VERSION "HNNBNNNYNNNNNNNNNNNNNNNNNNNNNNNNNNNNNNNNNN/4/%%%/4/'%**4NNN///"

NS_ :

BS_:

BU_: BAP_Tester FASFrontradar ICAS1_X_Gateway MFK MFK120 MIK MRR2023 NR_1 NR_2

BO_ 2331595780 NR_FL_Object_09_10: 64 NR_1
 SG_ NR_FL_Object_09_10_CRC : 0|8@1+ (1,0) [0|255] ""  ICAS1_X_Gateway,MRR2023
 SG_ NR_FL_Object_09_10_BZ : 8|4@1+ (1,0) [0|15] ""  ICAS1_X_Gateway,MRR2023
 SG_ NR_FL_Object_09_10_BlockID_01 : 12|4@1+ (1,0) [0|15] "Unit_None"  ICAS1_X_Gateway,MRR2023
 SG_ NR_FL_Object_09_ID : 16|8@1+ (1,0) [1|254] "Unit_None"  ICAS1_X_Gateway,MRR2023
 SG_ NR_FL_Object_09_ReferencePoint : 24|4@1+ (1.0,0.0) [0.0|15] ""  ICAS1_X_Gateway,MRR2023
 SG_ NR_FL_Object_09_PosX : 28|14@1+ (0.03125,-200) [-200.00000|311.93750] "Unit_Meter"  ICAS1_X_Gateway,MRR2023
 SG_ NR_FL_Object_09_PosXSD : 42|8@1+ (0.03125,0) [0.00000|7.93750] "Unit_Meter"  ICAS1_X_Gateway,MRR2023
 SG_ NR_FL_Object_09_PosY : 50|13@1+ (0.03125,-128) [-128.00000|127.93750] "Unit_Meter"  ICAS1_X_Gateway,MRR2023
 SG_ NR_FL_Object_09_PosYSD : 63|8@1+ (0.03125,0) [0.00000|7.93750] "Unit_Meter"  ICAS1_X_Gateway,MRR2023
 SG_ NR_FL_Object_09_vAbsX : 71|12@1+ (0.0625,-128) [-128.0000|127.8750] "Unit_MeterPerSecon"  ICAS1_X_Gateway,MRR2023
 SG_ NR_FL_Object_09_vAbsXSD : 83|6@1+ (0.0625,0) [0.0000|3.8750] "Unit_MeterPerSecon"  ICAS1_X_Gateway,MRR2023
 SG_ NR_FL_Object_09_vAbsY : 89|12@1+ (0.0625,-128) [-128.0000|127.8750] "Unit_MeterPerSecon"  ICAS1_X_Gateway,MRR2023
 SG_ NR_FL_Object_09_vAbsYSD : 101|6@1+ (0.0625,0) [0.0000|3.8750] "Unit_MeterPerSecon"  ICAS1_X_Gateway,MRR2023
 SG_ NR_FL_Object_09_aAbsX : 107|9@1+ (0.0625,-16) [-16.0000|15.8750] "Unit_MeterPerSeconSquar"  ICAS1_X_Gateway,MRR2023
 SG_ NR_FL_Object_09_aAbsXSD : 116|6@1+ (0.0625,0) [0.0000|3.8750] "Unit_MeterPerSeconSquar"  ICAS1_X_Gateway,MRR2023
 SG_ NR_FL_Object_09_aAbsY : 122|9@1+ (0.0625,-16) [-16.0000|15.8750] "Unit_MeterPerSeconSquar"  ICAS1_X_Gateway,MRR2023
 SG_ NR_FL_Object_09_aAbsYSD : 131|6@1+ (0.0625,0) [0.0000|3.8750] "Unit_MeterPerSeconSquar"  ICAS1_X_Gateway,MRR2023
 SG_ NR_FL_Object_09_DynamicState : 137|2@1+ (1.0,0.0) [0.0|3] ""  ICAS1_X_Gateway,MRR2023
 SG_ NR_FL_Object_09_YawAngle : 139|12@1+ (0.001953125,-4) [-4.000000000|3.996093750] "Unit_Radia"  ICAS1_X_Gateway,MRR2023
 SG_ NR_FL_Object_09_YawAngleSD : 151|9@1+ (0.001953125,0) [0E-9|0.996093750] "Unit_Radia"  ICAS1_X_Gateway,MRR2023
 SG_ NR_FL_Object_09_Width : 160|8@1+ (0.03125,0) [0.00000|7.93750] "Unit_Meter"  ICAS1_X_Gateway,MRR2023
 SG_ NR_FL_Object_09_WidthSD : 168|7@1+ (0.03125,0) [0.00000|3.93750] "Unit_Meter"  ICAS1_X_Gateway,MRR2023
 SG_ NR_FL_Object_09_Length : 175|10@1+ (0.03125,0) [0.00000|31.93750] "Unit_Meter"  ICAS1_X_Gateway,MRR2023
 SG_ NR_FL_Object_09_LengthSD : 185|7@1+ (0.03125,0) [0.00000|3.93750] "Unit_Meter"  ICAS1_X_Gateway,MRR2023
 SG_ NR_FL_Object_09_Class : 192|4@1+ (1.0,0.0) [0.0|15] ""  ICAS1_X_Gateway,MRR2023
 SG_ NR_FL_Object_09_ClassPlausib : 196|4@1+ (0.0714285714,0) [0E-10|0.9999999996] "Unit_None"  ICAS1_X_Gateway,MRR2023
 SG_ NR_FL_Object_09_ExistProb : 200|7@1+ (0.0078125,0.015625) [0.0156250|1.0000000] "Unit_None"  ICAS1_X_Gateway,MRR2023
 SG_ NR_FL_Object_09_Age : 207|7@1+ (1,0) [0|126] "Unit_None"  ICAS1_X_Gateway,MRR2023
 SG_ NR_FL_Object_09_YawRateAbs : 214|12@1+ (0.001953125,-4) [-4.000000000|3.996093750] "Unit_RadiaPerSecon"  ICAS1_X_Gateway,MRR2023
 SG_ NR_FL_Object_09_YawRateAbsSD : 226|6@1+ (0.003906,0) [0.000000|0.242172] "Unit_RadiaPerSecon"  ICAS1_X_Gateway,MRR2023
 SG_ NR_FL_Object_09_MeasurementState : 232|1@1+ (1.0,0.0) [0.0|1] ""  ICAS1_X_Gateway,MRR2023
 SG_ NR_FL_Object_10_ID : 233|8@1+ (1,0) [1|254] "Unit_None"  ICAS1_X_Gateway,MRR2023
 SG_ NR_FL_Object_10_ReferencePoint : 241|4@1+ (1.0,0.0) [0.0|15] ""  ICAS1_X_Gateway,MRR2023
 SG_ NR_FL_Object_10_PosX : 245|14@1+ (0.03125,-200) [-200.00000|311.93750] "Unit_Meter"  ICAS1_X_Gateway,MRR2023
 SG_ NR_FL_Object_10_PosXSD : 259|8@1+ (0.03125,0) [0.00000|7.93750] "Unit_Meter"  ICAS1_X_Gateway,MRR2023
 SG_ NR_FL_Object_10_PosY : 267|13@1+ (0.03125,-128) [-128.00000|127.93750] "Unit_Meter"  ICAS1_X_Gateway,MRR2023
 SG_ NR_FL_Object_10_PosYSD : 280|8@1+ (0.03125,0) [0.00000|7.93750] "Unit_Meter"  ICAS1_X_Gateway,MRR2023
 SG_ NR_FL_Object_10_vAbsX : 288|12@1+ (0.0625,-128) [-128.0000|127.8750] "Unit_MeterPerSecon"  ICAS1_X_Gateway,MRR2023
 SG_ NR_FL_Object_10_vAbsXSD : 300|6@1+ (0.0625,0) [0.0000|3.8750] "Unit_MeterPerSecon"  ICAS1_X_Gateway,MRR2023
 SG_ NR_FL_Object_10_vAbsY : 306|12@1+ (0.0625,-128) [-128.0000|127.8750] "Unit_MeterPerSecon"  ICAS1_X_Gateway,MRR2023
 SG_ NR_FL_Object_10_vAbsYSD : 318|6@1+ (0.0625,0) [0.0000|3.8750] "Unit_MeterPerSecon"  ICAS1_X_Gateway,MRR2023
 SG_ NR_FL_Object_10_aAbsX : 324|9@1+ (0.0625,-16) [-16.0000|15.8750] "Unit_MeterPerSeconSquar"  ICAS1_X_Gateway,MRR2023
 SG_ NR_FL_Object_10_aAbsXSD : 333|6@1+ (0.0625,0) [0.0000|3.8750] "Unit_MeterPerSeconSquar"  ICAS1_X_Gateway,MRR2023
 SG_ NR_FL_Object_10_aAbsY : 339|9@1+ (0.0625,-16) [-16.0000|15.8750] "Unit_MeterPerSeconSquar"  ICAS1_X_Gateway,MRR2023
 SG_ NR_FL_Object_10_aAbsYSD : 348|6@1+ (0.0625,0) [0.0000|3.8750] "Unit_MeterPerSeconSquar"  ICAS1_X_Gateway,MRR2023
 SG_ NR_FL_Object_10_DynamicState : 354|2@1+ (1.0,0.0) [0.0|3] ""  ICAS1_X_Gateway,MRR2023
 SG_ NR_FL_Object_10_YawAngle : 356|12@1+ (0.001953125,-4) [-4.000000000|3.996093750] "Unit_Radia"  ICAS1_X_Gateway,MRR2023
 SG_ NR_FL_Object_10_YawAngleSD : 368|9@1+ (0.001953125,0) [0E-9|0.996093750] "Unit_Radia"  ICAS1_X_Gateway,MRR2023
 SG_ NR_FL_Object_10_Width : 377|8@1+ (0.03125,0) [0.00000|7.93750] "Unit_Meter"  ICAS1_X_Gateway,MRR2023
 SG_ NR_FL_Object_10_WidthSD : 385|7@1+ (0.03125,0) [0.00000|3.93750] "Unit_Meter"  ICAS1_X_Gateway,MRR2023
 SG_ NR_FL_Object_10_Length : 392|10@1+ (0.03125,0) [0.00000|31.93750] "Unit_Meter"  ICAS1_X_Gateway,MRR2023
 SG_ NR_FL_Object_10_LengthSD : 402|7@1+ (0.03125,0) [0.00000|3.93750] "Unit_Meter"  ICAS1_X_Gateway,MRR2023
 SG_ NR_FL_Object_10_Class : 409|4@1+ (1.0,0.0) [0.0|15] ""  ICAS1_X_Gateway,MRR2023
 SG_ NR_FL_Object_10_ClassPlausib : 413|4@1+ (0.0714285714,0) [0E-10|0.9999999996] "Unit_None"  ICAS1_X_Gateway,MRR2023
 SG_ NR_FL_Object_10_ExistProb : 417|7@1+ (0.0078125,0.015625) [0.0156250|1.0000000] "Unit_None"  ICAS1_X_Gateway,MRR2023
 SG_ NR_FL_Object_10_Age : 424|7@1+ (1,0) [0|126] "Unit_None"  ICAS1_X_Gateway,MRR2023
 SG_ NR_FL_Object_10_YawRateAbs : 431|12@1+ (0.001953125,-4) [-4.000000000|3.996093750] "Unit_RadiaPerSecon"  ICAS1_X_Gateway,MRR2023
 SG_ NR_FL_Object_10_YawRateAbsSD : 443|6@1+ (0.003906,0) [0.000000|0.242172] "Unit_RadiaPerSecon"  ICAS1_X_Gateway,MRR2023
 SG_ NR_FL_Object_10_MeasurementState : 449|1@1+ (1.0,0.0) [0.0|1] ""  ICAS1_X_Gateway,MRR2023
 SG_ SOK_NR_FL_Object_09_10_Signatur : 480|32@1+ (1,0) [0|4294967295] ""  ICAS1_X_Gateway

BO_ 2589284096 NR_FL_SensorHeader: 24 NR_1
 SG_ NR_FL_HW_Version : 12|32@1+ (1,0) [0|4294967295] "Unit_None"  ICAS1_X_Gateway,MRR2023
 SG_ NR_FL_SW_Version : 44|32@1+ (1,0) [0|4294967295] "Unit_None"  ICAS1_X_Gateway,MRR2023
 SG_ NR_FL_SerialNumber : 76|32@1+ (1,0) [0|4294967295] "Unit_None"  ICAS1_X_Gateway,MRR2023
 SG_ DS_FL_StructureVersion_1 : 108|32@1+ (1,0) [0|4294967295] "Unit_None"  ICAS1_X_Gateway
 SG_ DS_FL_StructureVersion_2 : 140|32@1+ (1,0) [0|4294967295] "Unit_None"  ICAS1_X_Gateway

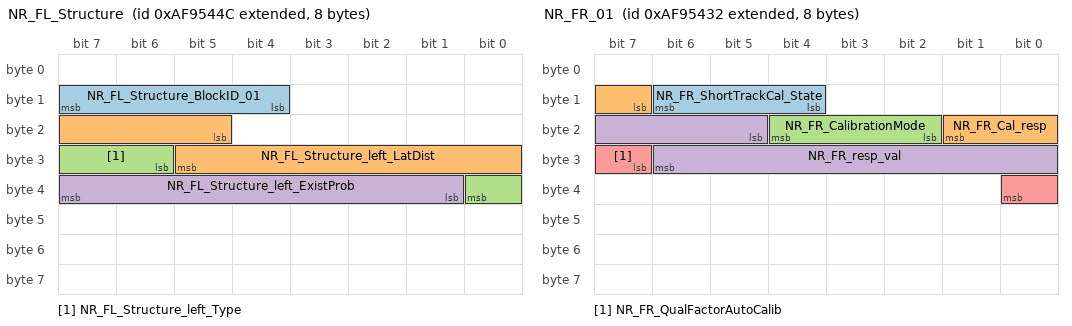
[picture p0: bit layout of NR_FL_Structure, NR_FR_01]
BO_ 2331595852 NR_FL_Structure: 8 NR_1
 SG_ NR_FL_Structure_BlockID_01 : 12|4@1+ (1,0) [0|15] "Unit_None"  ICAS1_X_Gateway,MRR2023
 SG_ NR_FL_Structure_left_LatDist : 21|9@1+ (0.03125,0) [0.00000|15.93750] "Unit_Meter"  ICAS1_X_Gateway,MRR2023
 SG_ NR_FL_Structure_left_Type : 30|3@1+ (1.0,0.0) [0.0|7] ""  ICAS1_X_Gateway,MRR2023
 SG_ NR_FL_Structure_left_ExistProb : 33|7@1+ (0.0078125,0.015625) [0.0156250|1.0000000] "Unit_None"  ICAS1_X_Gateway,MRR2023

BO_ 2264486976 NR_FL_Sync: 8 NR_1
 SG_ NR_FL_SyncCounter : 12|16@1+ (1,0) [0|65535] "Unit_None"  ICAS1_X_Gateway,MRR2023
 SG_ NR_FL_SyncVersion : 28|8@1+ (1,0) [0|255] "Unit_None"  ICAS1_X_Gateway,MRR2023

BO_ 2264486980 NR_FL_Sync_FollowUp: 20 NR_1
 SG_ NR_FL_CounterValue : 12|16@1+ (1,0) [0|65535] "Unit_None"  ICAS1_X_Gateway,MRR2023
 SG_ NR_FL_Time_LowPrecision : 28|32@1+ (1,0) [0|4294967295] "Unit_None"  ICAS1_X_Gateway,MRR2023
 SG_ NR_FL_Time_HighPrecision : 60|32@1+ (1,0) [0|4294967295] "Unit_None"  ICAS1_X_Gateway,MRR2023
 SG_ NR_FL_Time_CorrectionField : 92|32@1+ (1,0) [0|4294967295] "Unit_None"  ICAS1_X_Gateway,MRR2023
 SG_ NR_FL_RandomSeed : 124|16@1+ (1,0) [0|65535] "Unit_None"  ICAS1_X_Gateway,MRR2023

BO_ 2264486985 NR_FL_SyncReady: 16 NR_1
 SG_ NR_FL_SyncReadyVersion : 12|8@1+ (1,0) [0|255] "Unit_None"  ICAS1_X_Gateway,MRR2023
 SG_ NR_FL_EarliestStartTime : 20|32@1+ (1,0) [0|4294967295] "Unit_None"  ICAS1_X_Gateway,MRR2023
 SG_ NR_FL_RequestedModulation : 52|4@1+ (1,0) [0|15] "Unit_None"  ICAS1_X_Gateway,MRR2023
 SG_ NR_FL_InteferenceInfo : 56|16@1+ (1,0) [0|65535] "Unit_None"  ICAS1_X_Gateway,MRR2023
 SG_ NR_FL_SyncCycleCount : 74|32@1+ (1,0) [0|4294967295] "Unit_None"  ICAS1_X_Gateway,MRR2023
 SG_ NR_FL_LatestSyncCounter : 106|4@1+ (1,0) [0|15] "Unit_None"  ICAS1_X_Gateway,MRR2023

BO_ 2331595826 NR_FR_01: 8 NR_2
 SG_ NR_FR_ShortTrackCal_State : 12|3@1+ (1.0,0.0) [0.0|7] ""  ICAS1_X_Gateway,MRR2023
 SG_ NR_FR_Cal_resp : 15|3@1+ (1.0,0.0) [0.0|7] ""  ICAS1_X_Gateway,MRR2023
 SG_ NR_FR_CalibrationMode : 18|3@1+ (1.0,0.0) [0.0|7] ""  ICAS1_X_Gateway,MRR2023
 SG_ NR_FR_resp_val : 21|10@1+ (0.01,-5) [-5.00|5.00] "Unit_DegreOfArc"  ICAS1_X_Gateway,MRR2023
 SG_ NR_FR_QualFactorAutoCalib : 31|2@1+ (1.0,0.0) [0.0|3] ""  ICAS1_X_Gateway,MRR2023

BO_ 2331595791 NR_FR_Contour: 64 NR_2
 SG_ NR_FR_Contour_CRC : 0|8@1+ (1,0) [0|255] ""  ICAS1_X_Gateway,MRR2023
 SG_ NR_FR_Contour_BZ : 8|4@1+ (1,0) [0|15] ""  ICAS1_X_Gateway,MRR2023
 SG_ NR_FR_Contour_BlockID_02 : 12|4@1+ (1,0) [0|15] "Unit_None"  ICAS1_X_Gateway,MRR2023
 SG_ NR_FR_Contour_right_01_x01 : 16|13@1+ (0.0625,-256) [-256.0000|255.8750] "Unit_Meter"  ICAS1_X_Gateway,MRR2023
 SG_ NR_FR_Contour_right_01_y01 : 29|11@1+ (0.0625,-64) [-64.0000|63.8750] "Unit_Meter"  ICAS1_X_Gateway,MRR2023
 SG_ NR_FR_Contour_right_01_x02 : 40|13@1+ (0.0625,-256) [-256.0000|255.8750] "Unit_Meter"  ICAS1_X_Gateway,MRR2023
 SG_ NR_FR_Contour_right_01_y02 : 53|11@1+ (0.0625,-64) [-64.0000|63.8750] "Unit_Meter"  ICAS1_X_Gateway,MRR2023
 SG_ NR_FR_Contour_right_01_x03 : 64|13@1+ (0.0625,-256) [-256.0000|255.8750] "Unit_Meter"  ICAS1_X_Gateway,MRR2023
 SG_ NR_FR_Contour_right_01_y03 : 77|11@1+ (0.0625,-64) [-64.0000|63.8750] "Unit_Meter"  ICAS1_X_Gateway,MRR2023
 SG_ NR_FR_Contour_right_01_x04 : 88|13@1+ (0.0625,-256) [-256.0000|255.8750] "Unit_Meter"  ICAS1_X_Gateway,MRR2023
 SG_ NR_FR_Contour_right_01_y04 : 101|11@1+ (0.0625,-64) [-64.0000|63.8750] "Unit_Meter"  ICAS1_X_Gateway,MRR2023
 SG_ NR_FR_Contour_right_01_x05 : 112|13@1+ (0.0625,-256) [-256.0000|255.8750] "Unit_Meter"  ICAS1_X_Gateway,MRR2023
 SG_ NR_FR_Contour_right_01_y05 : 125|11@1+ (0.0625,-64) [-64.0000|63.8750] "Unit_Meter"  ICAS1_X_Gateway,MRR2023
 SG_ NR_FR_Contour_right_01_x06 : 136|13@1+ (0.0625,-256) [-256.0000|255.8750] "Unit_Meter"  ICAS1_X_Gateway,MRR2023
 SG_ NR_FR_Contour_right_01_y06 : 149|11@1+ (0.0625,-64) [-64.0000|63.8750] "Unit_Meter"  ICAS1_X_Gateway,MRR2023
 SG_ NR_FR_Contour_right_01_x07 : 160|13@1+ (0.0625,-256) [-256.0000|255.8750] "Unit_Meter"  ICAS1_X_Gateway,MRR2023
 SG_ NR_FR_Contour_right_01_y07 : 173|11@1+ (0.0625,-64) [-64.0000|63.8750] "Unit_Meter"  ICAS1_X_Gateway,MRR2023
 SG_ NR_FR_Contour_right_01_Type : 184|3@1+ (1.0,0.0) [0.0|7] ""  ICAS1_X_Gateway,MRR2023
 SG_ NR_FR_Contour_right_01_Age : 187|7@1+ (1,0) [0|126] "Unit_None"  ICAS1_X_Gateway,MRR2023
 SG_ NR_FR_Contour_right_02_x01 : 194|13@1+ (0.0625,-256) [-256.0000|255.8750] "Unit_Meter"  ICAS1_X_Gateway,MRR2023
 SG_ NR_FR_Contour_right_02_y01 : 207|11@1+ (0.0625,-64) [-64.0000|63.8750] "Unit_Meter"  ICAS1_X_Gateway,MRR2023
 SG_ NR_FR_Contour_right_02_x02 : 218|13@1+ (0.0625,-256) [-256.0000|255.8750] "Unit_Meter"  ICAS1_X_Gateway,MRR2023
 SG_ NR_FR_Contour_right_02_y02 : 231|11@1+ (0.0625,-64) [-64.0000|63.8750] "Unit_Meter"  ICAS1_X_Gateway,MRR2023
 SG_ NR_FR_Contour_right_02_x03 : 242|13@1+ (0.0625,-256) [-256.0000|255.8750] "Unit_Meter"  ICAS1_X_Gateway,MRR2023
 SG_ NR_FR_Contour_right_02_y03 : 255|11@1+ (0.0625,-64) [-64.0000|63.8750] "Unit_Meter"  ICAS1_X_Gateway,MRR2023
 SG_ NR_FR_Contour_right_02_x04 : 266|13@1+ (0.0625,-256) [-256.0000|255.8750] "Unit_Meter"  ICAS1_X_Gateway,MRR2023
 SG_ NR_FR_Contour_right_02_y04 : 279|11@1+ (0.0625,-64) [-64.0000|63.8750] "Unit_Meter"  ICAS1_X_Gateway,MRR2023
 SG_ NR_FR_Contour_right_02_x05 : 290|13@1+ (0.0625,-256) [-256.0000|255.8750] "Unit_Meter"  ICAS1_X_Gateway,MRR2023
 SG_ NR_FR_Contour_right_02_y05 : 303|11@1+ (0.0625,-64) [-64.0000|63.8750] "Unit_Meter"  ICAS1_X_Gateway,MRR2023
 SG_ NR_FR_Contour_right_02_x06 : 314|13@1+ (0.0625,-256) [-256.0000|255.8750] "Unit_Meter"  ICAS1_X_Gateway,MRR2023
 SG_ NR_FR_Contour_right_02_y06 : 327|11@1+ (0.0625,-64) [-64.0000|63.8750] "Unit_Meter"  ICAS1_X_Gateway,MRR2023
 SG_ NR_FR_Contour_right_02_x07 : 338|13@1+ (0.0625,-256) [-256.0000|255.8750] "Unit_Meter"  ICAS1_X_Gateway,MRR2023
 SG_ NR_FR_Contour_right_02_y07 : 351|11@1+ (0.0625,-64) [-64.0000|63.8750] "Unit_Meter"  ICAS1_X_Gateway,MRR2023
 SG_ NR_FR_Contour_right_02_Type : 362|3@1+ (1.0,0.0) [0.0|7] ""  ICAS1_X_Gateway,MRR2023
 SG_ NR_FR_Contour_right_02_Age : 365|7@1+ (1,0) [0|126] "Unit_None"  ICAS1_X_Gateway,MRR2023
 SG_ NR_FR_Contour_right_Linkage : 372|1@1+ (1.0,0.0) [0.0|1] ""  ICAS1_X_Gateway,MRR2023
 SG_ SOK_NR_FR_Contour_Signatur : 480|32@1+ (1,0) [0|4294967295] ""  ICAS1_X_Gateway

BO_ 2331595782 NR_FR_Header: 20 NR_2
 SG_ NR_FR_Header_CRC : 0|8@1+ (1,0) [0|255] ""  ICAS1_X_Gateway,MRR2023
 SG_ NR_FR_Header_BZ : 8|4@1+ (1,0) [0|15] ""  ICAS1_X_Gateway,MRR2023
 SG_ NR_FR_BlockID_02 : 12|4@1+ (1,0) [0|15] "Unit_None"  ICAS1_X_Gateway,MRR2023
 SG_ NR_FR_NotAvailable : 16|1@1+ (1.0,0.0) [0.0|1] ""  ICAS1_X_Gateway,MRR2023
 SG_ NR_FR_Failure : 17|1@1+ (1.0,0.0) [0.0|1] ""  ICAS1_X_Gateway,MRR2023
 SG_ NR_FR_Blindness : 18|1@1+ (1.0,0.0) [0.0|1] ""  ICAS1_X_Gateway,MRR2023
 SG_ NR_FR_CalibrationState : 19|3@1+ (1.0,0.0) [0.0|7] ""  ICAS1_X_Gateway,MRR2023
 SG_ NR_FR_Freesight_NOK : 22|1@1+ (1.0,0.0) [0.0|1] ""  ICAS1_X_Gateway,MRR2023
 SG_ NR_FR_MeasurementTimeLow : 30|32@1+ (1,0) [0|999999999] "Unit_NanoSecon"  ICAS1_X_Gateway,MRR2023
 SG_ NR_FR_MeasurementTimeHigh : 62|32@1+ (1,0) [0|4294967293] "Unit_Secon"  ICAS1_X_Gateway,MRR2023
 SG_ NR_FR_RangeDegradation_Sect1 : 94|3@1+ (1.0,0.0) [0.0|7] ""  ICAS1_X_Gateway,MRR2023
 SG_ NR_FR_RangeDegradation_Sect2 : 97|3@1+ (1.0,0.0) [0.0|7] ""  ICAS1_X_Gateway,MRR2023
 SG_ NR_FR_RangeDegradation_Sect3 : 100|3@1+ (1.0,0.0) [0.0|7] ""  ICAS1_X_Gateway,MRR2023
 SG_ NR_FR_MeasurementTimeLapNumber : 103|14@1+ (1,0) [0|16381] "Unit_None"  ICAS1_X_Gateway,MRR2023
 SG_ NR_FR_MeasurementTimeStatus : 117|2@1+ (1.0,0.0) [0.0|3] ""  ICAS1_X_Gateway,MRR2023
 SG_ SOK_NR_FR_Header_Signatur : 128|32@1+ (1,0) [0|4294967295] ""  ICAS1_X_Gateway

BO_ 2331595785 NR_FR_Object_01_02: 64 NR_2
 SG_ NR_FR_Object_01_02_CRC : 0|8@1+ (1,0) [0|255] ""  ICAS1_X_Gateway,MRR2023
 SG_ NR_FR_Object_01_02_BZ : 8|4@1+ (1,0) [0|15] ""  ICAS1_X_Gateway,MRR2023
 SG_ NR_FR_Object_01_02_BlockID_02 : 12|4@1+ (1,0) [0|15] "Unit_None"  ICAS1_X_Gateway,MRR2023
 SG_ NR_FR_Object_01_ID : 16|8@1+ (1,0) [1|254] "Unit_None"  ICAS1_X_Gateway,MRR2023
 SG_ NR_FR_Object_01_ReferencePoint : 24|4@1+ (1.0,0.0) [0.0|15] ""  ICAS1_X_Gateway,MRR2023
 SG_ NR_FR_Object_01_PosX : 28|14@1+ (0.03125,-200) [-200.00000|311.93750] "Unit_Meter"  ICAS1_X_Gateway,MRR2023
 SG_ NR_FR_Object_01_PosXSD : 42|8@1+ (0.03125,0) [0.00000|7.93750] "Unit_Meter"  ICAS1_X_Gateway,MRR2023
 SG_ NR_FR_Object_01_PosY : 50|13@1+ (0.03125,-128) [-128.00000|127.93750] "Unit_Meter"  ICAS1_X_Gateway,MRR2023
 SG_ NR_FR_Object_01_PosYSD : 63|8@1+ (0.03125,0) [0.00000|7.93750] "Unit_Meter"  ICAS1_X_Gateway,MRR2023
 SG_ NR_FR_Object_01_vAbsX : 71|12@1+ (0.0625,-128) [-128.0000|127.8750] "Unit_MeterPerSecon"  ICAS1_X_Gateway,MRR2023
 SG_ NR_FR_Object_01_vAbsXSD : 83|6@1+ (0.0625,0) [0.0000|3.8750] "Unit_MeterPerSecon"  ICAS1_X_Gateway,MRR2023
 SG_ NR_FR_Object_01_vAbsY : 89|12@1+ (0.0625,-128) [-128.0000|127.8750] "Unit_MeterPerSecon"  ICAS1_X_Gateway,MRR2023
 SG_ NR_FR_Object_01_vAbsYSD : 101|6@1+ (0.0625,0) [0.0000|3.8750] "Unit_MeterPerSecon"  ICAS1_X_Gateway,MRR2023
 SG_ NR_FR_Object_01_aAbsX : 107|9@1+ (0.0625,-16) [-16.0000|15.8750] "Unit_MeterPerSeconSquar"  ICAS1_X_Gateway,MRR2023
 SG_ NR_FR_Object_01_aAbsXSD : 116|6@1+ (0.0625,0) [0.0000|3.8750] "Unit_MeterPerSeconSquar"  ICAS1_X_Gateway,MRR2023
 SG_ NR_FR_Object_01_aAbsY : 122|9@1+ (0.0625,-16) [-16.0000|15.8750] "Unit_MeterPerSeconSquar"  ICAS1_X_Gateway,MRR2023
 SG_ NR_FR_Object_01_aAbsYSD : 131|6@1+ (0.0625,0) [0.0000|3.8750] "Unit_MeterPerSeconSquar"  ICAS1_X_Gateway,MRR2023
 SG_ NR_FR_Object_01_DynamicState : 137|2@1+ (1.0,0.0) [0.0|3] ""  ICAS1_X_Gateway,MRR2023
 SG_ NR_FR_Object_01_YawAngle : 139|12@1+ (0.001953125,-4) [-4.000000000|3.996093750] "Unit_Radia"  ICAS1_X_Gateway,MRR2023
 SG_ NR_FR_Object_01_YawAngleSD : 151|9@1+ (0.001953125,0) [0E-9|0.996093750] "Unit_Radia"  ICAS1_X_Gateway,MRR2023
 SG_ NR_FR_Object_01_Width : 160|8@1+ (0.03125,0) [0.00000|7.93750] "Unit_Meter"  ICAS1_X_Gateway,MRR2023
 SG_ NR_FR_Object_01_WidthSD : 168|7@1+ (0.03125,0) [0.00000|3.93750] "Unit_Meter"  ICAS1_X_Gateway,MRR2023
 SG_ NR_FR_Object_01_Length : 175|10@1+ (0.03125,0) [0.00000|31.93750] "Unit_Meter"  ICAS1_X_Gateway,MRR2023
 SG_ NR_FR_Object_01_LengthSD : 185|7@1+ (0.03125,0) [0.00000|3.93750] "Unit_Meter"  ICAS1_X_Gateway,MRR2023
 SG_ NR_FR_Object_01_Class : 192|4@1+ (1.0,0.0) [0.0|15] ""  ICAS1_X_Gateway,MRR2023
 SG_ NR_FR_Object_01_ClassPlausib : 196|4@1+ (0.0714285714,0) [0E-10|0.9999999996] "Unit_None"  ICAS1_X_Gateway,MRR2023
 SG_ NR_FR_Object_01_ExistProb : 200|7@1+ (0.0078125,0.015625) [0.0156250|1.0000000] "Unit_None"  ICAS1_X_Gateway,MRR2023
 SG_ NR_FR_Object_01_Age : 207|7@1+ (1,0) [0|126] "Unit_None"  ICAS1_X_Gateway,MRR2023
 SG_ NR_FR_Object_01_YawRateAbs : 214|12@1+ (0.001953125,-4) [-4.000000000|3.996093750] "Unit_RadiaPerSecon"  ICAS1_X_Gateway,MRR2023
 SG_ NR_FR_Object_01_YawRateAbsSD : 226|6@1+ (0.003906,0) [0.000000|0.242172] "Unit_RadiaPerSecon"  ICAS1_X_Gateway,MRR2023
 SG_ NR_FR_Object_01_MeasurementState : 232|1@1+ (1.0,0.0) [0.0|1] ""  ICAS1_X_Gateway,MRR2023
 SG_ NR_FR_Object_02_ID : 233|8@1+ (1,0) [1|254] "Unit_None"  ICAS1_X_Gateway,MRR2023
 SG_ NR_FR_Object_02_ReferencePoint : 241|4@1+ (1.0,0.0) [0.0|15] ""  ICAS1_X_Gateway,MRR2023
 SG_ NR_FR_Object_02_PosX : 245|14@1+ (0.03125,-200) [-200.00000|311.93750] "Unit_Meter"  ICAS1_X_Gateway,MRR2023
 SG_ NR_FR_Object_02_PosXSD : 259|8@1+ (0.03125,0) [0.00000|7.93750] "Unit_Meter"  ICAS1_X_Gateway,MRR2023
 SG_ NR_FR_Object_02_PosY : 267|13@1+ (0.03125,-128) [-128.00000|127.93750] "Unit_Meter"  ICAS1_X_Gateway,MRR2023
 SG_ NR_FR_Object_02_PosYSD : 280|8@1+ (0.03125,0) [0.00000|7.93750] "Unit_Meter"  ICAS1_X_Gateway,MRR2023
 SG_ NR_FR_Object_02_vAbsX : 288|12@1+ (0.0625,-128) [-128.0000|127.8750] "Unit_MeterPerSecon"  ICAS1_X_Gateway,MRR2023
 SG_ NR_FR_Object_02_vAbsXSD : 300|6@1+ (0.0625,0) [0.0000|3.8750] "Unit_MeterPerSecon"  ICAS1_X_Gateway,MRR2023
 SG_ NR_FR_Object_02_vAbsY : 306|12@1+ (0.0625,-128) [-128.0000|127.8750] "Unit_MeterPerSecon"  ICAS1_X_Gateway,MRR2023
 SG_ NR_FR_Object_02_vAbsYSD : 318|6@1+ (0.0625,0) [0.0000|3.8750] "Unit_MeterPerSecon"  ICAS1_X_Gateway,MRR2023
 SG_ NR_FR_Object_02_aAbsX : 324|9@1+ (0.0625,-16) [-16.0000|15.8750] "Unit_MeterPerSeconSquar"  ICAS1_X_Gateway,MRR2023
 SG_ NR_FR_Object_02_aAbsXSD : 333|6@1+ (0.0625,0) [0.0000|3.8750] "Unit_MeterPerSeconSquar"  ICAS1_X_Gateway,MRR2023
 SG_ NR_FR_Object_02_aAbsY : 339|9@1+ (0.0625,-16) [-16.0000|15.8750] "Unit_MeterPerSeconSquar"  ICAS1_X_Gateway,MRR2023
 SG_ NR_FR_Object_02_aAbsYSD : 348|6@1+ (0.0625,0) [0.0000|3.8750] "Unit_MeterPerSeconSquar"  ICAS1_X_Gateway,MRR2023
 SG_ NR_FR_Object_02_DynamicState : 354|2@1+ (1.0,0.0) [0.0|3] ""  ICAS1_X_Gateway,MRR2023
 SG_ NR_FR_Object_02_YawAngle : 356|12@1+ (0.001953125,-4) [-4.000000000|3.996093750] "Unit_Radia"  ICAS1_X_Gateway,MRR2023
 SG_ NR_FR_Object_02_YawAngleSD : 368|9@1+ (0.001953125,0) [0E-9|0.996093750] "Unit_Radia"  ICAS1_X_Gateway,MRR2023
 SG_ NR_FR_Object_02_Width : 377|8@1+ (0.03125,0) [0.00000|7.93750] "Unit_Meter"  ICAS1_X_Gateway,MRR2023
 SG_ NR_FR_Object_02_WidthSD : 385|7@1+ (0.03125,0) [0.00000|3.93750] "Unit_Meter"  ICAS1_X_Gateway,MRR2023
 SG_ NR_FR_Object_02_Length : 392|10@1+ (0.03125,0) [0.00000|31.93750] "Unit_Meter"  ICAS1_X_Gateway,MRR2023
 SG_ NR_FR_Object_02_LengthSD : 402|7@1+ (0.03125,0) [0.00000|3.93750] "Unit_Meter"  ICAS1_X_Gateway,MRR2023
 SG_ NR_FR_Object_02_Class : 409|4@1+ (1.0,0.0) [0.0|15] ""  ICAS1_X_Gateway,MRR2023
 SG_ NR_FR_Object_02_ClassPlausib : 413|4@1+ (0.0714285714,0) [0E-10|0.9999999996] "Unit_None"  ICAS1_X_Gateway,MRR2023
 SG_ NR_FR_Object_02_ExistProb : 417|7@1+ (0.0078125,0.015625) [0.0156250|1.0000000] "Unit_None"  ICAS1_X_Gateway,MRR2023
 SG_ NR_FR_Object_02_Age : 424|7@1+ (1,0) [0|126] "Unit_None"  ICAS1_X_Gateway,MRR2023
 SG_ NR_FR_Object_02_YawRateAbs : 431|12@1+ (0.001953125,-4) [-4.000000000|3.996093750] "Unit_RadiaPerSecon"  ICAS1_X_Gateway,MRR2023
 SG_ NR_FR_Object_02_YawRateAbsSD : 443|6@1+ (0.003906,0) [0.000000|0.242172] "Unit_RadiaPerSecon"  ICAS1_X_Gateway,MRR2023
 SG_ NR_FR_Object_02_MeasurementState : 449|1@1+ (1.0,0.0) [0.0|1] ""  ICAS1_X_Gateway,MRR2023
 SG_ SOK_NR_FR_Object_01_02_Signatur : 480|32@1+ (1,0) [0|4294967295] ""  ICAS1_X_Gateway

BO_ 2331595786 NR_FR_Object_03_04: 64 NR_2
 SG_ NR_FR_Object_03_04_CRC : 0|8@1+ (1,0) [0|255] ""  ICAS1_X_Gateway,MRR2023
 SG_ NR_FR_Object_03_04_BZ : 8|4@1+ (1,0) [0|15] ""  ICAS1_X_Gateway,MRR2023
 SG_ NR_FR_Object_03_04_BlockID_02 : 12|4@1+ (1,0) [0|15] "Unit_None"  ICAS1_X_Gateway,MRR2023
 SG_ NR_FR_Object_03_ID : 16|8@1+ (1,0) [1|254] "Unit_None"  ICAS1_X_Gateway,MRR2023
 SG_ NR_FR_Object_03_ReferencePoint : 24|4@1+ (1.0,0.0) [0.0|15] ""  ICAS1_X_Gateway,MRR2023
 SG_ NR_FR_Object_03_PosX : 28|14@1+ (0.03125,-200) [-200.00000|311.93750] "Unit_Meter"  ICAS1_X_Gateway,MRR2023
 SG_ NR_FR_Object_03_PosXSD : 42|8@1+ (0.03125,0) [0.00000|7.93750] "Unit_Meter"  ICAS1_X_Gateway,MRR2023
 SG_ NR_FR_Object_03_PosY : 50|13@1+ (0.03125,-128) [-128.00000|127.93750] "Unit_Meter"  ICAS1_X_Gateway,MRR2023
 SG_ NR_FR_Object_03_PosYSD : 63|8@1+ (0.03125,0) [0.00000|7.93750] "Unit_Meter"  ICAS1_X_Gateway,MRR2023
 SG_ NR_FR_Object_03_vAbsX : 71|12@1+ (0.0625,-128) [-128.0000|127.8750] "Unit_MeterPerSecon"  ICAS1_X_Gateway,MRR2023
 SG_ NR_FR_Object_03_vAbsXSD : 83|6@1+ (0.0625,0) [0.0000|3.8750] "Unit_MeterPerSecon"  ICAS1_X_Gateway,MRR2023
 SG_ NR_FR_Object_03_vAbsY : 89|12@1+ (0.0625,-128) [-128.0000|127.8750] "Unit_MeterPerSecon"  ICAS1_X_Gateway,MRR2023
 SG_ NR_FR_Object_03_vAbsYSD : 101|6@1+ (0.0625,0) [0.0000|3.8750] "Unit_MeterPerSecon"  ICAS1_X_Gateway,MRR2023
 SG_ NR_FR_Object_03_aAbsX : 107|9@1+ (0.0625,-16) [-16.0000|15.8750] "Unit_MeterPerSeconSquar"  ICAS1_X_Gateway,MRR2023
 SG_ NR_FR_Object_03_aAbsXSD : 116|6@1+ (0.0625,0) [0.0000|3.8750] "Unit_MeterPerSeconSquar"  ICAS1_X_Gateway,MRR2023
 SG_ NR_FR_Object_03_aAbsY : 122|9@1+ (0.0625,-16) [-16.0000|15.8750] "Unit_MeterPerSeconSquar"  ICAS1_X_Gateway,MRR2023
 SG_ NR_FR_Object_03_aAbsYSD : 131|6@1+ (0.0625,0) [0.0000|3.8750] "Unit_MeterPerSeconSquar"  ICAS1_X_Gateway,MRR2023
 SG_ NR_FR_Object_03_DynamicState : 137|2@1+ (1.0,0.0) [0.0|3] ""  ICAS1_X_Gateway,MRR2023
 SG_ NR_FR_Object_03_YawAngle : 139|12@1+ (0.001953125,-4) [-4.000000000|3.996093750] "Unit_Radia"  ICAS1_X_Gateway,MRR2023
 SG_ NR_FR_Object_03_YawAngleSD : 151|9@1+ (0.001953125,0) [0E-9|0.996093750] "Unit_Radia"  ICAS1_X_Gateway,MRR2023
 SG_ NR_FR_Object_03_Width : 160|8@1+ (0.03125,0) [0.00000|7.93750] "Unit_Meter"  ICAS1_X_Gateway,MRR2023
 SG_ NR_FR_Object_03_WidthSD : 168|7@1+ (0.03125,0) [0.00000|3.93750] "Unit_Meter"  ICAS1_X_Gateway,MRR2023
 SG_ NR_FR_Object_03_Length : 175|10@1+ (0.03125,0) [0.00000|31.93750] "Unit_Meter"  ICAS1_X_Gateway,MRR2023
 SG_ NR_FR_Object_03_LengthSD : 185|7@1+ (0.03125,0) [0.00000|3.93750] "Unit_Meter"  ICAS1_X_Gateway,MRR2023
 SG_ NR_FR_Object_03_Class : 192|4@1+ (1.0,0.0) [0.0|15] ""  ICAS1_X_Gateway,MRR2023
 SG_ NR_FR_Object_03_ClassPlausib : 196|4@1+ (0.0714285714,0) [0E-10|0.9999999996] "Unit_None"  ICAS1_X_Gateway,MRR2023
 SG_ NR_FR_Object_03_ExistProb : 200|7@1+ (0.0078125,0.015625) [0.0156250|1.0000000] "Unit_None"  ICAS1_X_Gateway,MRR2023
 SG_ NR_FR_Object_03_Age : 207|7@1+ (1,0) [0|126] "Unit_None"  ICAS1_X_Gateway,MRR2023
 SG_ NR_FR_Object_03_YawRateAbs : 214|12@1+ (0.001953125,-4) [-4.000000000|3.996093750] "Unit_RadiaPerSecon"  ICAS1_X_Gateway,MRR2023
 SG_ NR_FR_Object_03_YawRateAbsSD : 226|6@1+ (0.003906,0) [0.000000|0.242172] "Unit_RadiaPerSecon"  ICAS1_X_Gateway,MRR2023
 SG_ NR_FR_Object_03_MeasurementState : 232|1@1+ (1.0,0.0) [0.0|1] ""  ICAS1_X_Gateway,MRR2023
 SG_ NR_FR_Object_04_ID : 233|8@1+ (1,0) [1|254] "Unit_None"  ICAS1_X_Gateway,MRR2023
 SG_ NR_FR_Object_04_ReferencePoint : 241|4@1+ (1.0,0.0) [0.0|15] ""  ICAS1_X_Gateway,MRR2023
 SG_ NR_FR_Object_04_PosX : 245|14@1+ (0.03125,-200) [-200.00000|311.93750] "Unit_Meter"  ICAS1_X_Gateway,MRR2023
 SG_ NR_FR_Object_04_PosXSD : 259|8@1+ (0.03125,0) [0.00000|7.93750] "Unit_Meter"  ICAS1_X_Gateway,MRR2023
 SG_ NR_FR_Object_04_PosY : 267|13@1+ (0.03125,-128) [-128.00000|127.93750] "Unit_Meter"  ICAS1_X_Gateway,MRR2023
 SG_ NR_FR_Object_04_PosYSD : 280|8@1+ (0.03125,0) [0.00000|7.93750] "Unit_Meter"  ICAS1_X_Gateway,MRR2023
 SG_ NR_FR_Object_04_vAbsX : 288|12@1+ (0.0625,-128) [-128.0000|127.8750] "Unit_MeterPerSecon"  ICAS1_X_Gateway,MRR2023
 SG_ NR_FR_Object_04_vAbsXSD : 300|6@1+ (0.0625,0) [0.0000|3.8750] "Unit_MeterPerSecon"  ICAS1_X_Gateway,MRR2023
 SG_ NR_FR_Object_04_vAbsY : 306|12@1+ (0.0625,-128) [-128.0000|127.8750] "Unit_MeterPerSecon"  ICAS1_X_Gateway,MRR2023
 SG_ NR_FR_Object_04_vAbsYSD : 318|6@1+ (0.0625,0) [0.0000|3.8750] "Unit_MeterPerSecon"  ICAS1_X_Gateway,MRR2023
 SG_ NR_FR_Object_04_aAbsX : 324|9@1+ (0.0625,-16) [-16.0000|15.8750] "Unit_MeterPerSeconSquar"  ICAS1_X_Gateway,MRR2023
 SG_ NR_FR_Object_04_aAbsXSD : 333|6@1+ (0.0625,0) [0.0000|3.8750] "Unit_MeterPerSeconSquar"  ICAS1_X_Gateway,MRR2023
 SG_ NR_FR_Object_04_aAbsY : 339|9@1+ (0.0625,-16) [-16.0000|15.8750] "Unit_MeterPerSeconSquar"  ICAS1_X_Gateway,MRR2023
 SG_ NR_FR_Object_04_aAbsYSD : 348|6@1+ (0.0625,0) [0.0000|3.8750] "Unit_MeterPerSeconSquar"  ICAS1_X_Gateway,MRR2023
 SG_ NR_FR_Object_04_DynamicState : 354|2@1+ (1.0,0.0) [0.0|3] ""  ICAS1_X_Gateway,MRR2023
 SG_ NR_FR_Object_04_YawAngle : 356|12@1+ (0.001953125,-4) [-4.000000000|3.996093750] "Unit_Radia"  ICAS1_X_Gateway,MRR2023
 SG_ NR_FR_Object_04_YawAngleSD : 368|9@1+ (0.001953125,0) [0E-9|0.996093750] "Unit_Radia"  ICAS1_X_Gateway,MRR2023
 SG_ NR_FR_Object_04_Width : 377|8@1+ (0.03125,0) [0.00000|7.93750] "Unit_Meter"  ICAS1_X_Gateway,MRR2023
 SG_ NR_FR_Object_04_WidthSD : 385|7@1+ (0.03125,0) [0.00000|3.93750] "Unit_Meter"  ICAS1_X_Gateway,MRR2023
 SG_ NR_FR_Object_04_Length : 392|10@1+ (0.03125,0) [0.00000|31.93750] "Unit_Meter"  ICAS1_X_Gateway,MRR2023
 SG_ NR_FR_Object_04_LengthSD : 402|7@1+ (0.03125,0) [0.00000|3.93750] "Unit_Meter"  ICAS1_X_Gateway,MRR2023
 SG_ NR_FR_Object_04_Class : 409|4@1+ (1.0,0.0) [0.0|15] ""  ICAS1_X_Gateway,MRR2023
 SG_ NR_FR_Object_04_ClassPlausib : 413|4@1+ (0.0714285714,0) [0E-10|0.9999999996] "Unit_None"  ICAS1_X_Gateway,MRR2023
 SG_ NR_FR_Object_04_ExistProb : 417|7@1+ (0.0078125,0.015625) [0.0156250|1.0000000] "Unit_None"  ICAS1_X_Gateway,MRR2023
 SG_ NR_FR_Object_04_Age : 424|7@1+ (1,0) [0|126] "Unit_None"  ICAS1_X_Gateway,MRR2023
 SG_ NR_FR_Object_04_YawRateAbs : 431|12@1+ (0.001953125,-4) [-4.000000000|3.996093750] "Unit_RadiaPerSecon"  ICAS1_X_Gateway,MRR2023
 SG_ NR_FR_Object_04_YawRateAbsSD : 443|6@1+ (0.003906,0) [0.000000|0.242172] "Unit_RadiaPerSecon"  ICAS1_X_Gateway,MRR2023
 SG_ NR_FR_Object_04_MeasurementState : 449|1@1+ (1.0,0.0) [0.0|1] ""  ICAS1_X_Gateway,MRR2023
 SG_ SOK_NR_FR_Object_03_04_Signatur : 480|32@1+ (1,0) [0|4294967295] ""  ICAS1_X_Gateway

BO_ 2331595787 NR_FR_Object_05_06: 64 NR_2
 SG_ NR_FR_Object_05_06_CRC : 0|8@1+ (1,0) [0|255] ""  ICAS1_X_Gateway,MRR2023
 SG_ NR_FR_Object_05_06_BZ : 8|4@1+ (1,0) [0|15] ""  ICAS1_X_Gateway,MRR2023
 SG_ NR_FR_Object_05_06_BlockID_02 : 12|4@1+ (1,0) [0|15] "Unit_None"  ICAS1_X_Gateway,MRR2023
 SG_ NR_FR_Object_05_ID : 16|8@1+ (1,0) [1|254] "Unit_None"  ICAS1_X_Gateway,MRR2023
 SG_ NR_FR_Object_05_ReferencePoint : 24|4@1+ (1.0,0.0) [0.0|15] ""  ICAS1_X_Gateway,MRR2023
 SG_ NR_FR_Object_05_PosX : 28|14@1+ (0.03125,-200) [-200.00000|311.93750] "Unit_Meter"  ICAS1_X_Gateway,MRR2023
 SG_ NR_FR_Object_05_PosXSD : 42|8@1+ (0.03125,0) [0.00000|7.93750] "Unit_Meter"  ICAS1_X_Gateway,MRR2023
 SG_ NR_FR_Object_05_PosY : 50|13@1+ (0.03125,-128) [-128.00000|127.93750] "Unit_Meter"  ICAS1_X_Gateway,MRR2023
 SG_ NR_FR_Object_05_PosYSD : 63|8@1+ (0.03125,0) [0.00000|7.93750] "Unit_Meter"  ICAS1_X_Gateway,MRR2023
 SG_ NR_FR_Object_05_vAbsX : 71|12@1+ (0.0625,-128) [-128.0000|127.8750] "Unit_MeterPerSecon"  ICAS1_X_Gateway,MRR2023
 SG_ NR_FR_Object_05_vAbsXSD : 83|6@1+ (0.0625,0) [0.0000|3.8750] "Unit_MeterPerSecon"  ICAS1_X_Gateway,MRR2023
 SG_ NR_FR_Object_05_vAbsY : 89|12@1+ (0.0625,-128) [-128.0000|127.8750] "Unit_MeterPerSecon"  ICAS1_X_Gateway,MRR2023
 SG_ NR_FR_Object_05_vAbsYSD : 101|6@1+ (0.0625,0) [0.0000|3.8750] "Unit_MeterPerSecon"  ICAS1_X_Gateway,MRR2023
 SG_ NR_FR_Object_05_aAbsX : 107|9@1+ (0.0625,-16) [-16.0000|15.8750] "Unit_MeterPerSeconSquar"  ICAS1_X_Gateway,MRR2023
 SG_ NR_FR_Object_05_aAbsXSD : 116|6@1+ (0.0625,0) [0.0000|3.8750] "Unit_MeterPerSeconSquar"  ICAS1_X_Gateway,MRR2023
 SG_ NR_FR_Object_05_aAbsY : 122|9@1+ (0.0625,-16) [-16.0000|15.8750] "Unit_MeterPerSeconSquar"  ICAS1_X_Gateway,MRR2023
 SG_ NR_FR_Object_05_aAbsYSD : 131|6@1+ (0.0625,0) [0.0000|3.8750] "Unit_MeterPerSeconSquar"  ICAS1_X_Gateway,MRR2023
 SG_ NR_FR_Object_05_DynamicState : 137|2@1+ (1.0,0.0) [0.0|3] ""  ICAS1_X_Gateway,MRR2023
 SG_ NR_FR_Object_05_YawAngle : 139|12@1+ (0.001953125,-4) [-4.000000000|3.996093750] "Unit_Radia"  ICAS1_X_Gateway,MRR2023
 SG_ NR_FR_Object_05_YawAngleSD : 151|9@1+ (0.001953125,0) [0E-9|0.996093750] "Unit_Radia"  ICAS1_X_Gateway,MRR2023
 SG_ NR_FR_Object_05_Width : 160|8@1+ (0.03125,0) [0.00000|7.93750] "Unit_Meter"  ICAS1_X_Gateway,MRR2023
 SG_ NR_FR_Object_05_WidthSD : 168|7@1+ (0.03125,0) [0.00000|3.93750] "Unit_Meter"  ICAS1_X_Gateway,MRR2023
 SG_ NR_FR_Object_05_Length : 175|10@1+ (0.03125,0) [0.00000|31.93750] "Unit_Meter"  ICAS1_X_Gateway,MRR2023
 SG_ NR_FR_Object_05_LengthSD : 185|7@1+ (0.03125,0) [0.00000|3.93750] "Unit_Meter"  ICAS1_X_Gateway,MRR2023
 SG_ NR_FR_Object_05_Class : 192|4@1+ (1.0,0.0) [0.0|15] ""  ICAS1_X_Gateway,MRR2023
 SG_ NR_FR_Object_05_ClassPlausib : 196|4@1+ (0.0714285714,0) [0E-10|0.9999999996] "Unit_None"  ICAS1_X_Gateway,MRR2023
 SG_ NR_FR_Object_05_ExistProb : 200|7@1+ (0.0078125,0.015625) [0.0156250|1.0000000] "Unit_None"  ICAS1_X_Gateway,MRR2023
 SG_ NR_FR_Object_05_Age : 207|7@1+ (1,0) [0|126] "Unit_None"  ICAS1_X_Gateway,MRR2023
 SG_ NR_FR_Object_05_YawRateAbs : 214|12@1+ (0.001953125,-4) [-4.000000000|3.996093750] "Unit_RadiaPerSecon"  ICAS1_X_Gateway,MRR2023
 SG_ NR_FR_Object_05_YawRateAbsSD : 226|6@1+ (0.003906,0) [0.000000|0.242172] "Unit_RadiaPerSecon"  ICAS1_X_Gateway,MRR2023
 SG_ NR_FR_Object_05_MeasurementState : 232|1@1+ (1.0,0.0) [0.0|1] ""  ICAS1_X_Gateway,MRR2023
 SG_ NR_FR_Object_06_ID : 233|8@1+ (1,0) [1|254] "Unit_None"  ICAS1_X_Gateway,MRR2023
 SG_ NR_FR_Object_06_ReferencePoint : 241|4@1+ (1.0,0.0) [0.0|15] ""  ICAS1_X_Gateway,MRR2023
 SG_ NR_FR_Object_06_PosX : 245|14@1+ (0.03125,-200) [-200.00000|311.93750] "Unit_Meter"  ICAS1_X_Gateway,MRR2023
 SG_ NR_FR_Object_06_PosXSD : 259|8@1+ (0.03125,0) [0.00000|7.93750] "Unit_Meter"  ICAS1_X_Gateway,MRR2023
 SG_ NR_FR_Object_06_PosY : 267|13@1+ (0.03125,-128) [-128.00000|127.93750] "Unit_Meter"  ICAS1_X_Gateway,MRR2023
 SG_ NR_FR_Object_06_PosYSD : 280|8@1+ (0.03125,0) [0.00000|7.93750] "Unit_Meter"  ICAS1_X_Gateway,MRR2023
 SG_ NR_FR_Object_06_vAbsX : 288|12@1+ (0.0625,-128) [-128.0000|127.8750] "Unit_MeterPerSecon"  ICAS1_X_Gateway,MRR2023
 SG_ NR_FR_Object_06_vAbsXSD : 300|6@1+ (0.0625,0) [0.0000|3.8750] "Unit_MeterPerSecon"  ICAS1_X_Gateway,MRR2023
 SG_ NR_FR_Object_06_vAbsY : 306|12@1+ (0.0625,-128) [-128.0000|127.8750] "Unit_MeterPerSecon"  ICAS1_X_Gateway,MRR2023
 SG_ NR_FR_Object_06_vAbsYSD : 318|6@1+ (0.0625,0) [0.0000|3.8750] "Unit_MeterPerSecon"  ICAS1_X_Gateway,MRR2023
 SG_ NR_FR_Object_06_aAbsX : 324|9@1+ (0.0625,-16) [-16.0000|15.8750] "Unit_MeterPerSeconSquar"  ICAS1_X_Gateway,MRR2023
 SG_ NR_FR_Object_06_aAbsXSD : 333|6@1+ (0.0625,0) [0.0000|3.8750] "Unit_MeterPerSeconSquar"  ICAS1_X_Gateway,MRR2023
 SG_ NR_FR_Object_06_aAbsY : 339|9@1+ (0.0625,-16) [-16.0000|15.8750] "Unit_MeterPerSeconSquar"  ICAS1_X_Gateway,MRR2023
 SG_ NR_FR_Object_06_aAbsYSD : 348|6@1+ (0.0625,0) [0.0000|3.8750] "Unit_MeterPerSeconSquar"  ICAS1_X_Gateway,MRR2023
 SG_ NR_FR_Object_06_DynamicState : 354|2@1+ (1.0,0.0) [0.0|3] ""  ICAS1_X_Gateway,MRR2023
 SG_ NR_FR_Object_06_YawAngle : 356|12@1+ (0.001953125,-4) [-4.000000000|3.996093750] "Unit_Radia"  ICAS1_X_Gateway,MRR2023
 SG_ NR_FR_Object_06_YawAngleSD : 368|9@1+ (0.001953125,0) [0E-9|0.996093750] "Unit_Radia"  ICAS1_X_Gateway,MRR2023
 SG_ NR_FR_Object_06_Width : 377|8@1+ (0.03125,0) [0.00000|7.93750] "Unit_Meter"  ICAS1_X_Gateway,MRR2023
 SG_ NR_FR_Object_06_WidthSD : 385|7@1+ (0.03125,0) [0.00000|3.93750] "Unit_Meter"  ICAS1_X_Gateway,MRR2023
 SG_ NR_FR_Object_06_Length : 392|10@1+ (0.03125,0) [0.00000|31.93750] "Unit_Meter"  ICAS1_X_Gateway,MRR2023
 SG_ NR_FR_Object_06_LengthSD : 402|7@1+ (0.03125,0) [0.00000|3.93750] "Unit_Meter"  ICAS1_X_Gateway,MRR2023
 SG_ NR_FR_Object_06_Class : 409|4@1+ (1.0,0.0) [0.0|15] ""  ICAS1_X_Gateway,MRR2023
 SG_ NR_FR_Object_06_ClassPlausib : 413|4@1+ (0.0714285714,0) [0E-10|0.9999999996] "Unit_None"  ICAS1_X_Gateway,MRR2023
 SG_ NR_FR_Object_06_ExistProb : 417|7@1+ (0.0078125,0.015625) [0.0156250|1.0000000] "Unit_None"  ICAS1_X_Gateway,MRR2023
 SG_ NR_FR_Object_06_Age : 424|7@1+ (1,0) [0|126] "Unit_None"  ICAS1_X_Gateway,MRR2023
 SG_ NR_FR_Object_06_YawRateAbs : 431|12@1+ (0.001953125,-4) [-4.000000000|3.996093750] "Unit_RadiaPerSecon"  ICAS1_X_Gateway,MRR2023
 SG_ NR_FR_Object_06_YawRateAbsSD : 443|6@1+ (0.003906,0) [0.000000|0.242172] "Unit_RadiaPerSecon"  ICAS1_X_Gateway,MRR2023
 SG_ NR_FR_Object_06_MeasurementState : 449|1@1+ (1.0,0.0) [0.0|1] ""  ICAS1_X_Gateway,MRR2023
 SG_ SOK_NR_FR_Object_05_06_Signatur : 480|32@1+ (1,0) [0|4294967295] ""  ICAS1_X_Gateway

BO_ 2331595788 NR_FR_Object_07_08: 64 NR_2
 SG_ NR_FR_Object_07_08_CRC : 0|8@1+ (1,0) [0|255] ""  ICAS1_X_Gateway,MRR2023
 SG_ NR_FR_Object_07_08_BZ : 8|4@1+ (1,0) [0|15] ""  ICAS1_X_Gateway,MRR2023
 SG_ NR_FR_Object_07_08_BlockID_02 : 12|4@1+ (1,0) [0|15] "Unit_None"  ICAS1_X_Gateway,MRR2023
 SG_ NR_FR_Object_07_ID : 16|8@1+ (1,0) [1|254] "Unit_None"  ICAS1_X_Gateway,MRR2023
 SG_ NR_FR_Object_07_ReferencePoint : 24|4@1+ (1.0,0.0) [0.0|15] ""  ICAS1_X_Gateway,MRR2023
 SG_ NR_FR_Object_07_PosX : 28|14@1+ (0.03125,-200) [-200.00000|311.93750] "Unit_Meter"  ICAS1_X_Gateway,MRR2023
 SG_ NR_FR_Object_07_PosXSD : 42|8@1+ (0.03125,0) [0.00000|7.93750] "Unit_Meter"  ICAS1_X_Gateway,MRR2023
 SG_ NR_FR_Object_07_PosY : 50|13@1+ (0.03125,-128) [-128.00000|127.93750] "Unit_Meter"  ICAS1_X_Gateway,MRR2023
 SG_ NR_FR_Object_07_PosYSD : 63|8@1+ (0.03125,0) [0.00000|7.93750] "Unit_Meter"  ICAS1_X_Gateway,MRR2023
 SG_ NR_FR_Object_07_vAbsX : 71|12@1+ (0.0625,-128) [-128.0000|127.8750] "Unit_MeterPerSecon"  ICAS1_X_Gateway,MRR2023
 SG_ NR_FR_Object_07_vAbsXSD : 83|6@1+ (0.0625,0) [0.0000|3.8750] "Unit_MeterPerSecon"  ICAS1_X_Gateway,MRR2023
 SG_ NR_FR_Object_07_vAbsY : 89|12@1+ (0.0625,-128) [-128.0000|127.8750] "Unit_MeterPerSecon"  ICAS1_X_Gateway,MRR2023
 SG_ NR_FR_Object_07_vAbsYSD : 101|6@1+ (0.0625,0) [0.0000|3.8750] "Unit_MeterPerSecon"  ICAS1_X_Gateway,MRR2023
 SG_ NR_FR_Object_07_aAbsX : 107|9@1+ (0.0625,-16) [-16.0000|15.8750] "Unit_MeterPerSeconSquar"  ICAS1_X_Gateway,MRR2023
 SG_ NR_FR_Object_07_aAbsXSD : 116|6@1+ (0.0625,0) [0.0000|3.8750] "Unit_MeterPerSeconSquar"  ICAS1_X_Gateway,MRR2023
 SG_ NR_FR_Object_07_aAbsY : 122|9@1+ (0.0625,-16) [-16.0000|15.8750] "Unit_MeterPerSeconSquar"  ICAS1_X_Gateway,MRR2023
 SG_ NR_FR_Object_07_aAbsYSD : 131|6@1+ (0.0625,0) [0.0000|3.8750] "Unit_MeterPerSeconSquar"  ICAS1_X_Gateway,MRR2023
 SG_ NR_FR_Object_07_DynamicState : 137|2@1+ (1.0,0.0) [0.0|3] ""  ICAS1_X_Gateway,MRR2023
 SG_ NR_FR_Object_07_YawAngle : 139|12@1+ (0.001953125,-4) [-4.000000000|3.996093750] "Unit_Radia"  ICAS1_X_Gateway,MRR2023
 SG_ NR_FR_Object_07_YawAngleSD : 151|9@1+ (0.001953125,0) [0E-9|0.996093750] "Unit_Radia"  ICAS1_X_Gateway,MRR2023
 SG_ NR_FR_Object_07_Width : 160|8@1+ (0.03125,0) [0.00000|7.93750] "Unit_Meter"  ICAS1_X_Gateway,MRR2023
 SG_ NR_FR_Object_07_WidthSD : 168|7@1+ (0.03125,0) [0.00000|3.93750] "Unit_Meter"  ICAS1_X_Gateway,MRR2023
 SG_ NR_FR_Object_07_Length : 175|10@1+ (0.03125,0) [0.00000|31.93750] "Unit_Meter"  ICAS1_X_Gateway,MRR2023
 SG_ NR_FR_Object_07_LengthSD : 185|7@1+ (0.03125,0) [0.00000|3.93750] "Unit_Meter"  ICAS1_X_Gateway,MRR2023
 SG_ NR_FR_Object_07_Class : 192|4@1+ (1.0,0.0) [0.0|15] ""  ICAS1_X_Gateway,MRR2023
 SG_ NR_FR_Object_07_ClassPlausib : 196|4@1+ (0.0714285714,0) [0E-10|0.9999999996] "Unit_None"  ICAS1_X_Gateway,MRR2023
 SG_ NR_FR_Object_07_ExistProb : 200|7@1+ (0.0078125,0.015625) [0.0156250|1.0000000] "Unit_None"  ICAS1_X_Gateway,MRR2023
 SG_ NR_FR_Object_07_Age : 207|7@1+ (1,0) [0|126] "Unit_None"  ICAS1_X_Gateway,MRR2023
 SG_ NR_FR_Object_07_YawRateAbs : 214|12@1+ (0.001953125,-4) [-4.000000000|3.996093750] "Unit_RadiaPerSecon"  ICAS1_X_Gateway,MRR2023
 SG_ NR_FR_Object_07_YawRateAbsSD : 226|6@1+ (0.003906,0) [0.000000|0.242172] "Unit_RadiaPerSecon"  ICAS1_X_Gateway,MRR2023
 SG_ NR_FR_Object_07_MeasurementState : 232|1@1+ (1.0,0.0) [0.0|1] ""  ICAS1_X_Gateway,MRR2023
 SG_ NR_FR_Object_08_ID : 233|8@1+ (1,0) [1|254] "Unit_None"  ICAS1_X_Gateway,MRR2023
 SG_ NR_FR_Object_08_ReferencePoint : 241|4@1+ (1.0,0.0) [0.0|15] ""  ICAS1_X_Gateway,MRR2023
 SG_ NR_FR_Object_08_PosX : 245|14@1+ (0.03125,-200) [-200.00000|311.93750] "Unit_Meter"  ICAS1_X_Gateway,MRR2023
 SG_ NR_FR_Object_08_PosXSD : 259|8@1+ (0.03125,0) [0.00000|7.93750] "Unit_Meter"  ICAS1_X_Gateway,MRR2023
 SG_ NR_FR_Object_08_PosY : 267|13@1+ (0.03125,-128) [-128.00000|127.93750] "Unit_Meter"  ICAS1_X_Gateway,MRR2023
 SG_ NR_FR_Object_08_PosYSD : 280|8@1+ (0.03125,0) [0.00000|7.93750] "Unit_Meter"  ICAS1_X_Gateway,MRR2023
 SG_ NR_FR_Object_08_vAbsX : 288|12@1+ (0.0625,-128) [-128.0000|127.8750] "Unit_MeterPerSecon"  ICAS1_X_Gateway,MRR2023
 SG_ NR_FR_Object_08_vAbsXSD : 300|6@1+ (0.0625,0) [0.0000|3.8750] "Unit_MeterPerSecon"  ICAS1_X_Gateway,MRR2023
 SG_ NR_FR_Object_08_vAbsY : 306|12@1+ (0.0625,-128) [-128.0000|127.8750] "Unit_MeterPerSecon"  ICAS1_X_Gateway,MRR2023
 SG_ NR_FR_Object_08_vAbsYSD : 318|6@1+ (0.0625,0) [0.0000|3.8750] "Unit_MeterPerSecon"  ICAS1_X_Gateway,MRR2023
 SG_ NR_FR_Object_08_aAbsX : 324|9@1+ (0.0625,-16) [-16.0000|15.8750] "Unit_MeterPerSeconSquar"  ICAS1_X_Gateway,MRR2023
 SG_ NR_FR_Object_08_aAbsXSD : 333|6@1+ (0.0625,0) [0.0000|3.8750] "Unit_MeterPerSeconSquar"  ICAS1_X_Gateway,MRR2023
 SG_ NR_FR_Object_08_aAbsY : 339|9@1+ (0.0625,-16) [-16.0000|15.8750] "Unit_MeterPerSeconSquar"  ICAS1_X_Gateway,MRR2023
 SG_ NR_FR_Object_08_aAbsYSD : 348|6@1+ (0.0625,0) [0.0000|3.8750] "Unit_MeterPerSeconSquar"  ICAS1_X_Gateway,MRR2023
 SG_ NR_FR_Object_08_DynamicState : 354|2@1+ (1.0,0.0) [0.0|3] ""  ICAS1_X_Gateway,MRR2023
 SG_ NR_FR_Object_08_YawAngle : 356|12@1+ (0.001953125,-4) [-4.000000000|3.996093750] "Unit_Radia"  ICAS1_X_Gateway,MRR2023
 SG_ NR_FR_Object_08_YawAngleSD : 368|9@1+ (0.001953125,0) [0E-9|0.996093750] "Unit_Radia"  ICAS1_X_Gateway,MRR2023
 SG_ NR_FR_Object_08_Width : 377|8@1+ (0.03125,0) [0.00000|7.93750] "Unit_Meter"  ICAS1_X_Gateway,MRR2023
 SG_ NR_FR_Object_08_WidthSD : 385|7@1+ (0.03125,0) [0.00000|3.93750] "Unit_Meter"  ICAS1_X_Gateway,MRR2023
 SG_ NR_FR_Object_08_Length : 392|10@1+ (0.03125,0) [0.00000|31.93750] "Unit_Meter"  ICAS1_X_Gateway,MRR2023
 SG_ NR_FR_Object_08_LengthSD : 402|7@1+ (0.03125,0) [0.00000|3.93750] "Unit_Meter"  ICAS1_X_Gateway,MRR2023
 SG_ NR_FR_Object_08_Class : 409|4@1+ (1.0,0.0) [0.0|15] ""  ICAS1_X_Gateway,MRR2023
 SG_ NR_FR_Object_08_ClassPlausib : 413|4@1+ (0.0714285714,0) [0E-10|0.9999999996] "Unit_None"  ICAS1_X_Gateway,MRR2023
 SG_ NR_FR_Object_08_ExistProb : 417|7@1+ (0.0078125,0.015625) [0.0156250|1.0000000] "Unit_None"  ICAS1_X_Gateway,MRR2023
 SG_ NR_FR_Object_08_Age : 424|7@1+ (1,0) [0|126] "Unit_None"  ICAS1_X_Gateway,MRR2023
 SG_ NR_FR_Object_08_YawRateAbs : 431|12@1+ (0.001953125,-4) [-4.000000000|3.996093750] "Unit_RadiaPerSecon"  ICAS1_X_Gateway,MRR2023
 SG_ NR_FR_Object_08_YawRateAbsSD : 443|6@1+ (0.003906,0) [0.000000|0.242172] "Unit_RadiaPerSecon"  ICAS1_X_Gateway,MRR2023
 SG_ NR_FR_Object_08_MeasurementState : 449|1@1+ (1.0,0.0) [0.0|1] ""  ICAS1_X_Gateway,MRR2023
 SG_ SOK_NR_FR_Object_07_08_Signatur : 480|32@1+ (1,0) [0|4294967295] ""  ICAS1_X_Gateway

CM_ SG_ 2331595780 NR_FL_Object_09_10_BlockID_01 "BlockID is a counter to associate data togehter, which are split over severel PDUs.";
CM_ SG_ 2331595780 NR_FL_Object_09_10_BZ "4bit Botschaftszähler, wird mit jeder Sendebotschaft inkrementiert";
CM_ SG_ 2331595780 NR_FL_Object_09_10_CRC "Für MLB:
Berechnung siehe Lastenheft 'Kommunikationsabsicherung für FlexRay und CAN'
Ab MQB und MLBevo:
Berechnung siehe Lastenheft 'End-to-End Kommunikationsabsicherung'

Endwerte siehe Begleitdokument 'S-PDU Kennungsfolgen'";
CM_ SG_ 2331595780 NR_FL_Object_09_aAbsX "The signal indicates the absolute acceleration of the object in the X direction.";
CM_ SG_ 2331595780 NR_FL_Object_09_aAbsXSD "The signal indicates the standard deviation of the absolute acceleration of the object in the X direction.";
CM_ SG_ 2331595780 NR_FL_Object_09_aAbsY "The signal indicates the absolute acceleration of the object in the Y direction.";
CM_ SG_ 2331595780 NR_FL_Object_09_aAbsYSD "The signal indicates the standard deviation of the absolute acceleration of the object in the Y direction.";
CM_ SG_ 2331595780 NR_FL_Object_09_Age "The signal indicates the age of the object. How long has the object been seen";
CM_ SG_ 2331595780 NR_FL_Object_09_Class "The signal indicates the object class.";
CM_ SG_ 2331595780 NR_FL_Object_09_ClassPlausib "The signal indicates the plausibility of the object class.";
CM_ SG_ 2331595780 NR_FL_Object_09_DynamicState "The signal indicates the motion state of the object.";
CM_ SG_ 2331595780 NR_FL_Object_09_ExistProb "The signal indicates the existence probability of the object.";
CM_ SG_ 2331595780 NR_FL_Object_09_ID "Signal indicates the ID of the object.";
CM_ SG_ 2331595780 NR_FL_Object_09_Length "The signal indicates the length of the object.";
CM_ SG_ 2331595780 NR_FL_Object_09_LengthSD "The signal indicates the standard deviation of the length of the object.";
CM_ SG_ 2331595780 NR_FL_Object_09_MeasurementState "The signal indicates whether the object was measured in the current cycle.";
CM_ SG_ 2331595780 NR_FL_Object_09_PosX "Object X position in UKS";
CM_ SG_ 2331595780 NR_FL_Object_09_PosXSD "The signal indicates the standard deviation of the X position";
CM_ SG_ 2331595780 NR_FL_Object_09_PosY "Object Y position in UKS";
CM_ SG_ 2331595780 NR_FL_Object_09_PosYSD "The signal indicates the standard deviation of the Y position";
CM_ SG_ 2331595780 NR_FL_Object_09_ReferencePoint "Reference Point of the Object";
CM_ SG_ 2331595780 NR_FL_Object_09_vAbsX "The signal indicates the velocity in X direction";
CM_ SG_ 2331595780 NR_FL_Object_09_vAbsXSD "The signal indicates the standard deviation of the velocity in X direction";
CM_ SG_ 2331595780 NR_FL_Object_09_vAbsY "The signal indicates the velocity in Y direction.";
CM_ SG_ 2331595780 NR_FL_Object_09_vAbsYSD "The signal indicates the standard deviation of the velocity in Y direction.";
CM_ SG_ 2331595780 NR_FL_Object_09_Width "The signal indicates the width of the object.";
CM_ SG_ 2331595780 NR_FL_Object_09_WidthSD "The signal indicates the standard deviation of the width of the object.";
CM_ SG_ 2331595780 NR_FL_Object_09_YawAngle "The signal indicates the yaw angle of the object relative to the UKS.";
CM_ SG_ 2331595780 NR_FL_Object_09_YawAngleSD "The signal indicates the standard deviation to the yaw angle.";
CM_ SG_ 2331595780 NR_FL_Object_09_YawRateAbs "The signal indicates the yaw rate of the object relative to the UKS.";
CM_ SG_ 2331595780 NR_FL_Object_09_YawRateAbsSD "The signal indicates the standard deviation to the yaw rate.";
CM_ SG_ 2331595780 NR_FL_Object_10_aAbsX "The signal indicates the absolute acceleration of the object in the X direction.";
CM_ SG_ 2331595780 NR_FL_Object_10_aAbsXSD "The signal indicates the standard deviation of the absolute acceleration of the object in the X direction.";
CM_ SG_ 2331595780 NR_FL_Object_10_aAbsY "The signal indicates the absolute acceleration of the object in the Y direction.";
CM_ SG_ 2331595780 NR_FL_Object_10_aAbsYSD "The signal indicates the standard deviation of the absolute acceleration of the object in the Y direction.";
CM_ SG_ 2331595780 NR_FL_Object_10_Age "The signal indicates the age of the object. How long has the object been seen";
CM_ SG_ 2331595780 NR_FL_Object_10_Class "The signal indicates the object class.";
CM_ SG_ 2331595780 NR_FL_Object_10_ClassPlausib "The signal indicates the plausibility of the object class.";
CM_ SG_ 2331595780 NR_FL_Object_10_DynamicState "The signal indicates the motion state of the object.";
CM_ SG_ 2331595780 NR_FL_Object_10_ExistProb "The signal indicates the existence probability of the object.";
CM_ SG_ 2331595780 NR_FL_Object_10_ID "Signal indicates the ID of the object.";
CM_ SG_ 2331595780 NR_FL_Object_10_Length "The signal indicates the length of the object.";
CM_ SG_ 2331595780 NR_FL_Object_10_LengthSD "The signal indicates the standard deviation of the length of the object.";
CM_ SG_ 2331595780 NR_FL_Object_10_MeasurementState "The signal indicates whether the object was measured in the current cycle.";
CM_ SG_ 2331595780 NR_FL_Object_10_PosX "Object X position in UKS";
CM_ SG_ 2331595780 NR_FL_Object_10_PosXSD "The signal indicates the standard deviation of the X position";
CM_ SG_ 2331595780 NR_FL_Object_10_PosY "Object Y position in UKS";
CM_ SG_ 2331595780 NR_FL_Object_10_PosYSD "The signal indicates the standard deviation of the Y position";
CM_ SG_ 2331595780 NR_FL_Object_10_ReferencePoint "Reference Point of the Object";
CM_ SG_ 2331595780 NR_FL_Object_10_vAbsX "The signal indicates the velocity in X direction";
CM_ SG_ 2331595780 NR_FL_Object_10_vAbsXSD "The signal indicates the standard deviation of the velocity in X direction";
CM_ SG_ 2331595780 NR_FL_Object_10_vAbsY "The signal indicates the velocity in Y direction.";
CM_ SG_ 2331595780 NR_FL_Object_10_vAbsYSD "The signal indicates the standard deviation of the velocity in Y direction.";
CM_ SG_ 2331595780 NR_FL_Object_10_Width "The signal indicates the width of the object.";
CM_ SG_ 2331595780 NR_FL_Object_10_WidthSD "The signal indicates the standard deviation of the width of the object.";
CM_ SG_ 2331595780 NR_FL_Object_10_YawAngle "The signal indicates the yaw angle of the object relative to the UKS.";
CM_ SG_ 2331595780 NR_FL_Object_10_YawAngleSD "The signal indicates the standard deviation to the yaw angle.";
CM_ SG_ 2331595780 NR_FL_Object_10_YawRateAbs "The signal indicates the yaw rate of the object relative to the UKS.";
CM_ SG_ 2331595780 NR_FL_Object_10_YawRateAbsSD "The signal indicates the standard deviation to the yaw rate.";
CM_ SG_ 2331595780 SOK_NR_FL_Object_09_10_Signatur "Signatur im Rahmen der durch SOK geschützen Broadcast-Kommunikation
";

CM_ SG_ 2589284096 DS_FL_StructureVersion_1 "Current 'Datensatzversion' structure";
CM_ SG_ 2589284096 DS_FL_StructureVersion_2 "Current 'Datensatzversion' version";
CM_ SG_ 2589284096 NR_FL_HW_Version "Hardware Version (intern)";
CM_ SG_ 2589284096 NR_FL_SerialNumber "Serial number of the component.";
CM_ SG_ 2589284096 NR_FL_SW_Version "Sofware Version of Sensor";

CM_ SG_ 2331595852 NR_FL_Structure_BlockID_01 "BlockID is a counter to associate data togehter, which are split over severel PDUs.";
CM_ SG_ 2331595852 NR_FL_Structure_left_ExistProb "The signal indicates the existence probability of the side cultivation (Randbebauung) structure left";
CM_ SG_ 2331595852 NR_FL_Structure_left_LatDist "Distance to side cultivation (Randbebauung) structure left";
CM_ SG_ 2331595852 NR_FL_Structure_left_Type "Type of side cultivation (Randbebauung) structure left";

CM_ SG_ 2264486976 NR_FL_SyncCounter "Counter of Synchronisation message to which the Sync_FollowUp message belongs.";
CM_ SG_ 2264486976 NR_FL_SyncVersion "Signal indicates the version of synchronisation";

CM_ SG_ 2264486980 NR_FL_CounterValue "Value of the Counter within the message Sync to which the Sync_FollowUp message belongs.";
CM_ SG_ 2264486980 NR_FL_RandomSeed "Random seed value for the transmitted synchronisation message";
CM_ SG_ 2264486980 NR_FL_Time_CorrectionField "Timer correction value for the transmitted message";
CM_ SG_ 2264486980 NR_FL_Time_HighPrecision "Upper word for time synchronisation.";
CM_ SG_ 2264486980 NR_FL_Time_LowPrecision "Lower word for time synchronisation.";

CM_ SG_ 2264486985 NR_FL_EarliestStartTime "Signal indicates the earlist chirp sequence start time";
CM_ SG_ 2264486985 NR_FL_InteferenceInfo "Signal indicates the current interferece level";
CM_ SG_ 2264486985 NR_FL_LatestSyncCounter "Signal indicates the latest synchronisation counter";
CM_ SG_ 2264486985 NR_FL_RequestedModulation "Signal indicates the requested modulation mode";
CM_ SG_ 2264486985 NR_FL_SyncCycleCount "Signal indicates the current cycle indication";
CM_ SG_ 2264486985 NR_FL_SyncReadyVersion "Signal indicates the version of synchronisation ready";

CM_ SG_ 2331595826 NR_FR_Cal_resp "Signal is used for the calibration.";
CM_ SG_ 2331595826 NR_FR_CalibrationMode "Current mode of calibration.";
CM_ SG_ 2331595826 NR_FR_QualFactorAutoCalib "Estimated qulality factor of  auto-alignment.";
CM_ SG_ 2331595826 NR_FR_resp_val "Signal is used for the calibration.";
CM_ SG_ 2331595826 NR_FR_ShortTrackCal_State "Signal is used for short track calibration.";

CM_ SG_ 2331595791 NR_FR_Contour_BlockID_02 "BlockID is a counter to associate data togehter, which are split over severel PDUs.";
CM_ SG_ 2331595791 NR_FR_Contour_BZ "4bit Botschaftszähler, wird mit jeder Sendebotschaft inkrementiert";
CM_ SG_ 2331595791 NR_FR_Contour_CRC "Für MLB:
Berechnung siehe Lastenheft 'Kommunikationsabsicherung für FlexRay und CAN'
Ab MQB und MLBevo:
Berechnung siehe Lastenheft 'End-to-End Kommunikationsabsicherung'

Endwerte siehe Begleitdokument 'S-PDU Kennungsfolgen'";
CM_ SG_ 2331595791 NR_FR_Contour_right_01_Age "The signal indicates the age of the contour 1. How long has the contour been seen";
CM_ SG_ 2331595791 NR_FR_Contour_right_01_Type "Type of edge structure contour 1";
CM_ SG_ 2331595791 NR_FR_Contour_right_01_x01 "X position of the support point of the contour 1";
CM_ SG_ 2331595791 NR_FR_Contour_right_01_x02 "X position of the support point of the contour 1";
CM_ SG_ 2331595791 NR_FR_Contour_right_01_x03 "X position of the support point of the contour 1";
CM_ SG_ 2331595791 NR_FR_Contour_right_01_x04 "X position of the support point of the contour 1";
CM_ SG_ 2331595791 NR_FR_Contour_right_01_x05 "X position of the support point of the contour 1";
CM_ SG_ 2331595791 NR_FR_Contour_right_01_x06 "X position of the support point of the contour 1";
CM_ SG_ 2331595791 NR_FR_Contour_right_01_x07 "X position of the support point of the contour 1";
CM_ SG_ 2331595791 NR_FR_Contour_right_01_y01 "Y position of the support point of the contour 1";
CM_ SG_ 2331595791 NR_FR_Contour_right_01_y02 "Y position of the support point of the contour 1";
CM_ SG_ 2331595791 NR_FR_Contour_right_01_y03 "Y position of the support point of the contour 1";
CM_ SG_ 2331595791 NR_FR_Contour_right_01_y04 "Y position of the support point of the contour 1";
CM_ SG_ 2331595791 NR_FR_Contour_right_01_y05 "Y position of the support point of the contour 1";
CM_ SG_ 2331595791 NR_FR_Contour_right_01_y06 "Y position of the support point of the contour 1";
CM_ SG_ 2331595791 NR_FR_Contour_right_01_y07 "Y position of the support point of the contour 1";
CM_ SG_ 2331595791 NR_FR_Contour_right_02_Age "The signal indicates the age of the contour 2. How long has the contour been seen";
CM_ SG_ 2331595791 NR_FR_Contour_right_02_Type "Type of edge structure contour 2";
CM_ SG_ 2331595791 NR_FR_Contour_right_02_x01 "X position of the support point of the contour 2";
CM_ SG_ 2331595791 NR_FR_Contour_right_02_x02 "X position of the support point of the contour 2";
CM_ SG_ 2331595791 NR_FR_Contour_right_02_x03 "X position of the support point of the contour 2";
CM_ SG_ 2331595791 NR_FR_Contour_right_02_x04 "X position of the support point of the contour 2";
CM_ SG_ 2331595791 NR_FR_Contour_right_02_x05 "X position of the support point of the contour 2";
CM_ SG_ 2331595791 NR_FR_Contour_right_02_x06 "X position of the support point of the contour 2";
CM_ SG_ 2331595791 NR_FR_Contour_right_02_x07 "X position of the support point of the contour 2";
CM_ SG_ 2331595791 NR_FR_Contour_right_02_y01 "Y position of the support point of the contour 2";
CM_ SG_ 2331595791 NR_FR_Contour_right_02_y02 "Y position of the support point of the contour 2";
CM_ SG_ 2331595791 NR_FR_Contour_right_02_y03 "Y position of the support point of the contour 2";
CM_ SG_ 2331595791 NR_FR_Contour_right_02_y04 "Y position of the support point of the contour 2";
CM_ SG_ 2331595791 NR_FR_Contour_right_02_y05 "Y position of the support point of the contour 2";
CM_ SG_ 2331595791 NR_FR_Contour_right_02_y06 "Y position of the support point of the contour 2";
CM_ SG_ 2331595791 NR_FR_Contour_right_02_y07 "Y position of the support point of the contour 2";
CM_ SG_ 2331595791 NR_FR_Contour_right_Linkage "The signal indicates  whether contours are interconected";
CM_ SG_ 2331595791 SOK_NR_FR_Contour_Signatur "Signatur im Rahmen der durch SOK geschützen Broadcast-Kommunikation
";

CM_ SG_ 2331595782 NR_FR_Blindness "The signal indicates sensor blindness/occlusion";
CM_ SG_ 2331595782 NR_FR_BlockID_02 "BlockID is a counter to associate data togehter, which are split over severel PDUs.";
CM_ SG_ 2331595782 NR_FR_CalibrationState "The signal indicates the current calibration status of the sensor.";
CM_ SG_ 2331595782 NR_FR_Failure "The signal indicates an active failure on the sensor";
CM_ SG_ 2331595782 NR_FR_Freesight_NOK "The signal indicates if a free view was not possible";
CM_ SG_ 2331595782 NR_FR_Header_BZ "4bit Botschaftszähler, wird mit jeder Sendebotschaft inkrementiert";
CM_ SG_ 2331595782 NR_FR_Header_CRC "Für MLB:
Berechnung siehe Lastenheft 'Kommunikationsabsicherung für FlexRay und CAN'
Ab MQB und MLBevo:
Berechnung siehe Lastenheft 'End-to-End Kommunikationsabsicherung'

Endwerte siehe Begleitdokument 'S-PDU Kennungsfolgen'";
CM_ SG_ 2331595782 NR_FR_MeasurementTimeHigh "Time stamp based on time stamp format of base service Zeitmaster and its definition of 'Precise Local Time' and time format TMF_01. High part of the time stamp corresponds to the seconds part of the time";
CM_ SG_ 2331595782 NR_FR_MeasurementTimeLapNumber "The lap number of the TLT master under which the MeasurementTime was derived";
CM_ SG_ 2331595782 NR_FR_MeasurementTimeLow "Time stamp based on time stamp format of base service Zeitmaster and its definition of 'Precise Local Time' and time format TMF_01. Low part of the time stamp corresponds to the nanoseconds part of the time";
CM_ SG_ 2331595782 NR_FR_MeasurementTimeStatus "Describes the quality of the timestamp";
CM_ SG_ 2331595782 NR_FR_NotAvailable "The signal indicates not availability of the sensor";
CM_ SG_ 2331595782 NR_FR_RangeDegradation_Sect1 "Estimated degradation of the sensor in range for sector 1.";
CM_ SG_ 2331595782 NR_FR_RangeDegradation_Sect2 "Estimated degradation of the sensor in range for sector 2.";
CM_ SG_ 2331595782 NR_FR_RangeDegradation_Sect3 "This signal is used for the feature 'Blindheitsverdacht'(due to K-Matrix Freeze, this existing signal is used, instead of a correctly named signal). Like NR_XX_Blindness the signal indicates sensor blindness and uses the same algorithm. Parameters are adj";
CM_ SG_ 2331595782 SOK_NR_FR_Header_Signatur "Signatur im Rahmen der durch SOK geschützen Broadcast-Kommunikation
";

CM_ SG_ 2331595785 NR_FR_Object_01_02_BlockID_02 "BlockID is a counter to associate data togehter, which are split over severel PDUs.";
CM_ SG_ 2331595785 NR_FR_Object_01_02_BZ "4bit Botschaftszähler, wird mit jeder Sendebotschaft inkrementiert";
CM_ SG_ 2331595785 NR_FR_Object_01_02_CRC "Für MLB:
Berechnung siehe Lastenheft 'Kommunikationsabsicherung für FlexRay und CAN'
Ab MQB und MLBevo:
Berechnung siehe Lastenheft 'End-to-End Kommunikationsabsicherung'

Endwerte siehe Begleitdokument 'S-PDU Kennungsfolgen'";
CM_ SG_ 2331595785 NR_FR_Object_01_aAbsX "The signal indicates the absolute acceleration of the object in the X direction.";
CM_ SG_ 2331595785 NR_FR_Object_01_aAbsXSD "The signal indicates the standard deviation of the absolute acceleration of the object in the X direction.";
CM_ SG_ 2331595785 NR_FR_Object_01_aAbsY "The signal indicates the absolute acceleration of the object in the Y direction.";
CM_ SG_ 2331595785 NR_FR_Object_01_aAbsYSD "The signal indicates the standard deviation of the absolute acceleration of the object in the Y direction.";
CM_ SG_ 2331595785 NR_FR_Object_01_Age "The signal indicates the age of the object. How long has the object been seen";
CM_ SG_ 2331595785 NR_FR_Object_01_Class "The signal indicates the object class.";
CM_ SG_ 2331595785 NR_FR_Object_01_ClassPlausib "The signal indicates the plausibility of the object class.";
CM_ SG_ 2331595785 NR_FR_Object_01_DynamicState "The signal indicates the motion state of the object.";
CM_ SG_ 2331595785 NR_FR_Object_01_ExistProb "The signal indicates the existence probability of the object.";
CM_ SG_ 2331595785 NR_FR_Object_01_ID "Signal indicates the ID of the object.";
CM_ SG_ 2331595785 NR_FR_Object_01_Length "The signal indicates the length of the object.";
CM_ SG_ 2331595785 NR_FR_Object_01_LengthSD "The signal indicates the standard deviation of the length of the object.";
CM_ SG_ 2331595785 NR_FR_Object_01_MeasurementState "The signal indicates whether the object was measured in the current cycle.";
CM_ SG_ 2331595785 NR_FR_Object_01_PosX "Object X position in UKS";
CM_ SG_ 2331595785 NR_FR_Object_01_PosXSD "The signal indicates the standard deviation of the X position";
CM_ SG_ 2331595785 NR_FR_Object_01_PosY "Object Y position in UKS";
CM_ SG_ 2331595785 NR_FR_Object_01_PosYSD "The signal indicates the standard deviation of the Y position";
CM_ SG_ 2331595785 NR_FR_Object_01_ReferencePoint "Reference Point of the Object";
CM_ SG_ 2331595785 NR_FR_Object_01_vAbsX "The signal indicates the velocity in X direction";
CM_ SG_ 2331595785 NR_FR_Object_01_vAbsXSD "The signal indicates the standard deviation of the velocity in X direction";
CM_ SG_ 2331595785 NR_FR_Object_01_vAbsY "The signal indicates the velocity in Y direction.";
CM_ SG_ 2331595785 NR_FR_Object_01_vAbsYSD "The signal indicates the standard deviation of the velocity in Y direction.";
CM_ SG_ 2331595785 NR_FR_Object_01_Width "The signal indicates the width of the object.";
CM_ SG_ 2331595785 NR_FR_Object_01_WidthSD "The signal indicates the standard deviation of the width of the object.";
CM_ SG_ 2331595785 NR_FR_Object_01_YawAngle "The signal indicates the yaw angle of the object relative to the UKS.";
CM_ SG_ 2331595785 NR_FR_Object_01_YawAngleSD "The signal indicates the standard deviation to the yaw angle.";
CM_ SG_ 2331595785 NR_FR_Object_01_YawRateAbs "The signal indicates the yaw rate of the object relative to the UKS.";
CM_ SG_ 2331595785 NR_FR_Object_01_YawRateAbsSD "The signal indicates the standard deviation to the yaw rate.";
CM_ SG_ 2331595785 NR_FR_Object_02_aAbsX "The signal indicates the absolute acceleration of the object in the X direction.";
CM_ SG_ 2331595785 NR_FR_Object_02_aAbsXSD "The signal indicates the standard deviation of the absolute acceleration of the object in the X direction.";
CM_ SG_ 2331595785 NR_FR_Object_02_aAbsY "The signal indicates the absolute acceleration of the object in the Y direction.";
CM_ SG_ 2331595785 NR_FR_Object_02_aAbsYSD "The signal indicates the standard deviation of the absolute acceleration of the object in the Y direction.";
CM_ SG_ 2331595785 NR_FR_Object_02_Age "The signal indicates the age of the object. How long has the object been seen";
CM_ SG_ 2331595785 NR_FR_Object_02_Class "The signal indicates the object class.";
CM_ SG_ 2331595785 NR_FR_Object_02_ClassPlausib "The signal indicates the plausibility of the object class.";
CM_ SG_ 2331595785 NR_FR_Object_02_DynamicState "The signal indicates the motion state of the object.";
CM_ SG_ 2331595785 NR_FR_Object_02_ExistProb "The signal indicates the existence probability of the object.";
CM_ SG_ 2331595785 NR_FR_Object_02_ID "Signal indicates the ID of the object.";
CM_ SG_ 2331595785 NR_FR_Object_02_Length "The signal indicates the length of the object.";
CM_ SG_ 2331595785 NR_FR_Object_02_LengthSD "The signal indicates the standard deviation of the length of the object.";
CM_ SG_ 2331595785 NR_FR_Object_02_MeasurementState "The signal indicates whether the object was measured in the current cycle.";
CM_ SG_ 2331595785 NR_FR_Object_02_PosX "Object X position in UKS";
CM_ SG_ 2331595785 NR_FR_Object_02_PosXSD "The signal indicates the standard deviation of the X position";
CM_ SG_ 2331595785 NR_FR_Object_02_PosY "Object Y position in UKS";
CM_ SG_ 2331595785 NR_FR_Object_02_PosYSD "The signal indicates the standard deviation of the Y position";
CM_ SG_ 2331595785 NR_FR_Object_02_ReferencePoint "Reference Point of the Object";
CM_ SG_ 2331595785 NR_FR_Object_02_vAbsX "The signal indicates the velocity in X direction";
CM_ SG_ 2331595785 NR_FR_Object_02_vAbsXSD "The signal indicates the standard deviation of the velocity in X direction";
CM_ SG_ 2331595785 NR_FR_Object_02_vAbsY "The signal indicates the velocity in Y direction.";
CM_ SG_ 2331595785 NR_FR_Object_02_vAbsYSD "The signal indicates the standard deviation of the velocity in Y direction.";
CM_ SG_ 2331595785 NR_FR_Object_02_Width "The signal indicates the width of the object.";
CM_ SG_ 2331595785 NR_FR_Object_02_WidthSD "The signal indicates the standard deviation of the width of the object.";
CM_ SG_ 2331595785 NR_FR_Object_02_YawAngle "The signal indicates the yaw angle of the object relative to the UKS.";
CM_ SG_ 2331595785 NR_FR_Object_02_YawAngleSD "The signal indicates the standard deviation to the yaw angle.";
CM_ SG_ 2331595785 NR_FR_Object_02_YawRateAbs "The signal indicates the yaw rate of the object relative to the UKS.";
CM_ SG_ 2331595785 NR_FR_Object_02_YawRateAbsSD "The signal indicates the standard deviation to the yaw rate.";
CM_ SG_ 2331595785 SOK_NR_FR_Object_01_02_Signatur "Signatur im Rahmen der durch SOK geschützen Broadcast-Kommunikation
";

CM_ SG_ 2331595786 NR_FR_Object_03_04_BlockID_02 "BlockID is a counter to associate data togehter, which are split over severel PDUs.";
CM_ SG_ 2331595786 NR_FR_Object_03_04_BZ "4bit Botschaftszähler, wird mit jeder Sendebotschaft inkrementiert";
CM_ SG_ 2331595786 NR_FR_Object_03_04_CRC "Für MLB:
Berechnung siehe Lastenheft 'Kommunikationsabsicherung für FlexRay und CAN'
Ab MQB und MLBevo:
Berechnung siehe Lastenheft 'End-to-End Kommunikationsabsicherung'

Endwerte siehe Begleitdokument 'S-PDU Kennungsfolgen'";
CM_ SG_ 2331595786 NR_FR_Object_03_aAbsX "The signal indicates the absolute acceleration of the object in the X direction.";
CM_ SG_ 2331595786 NR_FR_Object_03_aAbsXSD "The signal indicates the standard deviation of the absolute acceleration of the object in the X direction.";
CM_ SG_ 2331595786 NR_FR_Object_03_aAbsY "The signal indicates the absolute acceleration of the object in the Y direction.";
CM_ SG_ 2331595786 NR_FR_Object_03_aAbsYSD "The signal indicates the standard deviation of the absolute acceleration of the object in the Y direction.";
CM_ SG_ 2331595786 NR_FR_Object_03_Age "The signal indicates the age of the object. How long has the object been seen";
CM_ SG_ 2331595786 NR_FR_Object_03_Class "The signal indicates the object class.";
CM_ SG_ 2331595786 NR_FR_Object_03_ClassPlausib "The signal indicates the plausibility of the object class.";
CM_ SG_ 2331595786 NR_FR_Object_03_DynamicState "The signal indicates the motion state of the object.";
CM_ SG_ 2331595786 NR_FR_Object_03_ExistProb "The signal indicates the existence probability of the object.";
CM_ SG_ 2331595786 NR_FR_Object_03_ID "Signal indicates the ID of the object.";
CM_ SG_ 2331595786 NR_FR_Object_03_Length "The signal indicates the length of the object.";
CM_ SG_ 2331595786 NR_FR_Object_03_LengthSD "The signal indicates the standard deviation of the length of the object.";
CM_ SG_ 2331595786 NR_FR_Object_03_MeasurementState "The signal indicates whether the object was measured in the current cycle.";
CM_ SG_ 2331595786 NR_FR_Object_03_PosX "Object X position in UKS";
CM_ SG_ 2331595786 NR_FR_Object_03_PosXSD "The signal indicates the standard deviation of the X position";
CM_ SG_ 2331595786 NR_FR_Object_03_PosY "Object Y position in UKS";
CM_ SG_ 2331595786 NR_FR_Object_03_PosYSD "The signal indicates the standard deviation of the Y position";
CM_ SG_ 2331595786 NR_FR_Object_03_ReferencePoint "Reference Point of the Object";
CM_ SG_ 2331595786 NR_FR_Object_03_vAbsX "The signal indicates the velocity in X direction";
CM_ SG_ 2331595786 NR_FR_Object_03_vAbsXSD "The signal indicates the standard deviation of the velocity in X direction";
CM_ SG_ 2331595786 NR_FR_Object_03_vAbsY "The signal indicates the velocity in Y direction.";
CM_ SG_ 2331595786 NR_FR_Object_03_vAbsYSD "The signal indicates the standard deviation of the velocity in Y direction.";
CM_ SG_ 2331595786 NR_FR_Object_03_Width "The signal indicates the width of the object.";
CM_ SG_ 2331595786 NR_FR_Object_03_WidthSD "The signal indicates the standard deviation of the width of the object.";
CM_ SG_ 2331595786 NR_FR_Object_03_YawAngle "The signal indicates the yaw angle of the object relative to the UKS.";
CM_ SG_ 2331595786 NR_FR_Object_03_YawAngleSD "The signal indicates the standard deviation to the yaw angle.";
CM_ SG_ 2331595786 NR_FR_Object_03_YawRateAbs "The signal indicates the yaw rate of the object relative to the UKS.";
CM_ SG_ 2331595786 NR_FR_Object_03_YawRateAbsSD "The signal indicates the standard deviation to the yaw rate.";
CM_ SG_ 2331595786 NR_FR_Object_04_aAbsX "The signal indicates the absolute acceleration of the object in the X direction.";
CM_ SG_ 2331595786 NR_FR_Object_04_aAbsXSD "The signal indicates the standard deviation of the absolute acceleration of the object in the X direction.";
CM_ SG_ 2331595786 NR_FR_Object_04_aAbsY "The signal indicates the absolute acceleration of the object in the Y direction.";
CM_ SG_ 2331595786 NR_FR_Object_04_aAbsYSD "The signal indicates the standard deviation of the absolute acceleration of the object in the Y direction.";
CM_ SG_ 2331595786 NR_FR_Object_04_Age "The signal indicates the age of the object. How long has the object been seen";
CM_ SG_ 2331595786 NR_FR_Object_04_Class "The signal indicates the object class.";
CM_ SG_ 2331595786 NR_FR_Object_04_ClassPlausib "The signal indicates the plausibility of the object class.";
CM_ SG_ 2331595786 NR_FR_Object_04_DynamicState "The signal indicates the motion state of the object.";
CM_ SG_ 2331595786 NR_FR_Object_04_ExistProb "The signal indicates the existence probability of the object.";
CM_ SG_ 2331595786 NR_FR_Object_04_ID "Signal indicates the ID of the object.";
CM_ SG_ 2331595786 NR_FR_Object_04_Length "The signal indicates the length of the object.";
CM_ SG_ 2331595786 NR_FR_Object_04_LengthSD "The signal indicates the standard deviation of the length of the object.";
CM_ SG_ 2331595786 NR_FR_Object_04_MeasurementState "The signal indicates whether the object was measured in the current cycle.";
CM_ SG_ 2331595786 NR_FR_Object_04_PosX "Object X position in UKS";
CM_ SG_ 2331595786 NR_FR_Object_04_PosXSD "The signal indicates the standard deviation of the X position";
CM_ SG_ 2331595786 NR_FR_Object_04_PosY "Object Y position in UKS";
CM_ SG_ 2331595786 NR_FR_Object_04_PosYSD "The signal indicates the standard deviation of the Y position";
CM_ SG_ 2331595786 NR_FR_Object_04_ReferencePoint "Reference Point of the Object";
CM_ SG_ 2331595786 NR_FR_Object_04_vAbsX "The signal indicates the velocity in X direction";
CM_ SG_ 2331595786 NR_FR_Object_04_vAbsXSD "The signal indicates the standard deviation of the velocity in X direction";
CM_ SG_ 2331595786 NR_FR_Object_04_vAbsY "The signal indicates the velocity in Y direction.";
CM_ SG_ 2331595786 NR_FR_Object_04_vAbsYSD "The signal indicates the standard deviation of the velocity in Y direction.";
CM_ SG_ 2331595786 NR_FR_Object_04_Width "The signal indicates the width of the object.";
CM_ SG_ 2331595786 NR_FR_Object_04_WidthSD "The signal indicates the standard deviation of the width of the object.";
CM_ SG_ 2331595786 NR_FR_Object_04_YawAngle "The signal indicates the yaw angle of the object relative to the UKS.";
CM_ SG_ 2331595786 NR_FR_Object_04_YawAngleSD "The signal indicates the standard deviation to the yaw angle.";
CM_ SG_ 2331595786 NR_FR_Object_04_YawRateAbs "The signal indicates the yaw rate of the object relative to the UKS.";
CM_ SG_ 2331595786 NR_FR_Object_04_YawRateAbsSD "The signal indicates the standard deviation to the yaw rate.";
CM_ SG_ 2331595786 SOK_NR_FR_Object_03_04_Signatur "Signatur im Rahmen der durch SOK geschützen Broadcast-Kommunikation
";

CM_ SG_ 2331595787 NR_FR_Object_05_06_BlockID_02 "BlockID is a counter to associate data togehter, which are split over severel PDUs.";
CM_ SG_ 2331595787 NR_FR_Object_05_06_BZ "4bit Botschaftszähler, wird mit jeder Sendebotschaft inkrementiert";
CM_ SG_ 2331595787 NR_FR_Object_05_06_CRC "Für MLB:
Berechnung siehe Lastenheft 'Kommunikationsabsicherung für FlexRay und CAN'
Ab MQB und MLBevo:
Berechnung siehe Lastenheft 'End-to-End Kommunikationsabsicherung'

Endwerte siehe Begleitdokument 'S-PDU Kennungsfolgen'";
CM_ SG_ 2331595787 NR_FR_Object_05_aAbsX "The signal indicates the absolute acceleration of the object in the X direction.";
CM_ SG_ 2331595787 NR_FR_Object_05_aAbsXSD "The signal indicates the standard deviation of the absolute acceleration of the object in the X direction.";
CM_ SG_ 2331595787 NR_FR_Object_05_aAbsY "The signal indicates the absolute acceleration of the object in the Y direction.";
CM_ SG_ 2331595787 NR_FR_Object_05_aAbsYSD "The signal indicates the standard deviation of the absolute acceleration of the object in the Y direction.";
CM_ SG_ 2331595787 NR_FR_Object_05_Age "The signal indicates the age of the object. How long has the object been seen";
CM_ SG_ 2331595787 NR_FR_Object_05_Class "The signal indicates the object class.";
CM_ SG_ 2331595787 NR_FR_Object_05_ClassPlausib "The signal indicates the plausibility of the object class.";
CM_ SG_ 2331595787 NR_FR_Object_05_DynamicState "The signal indicates the motion state of the object.";
CM_ SG_ 2331595787 NR_FR_Object_05_ExistProb "The signal indicates the existence probability of the object.";
CM_ SG_ 2331595787 NR_FR_Object_05_ID "Signal indicates the ID of the object.";
CM_ SG_ 2331595787 NR_FR_Object_05_Length "The signal indicates the length of the object.";
CM_ SG_ 2331595787 NR_FR_Object_05_LengthSD "The signal indicates the standard deviation of the length of the object.";
CM_ SG_ 2331595787 NR_FR_Object_05_MeasurementState "The signal indicates whether the object was measured in the current cycle.";
CM_ SG_ 2331595787 NR_FR_Object_05_PosX "Object X position in UKS";
CM_ SG_ 2331595787 NR_FR_Object_05_PosXSD "The signal indicates the standard deviation of the X position";
CM_ SG_ 2331595787 NR_FR_Object_05_PosY "Object Y position in UKS";
CM_ SG_ 2331595787 NR_FR_Object_05_PosYSD "The signal indicates the standard deviation of the Y position";
CM_ SG_ 2331595787 NR_FR_Object_05_ReferencePoint "Reference Point of the Object";
CM_ SG_ 2331595787 NR_FR_Object_05_vAbsX "The signal indicates the velocity in X direction";
CM_ SG_ 2331595787 NR_FR_Object_05_vAbsXSD "The signal indicates the standard deviation of the velocity in X direction";
CM_ SG_ 2331595787 NR_FR_Object_05_vAbsY "The signal indicates the velocity in Y direction.";
CM_ SG_ 2331595787 NR_FR_Object_05_vAbsYSD "The signal indicates the standard deviation of the velocity in Y direction.";
CM_ SG_ 2331595787 NR_FR_Object_05_Width "The signal indicates the width of the object.";
CM_ SG_ 2331595787 NR_FR_Object_05_WidthSD "The signal indicates the standard deviation of the width of the object.";
CM_ SG_ 2331595787 NR_FR_Object_05_YawAngle "The signal indicates the yaw angle of the object relative to the UKS.";
CM_ SG_ 2331595787 NR_FR_Object_05_YawAngleSD "The signal indicates the standard deviation to the yaw angle.";
CM_ SG_ 2331595787 NR_FR_Object_05_YawRateAbs "The signal indicates the yaw rate of the object relative to the UKS.";
CM_ SG_ 2331595787 NR_FR_Object_05_YawRateAbsSD "The signal indicates the standard deviation to the yaw rate.";
CM_ SG_ 2331595787 NR_FR_Object_06_aAbsX "The signal indicates the absolute acceleration of the object in the X direction.";
CM_ SG_ 2331595787 NR_FR_Object_06_aAbsXSD "The signal indicates the standard deviation of the absolute acceleration of the object in the X direction.";
CM_ SG_ 2331595787 NR_FR_Object_06_aAbsY "The signal indicates the absolute acceleration of the object in the Y direction.";
CM_ SG_ 2331595787 NR_FR_Object_06_aAbsYSD "The signal indicates the standard deviation of the absolute acceleration of the object in the Y direction.";
CM_ SG_ 2331595787 NR_FR_Object_06_Age "The signal indicates the age of the object. How long has the object been seen";
CM_ SG_ 2331595787 NR_FR_Object_06_Class "The signal indicates the object class.";
CM_ SG_ 2331595787 NR_FR_Object_06_ClassPlausib "The signal indicates the plausibility of the object class.";
CM_ SG_ 2331595787 NR_FR_Object_06_DynamicState "The signal indicates the motion state of the object.";
CM_ SG_ 2331595787 NR_FR_Object_06_ExistProb "The signal indicates the existence probability of the object.";
CM_ SG_ 2331595787 NR_FR_Object_06_ID "Signal indicates the ID of the object.";
CM_ SG_ 2331595787 NR_FR_Object_06_Length "The signal indicates the length of the object.";
CM_ SG_ 2331595787 NR_FR_Object_06_LengthSD "The signal indicates the standard deviation of the length of the object.";
CM_ SG_ 2331595787 NR_FR_Object_06_MeasurementState "The signal indicates whether the object was measured in the current cycle.";
CM_ SG_ 2331595787 NR_FR_Object_06_PosX "Object X position in UKS";
CM_ SG_ 2331595787 NR_FR_Object_06_PosXSD "The signal indicates the standard deviation of the X position";
CM_ SG_ 2331595787 NR_FR_Object_06_PosY "Object Y position in UKS";
CM_ SG_ 2331595787 NR_FR_Object_06_PosYSD "The signal indicates the standard deviation of the Y position";
CM_ SG_ 2331595787 NR_FR_Object_06_ReferencePoint "Reference Point of the Object";
CM_ SG_ 2331595787 NR_FR_Object_06_vAbsX "The signal indicates the velocity in X direction";
CM_ SG_ 2331595787 NR_FR_Object_06_vAbsXSD "The signal indicates the standard deviation of the velocity in X direction";
CM_ SG_ 2331595787 NR_FR_Object_06_vAbsY "The signal indicates the velocity in Y direction.";
CM_ SG_ 2331595787 NR_FR_Object_06_vAbsYSD "The signal indicates the standard deviation of the velocity in Y direction.";
CM_ SG_ 2331595787 NR_FR_Object_06_Width "The signal indicates the width of the object.";
CM_ SG_ 2331595787 NR_FR_Object_06_WidthSD "The signal indicates the standard deviation of the width of the object.";
CM_ SG_ 2331595787 NR_FR_Object_06_YawAngle "The signal indicates the yaw angle of the object relative to the UKS.";
CM_ SG_ 2331595787 NR_FR_Object_06_YawAngleSD "The signal indicates the standard deviation to the yaw angle.";
CM_ SG_ 2331595787 NR_FR_Object_06_YawRateAbs "The signal indicates the yaw rate of the object relative to the UKS.";
CM_ SG_ 2331595787 NR_FR_Object_06_YawRateAbsSD "The signal indicates the standard deviation to the yaw rate.";
CM_ SG_ 2331595787 SOK_NR_FR_Object_05_06_Signatur "Signatur im Rahmen der durch SOK geschützen Broadcast-Kommunikation
";

CM_ SG_ 2331595788 NR_FR_Object_07_08_BlockID_02 "BlockID is a counter to associate data togehter, which are split over severel PDUs.";
CM_ SG_ 2331595788 NR_FR_Object_07_08_BZ "4bit Botschaftszähler, wird mit jeder Sendebotschaft inkrementiert";
CM_ SG_ 2331595788 NR_FR_Object_07_08_CRC "Für MLB:
Berechnung siehe Lastenheft 'Kommunikationsabsicherung für FlexRay und CAN'
Ab MQB und MLBevo:
Berechnung siehe Lastenheft 'End-to-End Kommunikationsabsicherung'

Endwerte siehe Begleitdokument 'S-PDU Kennungsfolgen'";
CM_ SG_ 2331595788 NR_FR_Object_07_aAbsX "The signal indicates the absolute acceleration of the object in the X direction.";
CM_ SG_ 2331595788 NR_FR_Object_07_aAbsXSD "The signal indicates the standard deviation of the absolute acceleration of the object in the X direction.";
CM_ SG_ 2331595788 NR_FR_Object_07_aAbsY "The signal indicates the absolute acceleration of the object in the Y direction.";
CM_ SG_ 2331595788 NR_FR_Object_07_aAbsYSD "The signal indicates the standard deviation of the absolute acceleration of the object in the Y direction.";
CM_ SG_ 2331595788 NR_FR_Object_07_Age "The signal indicates the age of the object. How long has the object been seen";
CM_ SG_ 2331595788 NR_FR_Object_07_Class "The signal indicates the object class.";
CM_ SG_ 2331595788 NR_FR_Object_07_ClassPlausib "The signal indicates the plausibility of the object class.";
CM_ SG_ 2331595788 NR_FR_Object_07_DynamicState "The signal indicates the motion state of the object.";
CM_ SG_ 2331595788 NR_FR_Object_07_ExistProb "The signal indicates the existence probability of the object.";
CM_ SG_ 2331595788 NR_FR_Object_07_ID "Signal indicates the ID of the object.";
CM_ SG_ 2331595788 NR_FR_Object_07_Length "The signal indicates the length of the object.";
CM_ SG_ 2331595788 NR_FR_Object_07_LengthSD "The signal indicates the standard deviation of the length of the object.";
CM_ SG_ 2331595788 NR_FR_Object_07_MeasurementState "The signal indicates whether the object was measured in the current cycle.";
CM_ SG_ 2331595788 NR_FR_Object_07_PosX "Object X position in UKS";
CM_ SG_ 2331595788 NR_FR_Object_07_PosXSD "The signal indicates the standard deviation of the X position";
CM_ SG_ 2331595788 NR_FR_Object_07_PosY "Object Y position in UKS";
CM_ SG_ 2331595788 NR_FR_Object_07_PosYSD "The signal indicates the standard deviation of the Y position";
CM_ SG_ 2331595788 NR_FR_Object_07_ReferencePoint "Reference Point of the Object";
CM_ SG_ 2331595788 NR_FR_Object_07_vAbsX "The signal indicates the velocity in X direction";
CM_ SG_ 2331595788 NR_FR_Object_07_vAbsXSD "The signal indicates the standard deviation of the velocity in X direction";
CM_ SG_ 2331595788 NR_FR_Object_07_vAbsY "The signal indicates the velocity in Y direction.";
CM_ SG_ 2331595788 NR_FR_Object_07_vAbsYSD "The signal indicates the standard deviation of the velocity in Y direction.";
CM_ SG_ 2331595788 NR_FR_Object_07_Width "The signal indicates the width of the object.";
CM_ SG_ 2331595788 NR_FR_Object_07_WidthSD "The signal indicates the standard deviation of the width of the object.";
CM_ SG_ 2331595788 NR_FR_Object_07_YawAngle "The signal indicates the yaw angle of the object relative to the UKS.";
CM_ SG_ 2331595788 NR_FR_Object_07_YawAngleSD "The signal indicates the standard deviation to the yaw angle.";
CM_ SG_ 2331595788 NR_FR_Object_07_YawRateAbs "The signal indicates the yaw rate of the object relative to the UKS.";
CM_ SG_ 2331595788 NR_FR_Object_07_YawRateAbsSD "The signal indicates the standard deviation to the yaw rate.";
CM_ SG_ 2331595788 NR_FR_Object_08_aAbsX "The signal indicates the absolute acceleration of the object in the X direction.";
CM_ SG_ 2331595788 NR_FR_Object_08_aAbsXSD "The signal indicates the standard deviation of the absolute acceleration of the object in the X direction.";
CM_ SG_ 2331595788 NR_FR_Object_08_aAbsY "The signal indicates the absolute acceleration of the object in the Y direction.";
CM_ SG_ 2331595788 NR_FR_Object_08_aAbsYSD "The signal indicates the standard deviation of the absolute acceleration of the object in the Y direction.";
CM_ SG_ 2331595788 NR_FR_Object_08_Age "The signal indicates the age of the object. How long has the object been seen";
CM_ SG_ 2331595788 NR_FR_Object_08_Class "The signal indicates the object class.";
CM_ SG_ 2331595788 NR_FR_Object_08_ClassPlausib "The signal indicates the plausibility of the object class.";
CM_ SG_ 2331595788 NR_FR_Object_08_DynamicState "The signal indicates the motion state of the object.";
CM_ SG_ 2331595788 NR_FR_Object_08_ExistProb "The signal indicates the existence probability of the object.";
CM_ SG_ 2331595788 NR_FR_Object_08_ID "Signal indicates the ID of the object.";
CM_ SG_ 2331595788 NR_FR_Object_08_Length "The signal indicates the length of the object.";
CM_ SG_ 2331595788 NR_FR_Object_08_LengthSD "The signal indicates the standard deviation of the length of the object.";
CM_ SG_ 2331595788 NR_FR_Object_08_MeasurementState "The signal indicates whether the object was measured in the current cycle.";
CM_ SG_ 2331595788 NR_FR_Object_08_PosX "Object X position in UKS";
CM_ SG_ 2331595788 NR_FR_Object_08_PosXSD "The signal indicates the standard deviation of the X position";
CM_ SG_ 2331595788 NR_FR_Object_08_PosY "Object Y position in UKS";
CM_ SG_ 2331595788 NR_FR_Object_08_PosYSD "The signal indicates the standard deviation of the Y position";
CM_ SG_ 2331595788 NR_FR_Object_08_ReferencePoint "Reference Point of the Object";
CM_ SG_ 2331595788 NR_FR_Object_08_vAbsX "The signal indicates the velocity in X direction";
CM_ SG_ 2331595788 NR_FR_Object_08_vAbsXSD "The signal indicates the standard deviation of the velocity in X direction";
CM_ SG_ 2331595788 NR_FR_Object_08_vAbsY "The signal indicates the velocity in Y direction.";
CM_ SG_ 2331595788 NR_FR_Object_08_vAbsYSD "The signal indicates the standard deviation of the velocity in Y direction.";
CM_ SG_ 2331595788 NR_FR_Object_08_Width "The signal indicates the width of the object.";
CM_ SG_ 2331595788 NR_FR_Object_08_WidthSD "The signal indicates the standard deviation of the width of the object.";
CM_ SG_ 2331595788 NR_FR_Object_08_YawAngle "The signal indicates the yaw angle of the object relative to the UKS.";
CM_ SG_ 2331595788 NR_FR_Object_08_YawAngleSD "The signal indicates the standard deviation to the yaw angle.";
CM_ SG_ 2331595788 NR_FR_Object_08_YawRateAbs "The signal indicates the yaw rate of the object relative to the UKS.";
CM_ SG_ 2331595788 NR_FR_Object_08_YawRateAbsSD "The signal indicates the standard deviation to the yaw rate.";
CM_ SG_ 2331595788 SOK_NR_FR_Object_07_08_Signatur "Signatur im Rahmen der durch SOK geschützen Broadcast-Kommunikation
";
BA_DEF_REL_ BU_SG_REL_  "GenSigTimeoutTime" INT 0 65535;
BA_DEF_ BO_  "DiagRequest" ENUM "No", "Yes";
BA_DEF_ BO_  "DiagResponse" ENUM "No", "Yes";
BA_DEF_ BO_  "DiagState" ENUM "No", "Yes";
BA_DEF_ BO_  "GenMsgChkConstant" HEX 0 4095;
BA_DEF_ BO_  "GenMsgCycleTime" INT 0 65535;
BA_DEF_ BO_  "GenMsgCycleTimeFast" INT 0 65535;
BA_DEF_ BO_  "GenMsgDelayTime" INT 0 100000;
BA_DEF_ BO_  "GenMsgILSupport" ENUM "No", "Yes";
BA_DEF_ BO_  "GenMsgNrOfRepetition" INT 0 100;
BA_DEF_ BO_  "GenMsgPDUConstants" STRING;
BA_DEF_ BO_  "GenMsgSendType" ENUM "Cyclic", "not_used", "not_used", "not_used", "not_used", "not_used", "not_used", "IfActive", "NoMsgSendType";
BA_DEF_ BO_  "GenMsgStartDelayTime" INT 0 100000;
BA_DEF_ BO_  "NmMessage" ENUM "No", "Yes";
BA_DEF_ BO_  "NmhMessage" ENUM "No", "Yes";
BA_DEF_ BO_  "MsgType" ENUM "Application", "NM ", "NMH", "TP2.0", "ISO-TP ", "BAP", "EID", "KS", "XCP_PRE_CONFIGURED", "XCP_RUNTIME_CONFIGURED";
BA_DEF_ BO_  "VAGTP20_API" HEX 0 255;
BA_DEF_ BO_  "VAGTP20_DynConnection" ENUM "No", "Yes";
BA_DEF_ BO_  "VAGTP20_DynSetup" ENUM "No", "Yes";
BA_DEF_ BO_  "VAGTP20_StatConnection" ENUM "No", "Yes";
BA_DEF_ BO_  "CANFD_BRS" ENUM "0", "1";
BA_DEF_ BO_  "VFrameFormat" ENUM "StandardCAN", "ExtendedCAN", "reserved", "reserved", "reserved", "reserved", "reserved", "reserved", "reserved", "reserved", "reserved", "reserved", "reserved", "reserved", "StandardCAN_FD", "ExtendedCAN_FD";
BA_DEF_ SG_  "GenSigActiveRepetitions" INT -2147483648 2147483647;
BA_DEF_ SG_  "GenSigInactiveValue" INT -2147483648 2147483647;
BA_DEF_ SG_  "GenSigSendType" ENUM "Cyclic", "OnWrite", "OnWriteWithRepetition", "OnChange", "OnChangeWithRepetition", "IfActive", "IfActiveWithRepetition", "NoSigSendType", "OnChangeAndIfActive", "OnChangeAndIfActiveWithRepetition";
BA_DEF_ SG_  "GenSigStartValue" INT -2147483648 2147483647;
BA_DEF_ SG_  "NWM-WakeupAllowed" ENUM "No", "Yes";
BA_DEF_ SG_  "GenSigFuncType" ENUM "NoFunction", "MsgCounter", "CRC-8", "XOR", "XOR-2", "DatedBit", "SW-Kl15", "CHK", "Constant", "Protocol", "CRC-8-SAE_J1850", "CRC-32", "DataLength", "DataID", "MsgCounter16", "SOK-Signatur", "Cluster";
BA_DEF_ SG_  "GenSigSwitchedByIgnition" ENUM "No", "Yes";
BA_DEF_ SG_  "Fehlerwert" HEX 0 2147483647;
BA_DEF_ SG_  "GenSigMissingSourceValue" HEX 0 2147483647;
BA_DEF_DEF_REL_  "GenSigTimeoutTime" 0;
BA_DEF_DEF_  "DiagRequest" "No";
BA_DEF_DEF_  "DiagResponse" "No";
BA_DEF_DEF_  "DiagState" "No";
BA_DEF_DEF_  "GenMsgChkConstant" 0;
BA_DEF_DEF_  "GenMsgCycleTime" 0;
BA_DEF_DEF_  "GenMsgCycleTimeFast" 0;
BA_DEF_DEF_  "GenMsgDelayTime" 0;
BA_DEF_DEF_  "GenMsgILSupport" "No";
BA_DEF_DEF_  "GenMsgNrOfRepetition" 0;
BA_DEF_DEF_  "GenMsgPDUConstants" "";
BA_DEF_DEF_  "GenMsgSendType" "NoMsgSendType";
BA_DEF_DEF_  "GenMsgStartDelayTime" 0;
BA_DEF_DEF_  "NmMessage" "No";
BA_DEF_DEF_  "NmhMessage" "No";
BA_DEF_DEF_  "MsgType" "Application";
BA_DEF_DEF_  "VAGTP20_API" 0;
BA_DEF_DEF_  "VAGTP20_DynConnection" "No";
BA_DEF_DEF_  "VAGTP20_DynSetup" "No";
BA_DEF_DEF_  "VAGTP20_StatConnection" "No";
BA_DEF_DEF_  "CANFD_BRS" "1";
BA_DEF_DEF_  "VFrameFormat" "StandardCAN";
BA_DEF_DEF_  "GenSigActiveRepetitions" 0;
BA_DEF_DEF_  "GenSigInactiveValue" 0;
BA_DEF_DEF_  "GenSigSendType" "NoSigSendType";
BA_DEF_DEF_  "GenSigStartValue" 0;
BA_DEF_DEF_  "NWM-WakeupAllowed" "No";
BA_DEF_DEF_  "GenSigFuncType" "NoFunction";
BA_DEF_DEF_  "GenSigSwitchedByIgnition" "Yes";
BA_DEF_DEF_  "Fehlerwert" 0;
BA_DEF_DEF_  "GenSigMissingSourceValue" 0;
BA_ "GenMsgCycleTime" BO_ 2331595780 50;
BA_ "GenMsgILSupport" BO_ 2331595780 1;
BA_ "GenMsgPDUConstants" BO_ 2331595780 "0x08,0xe6,0xd9,0x58,0x2a,0xed,0x72,0xb7,0xb6,0xcc,0xd2,0x03,0x43,0xf2,0xa2,0x85";
BA_ "GenMsgSendType" BO_ 2331595780 0;
BA_ "VFrameFormat" BO_ 2331595780 15;
BA_ "GenMsgCycleTime" BO_ 2589284096 2000;
BA_ "GenMsgILSupport" BO_ 2589284096 1;
BA_ "GenMsgSendType" BO_ 2589284096 0;
BA_ "VFrameFormat" BO_ 2589284096 15;
BA_ "GenMsgCycleTime" BO_ 2331595852 50;
BA_ "GenMsgILSupport" BO_ 2331595852 1;
BA_ "GenMsgSendType" BO_ 2331595852 0;
BA_ "VFrameFormat" BO_ 2331595852 15;
BA_ "GenMsgCycleTime" BO_ 2264486976 1000;
BA_ "GenMsgILSupport" BO_ 2264486976 1;
BA_ "GenMsgSendType" BO_ 2264486976 0;
BA_ "VFrameFormat" BO_ 2264486976 15;
BA_ "GenMsgCycleTime" BO_ 2264486980 1000;
BA_ "GenMsgILSupport" BO_ 2264486980 1;
BA_ "GenMsgSendType" BO_ 2264486980 0;
BA_ "VFrameFormat" BO_ 2264486980 15;
BA_ "GenMsgCycleTime" BO_ 2264486985 50;
BA_ "GenMsgILSupport" BO_ 2264486985 1;
BA_ "GenMsgSendType" BO_ 2264486985 0;
BA_ "VFrameFormat" BO_ 2264486985 15;
BA_ "GenMsgCycleTime" BO_ 2331595826 50;
BA_ "GenMsgILSupport" BO_ 2331595826 1;
BA_ "GenMsgSendType" BO_ 2331595826 0;
BA_ "VFrameFormat" BO_ 2331595826 15;
BA_ "GenMsgCycleTime" BO_ 2331595791 50;
BA_ "GenMsgILSupport" BO_ 2331595791 1;
BA_ "GenMsgPDUConstants" BO_ 2331595791 "0x87,0x5d,0xbe,0x88,0xf9,0x17,0x0a,0x84,0x52,0xce,0xeb,0x1d,0x1c,0x1f,0xc4,0x01";
BA_ "GenMsgSendType" BO_ 2331595791 0;
BA_ "VFrameFormat" BO_ 2331595791 15;
BA_ "GenMsgCycleTime" BO_ 2331595782 50;
BA_ "GenMsgILSupport" BO_ 2331595782 1;
BA_ "GenMsgPDUConstants" BO_ 2331595782 "0xe0,0x30,0x5a,0xf5,0xe6,0x04,0x6b,0x10,0xdb,0x58,0x21,0x4c,0x7c,0x3e,0xed,0xaa";
BA_ "GenMsgSendType" BO_ 2331595782 0;
BA_ "VFrameFormat" BO_ 2331595782 15;
BA_ "GenMsgCycleTime" BO_ 2331595785 50;
BA_ "GenMsgILSupport" BO_ 2331595785 1;
BA_ "GenMsgPDUConstants" BO_ 2331595785 "0x9d,0xe8,0x36,0xa1,0xca,0x3b,0x1d,0x33,0xe0,0xd5,0xbb,0x5f,0xae,0x3c,0x31,0x9f";
BA_ "GenMsgSendType" BO_ 2331595785 0;
BA_ "VFrameFormat" BO_ 2331595785 15;
BA_ "GenMsgCycleTime" BO_ 2331595786 50;
BA_ "GenMsgILSupport" BO_ 2331595786 1;
BA_ "GenMsgPDUConstants" BO_ 2331595786 "0x20,0xca,0x68,0xd5,0x1b,0x31,0xe2,0xda,0x08,0x0a,0xd4,0xde,0x9c,0xe4,0x35,0x5b";
BA_ "GenMsgSendType" BO_ 2331595786 0;
BA_ "VFrameFormat" BO_ 2331595786 15;
BA_ "GenMsgCycleTime" BO_ 2331595787 50;
BA_ "GenMsgILSupport" BO_ 2331595787 1;
BA_ "GenMsgPDUConstants" BO_ 2331595787 "0x57,0xa4,0x22,0x05,0x9d,0x80,0xba,0xaf,0x1e,0xe8,0x2c,0xd4,0x92,0xec,0x36,0x50";
BA_ "GenMsgSendType" BO_ 2331595787 0;
BA_ "VFrameFormat" BO_ 2331595787 15;
BA_ "GenMsgCycleTime" BO_ 2331595788 50;
BA_ "GenMsgILSupport" BO_ 2331595788 1;
BA_ "GenMsgPDUConstants" BO_ 2331595788 "0x3a,0x08,0xf7,0xe6,0x59,0xd9,0x9f,0x58,0xe9,0x2a,0xdd,0xed,0x55,0x72,0x0e,0xb7";
BA_ "GenMsgSendType" BO_ 2331595788 0;
BA_ "VFrameFormat" BO_ 2331595788 15;
BA_ "GenSigSendType" SG_ 2331595780 NR_FL_Object_09_10_BlockID_01 0;
BA_ "GenSigSendType" SG_ 2331595780 NR_FL_Object_09_10_BZ 0;
BA_ "GenSigFuncType" SG_ 2331595780 NR_FL_Object_09_10_BZ 1;
BA_ "GenSigSwitchedByIgnition" SG_ 2331595780 NR_FL_Object_09_10_BZ 0;
BA_ "GenSigSendType" SG_ 2331595780 NR_FL_Object_09_10_CRC 0;
BA_ "GenSigFuncType" SG_ 2331595780 NR_FL_Object_09_10_CRC 2;
BA_ "GenSigSwitchedByIgnition" SG_ 2331595780 NR_FL_Object_09_10_CRC 0;
BA_ "GenSigSendType" SG_ 2331595780 NR_FL_Object_09_aAbsX 0;
BA_ "GenSigStartValue" SG_ 2331595780 NR_FL_Object_09_aAbsX 511;
BA_ "GenSigSendType" SG_ 2331595780 NR_FL_Object_09_aAbsXSD 0;
BA_ "GenSigStartValue" SG_ 2331595780 NR_FL_Object_09_aAbsXSD 63;
BA_ "GenSigSendType" SG_ 2331595780 NR_FL_Object_09_aAbsY 0;
BA_ "GenSigStartValue" SG_ 2331595780 NR_FL_Object_09_aAbsY 511;
BA_ "GenSigSendType" SG_ 2331595780 NR_FL_Object_09_aAbsYSD 0;
BA_ "GenSigStartValue" SG_ 2331595780 NR_FL_Object_09_aAbsYSD 63;
BA_ "GenSigSendType" SG_ 2331595780 NR_FL_Object_09_Age 0;
BA_ "GenSigStartValue" SG_ 2331595780 NR_FL_Object_09_Age 127;
BA_ "GenSigSendType" SG_ 2331595780 NR_FL_Object_09_Class 0;
BA_ "GenSigStartValue" SG_ 2331595780 NR_FL_Object_09_Class 15;
BA_ "GenSigSendType" SG_ 2331595780 NR_FL_Object_09_ClassPlausib 0;
BA_ "GenSigStartValue" SG_ 2331595780 NR_FL_Object_09_ClassPlausib 15;
BA_ "GenSigSendType" SG_ 2331595780 NR_FL_Object_09_DynamicState 0;
BA_ "GenSigStartValue" SG_ 2331595780 NR_FL_Object_09_DynamicState 3;
BA_ "GenSigSendType" SG_ 2331595780 NR_FL_Object_09_ExistProb 0;
BA_ "GenSigStartValue" SG_ 2331595780 NR_FL_Object_09_ExistProb 127;
BA_ "GenSigSendType" SG_ 2331595780 NR_FL_Object_09_ID 0;
BA_ "GenSigStartValue" SG_ 2331595780 NR_FL_Object_09_ID 255;
BA_ "GenSigSendType" SG_ 2331595780 NR_FL_Object_09_Length 0;
BA_ "GenSigStartValue" SG_ 2331595780 NR_FL_Object_09_Length 1023;
BA_ "GenSigSendType" SG_ 2331595780 NR_FL_Object_09_LengthSD 0;
BA_ "GenSigStartValue" SG_ 2331595780 NR_FL_Object_09_LengthSD 127;
BA_ "GenSigSendType" SG_ 2331595780 NR_FL_Object_09_MeasurementState 0;
BA_ "GenSigSendType" SG_ 2331595780 NR_FL_Object_09_PosX 0;
BA_ "GenSigStartValue" SG_ 2331595780 NR_FL_Object_09_PosX 16383;
BA_ "GenSigSendType" SG_ 2331595780 NR_FL_Object_09_PosXSD 0;
BA_ "GenSigStartValue" SG_ 2331595780 NR_FL_Object_09_PosXSD 255;
BA_ "GenSigSendType" SG_ 2331595780 NR_FL_Object_09_PosY 0;
BA_ "GenSigStartValue" SG_ 2331595780 NR_FL_Object_09_PosY 8191;
BA_ "GenSigSendType" SG_ 2331595780 NR_FL_Object_09_PosYSD 0;
BA_ "GenSigStartValue" SG_ 2331595780 NR_FL_Object_09_PosYSD 255;
BA_ "GenSigSendType" SG_ 2331595780 NR_FL_Object_09_ReferencePoint 0;
BA_ "GenSigStartValue" SG_ 2331595780 NR_FL_Object_09_ReferencePoint 15;
BA_ "GenSigSendType" SG_ 2331595780 NR_FL_Object_09_vAbsX 0;
BA_ "GenSigStartValue" SG_ 2331595780 NR_FL_Object_09_vAbsX 4095;
BA_ "GenSigSendType" SG_ 2331595780 NR_FL_Object_09_vAbsXSD 0;
BA_ "GenSigStartValue" SG_ 2331595780 NR_FL_Object_09_vAbsXSD 63;
BA_ "GenSigSendType" SG_ 2331595780 NR_FL_Object_09_vAbsY 0;
BA_ "GenSigStartValue" SG_ 2331595780 NR_FL_Object_09_vAbsY 4095;
BA_ "GenSigSendType" SG_ 2331595780 NR_FL_Object_09_vAbsYSD 0;
BA_ "GenSigStartValue" SG_ 2331595780 NR_FL_Object_09_vAbsYSD 63;
BA_ "GenSigSendType" SG_ 2331595780 NR_FL_Object_09_Width 0;
BA_ "GenSigStartValue" SG_ 2331595780 NR_FL_Object_09_Width 255;
BA_ "GenSigSendType" SG_ 2331595780 NR_FL_Object_09_WidthSD 0;
BA_ "GenSigStartValue" SG_ 2331595780 NR_FL_Object_09_WidthSD 127;
BA_ "GenSigSendType" SG_ 2331595780 NR_FL_Object_09_YawAngle 0;
BA_ "GenSigStartValue" SG_ 2331595780 NR_FL_Object_09_YawAngle 4095;
BA_ "GenSigSendType" SG_ 2331595780 NR_FL_Object_09_YawAngleSD 0;
BA_ "GenSigStartValue" SG_ 2331595780 NR_FL_Object_09_YawAngleSD 511;
BA_ "GenSigSendType" SG_ 2331595780 NR_FL_Object_09_YawRateAbs 0;
BA_ "GenSigStartValue" SG_ 2331595780 NR_FL_Object_09_YawRateAbs 4095;
BA_ "GenSigSendType" SG_ 2331595780 NR_FL_Object_09_YawRateAbsSD 0;
BA_ "GenSigStartValue" SG_ 2331595780 NR_FL_Object_09_YawRateAbsSD 63;
BA_ "GenSigSendType" SG_ 2331595780 NR_FL_Object_10_aAbsX 0;
BA_ "GenSigStartValue" SG_ 2331595780 NR_FL_Object_10_aAbsX 511;
BA_ "GenSigSendType" SG_ 2331595780 NR_FL_Object_10_aAbsXSD 0;
BA_ "GenSigStartValue" SG_ 2331595780 NR_FL_Object_10_aAbsXSD 63;
BA_ "GenSigSendType" SG_ 2331595780 NR_FL_Object_10_aAbsY 0;
BA_ "GenSigStartValue" SG_ 2331595780 NR_FL_Object_10_aAbsY 511;
BA_ "GenSigSendType" SG_ 2331595780 NR_FL_Object_10_aAbsYSD 0;
BA_ "GenSigStartValue" SG_ 2331595780 NR_FL_Object_10_aAbsYSD 63;
BA_ "GenSigSendType" SG_ 2331595780 NR_FL_Object_10_Age 0;
BA_ "GenSigStartValue" SG_ 2331595780 NR_FL_Object_10_Age 127;
BA_ "GenSigSendType" SG_ 2331595780 NR_FL_Object_10_Class 0;
BA_ "GenSigStartValue" SG_ 2331595780 NR_FL_Object_10_Class 15;
BA_ "GenSigSendType" SG_ 2331595780 NR_FL_Object_10_ClassPlausib 0;
BA_ "GenSigStartValue" SG_ 2331595780 NR_FL_Object_10_ClassPlausib 15;
BA_ "GenSigSendType" SG_ 2331595780 NR_FL_Object_10_DynamicState 0;
BA_ "GenSigStartValue" SG_ 2331595780 NR_FL_Object_10_DynamicState 3;
BA_ "GenSigSendType" SG_ 2331595780 NR_FL_Object_10_ExistProb 0;
BA_ "GenSigStartValue" SG_ 2331595780 NR_FL_Object_10_ExistProb 127;
BA_ "GenSigSendType" SG_ 2331595780 NR_FL_Object_10_ID 0;
BA_ "GenSigStartValue" SG_ 2331595780 NR_FL_Object_10_ID 255;
BA_ "GenSigSendType" SG_ 2331595780 NR_FL_Object_10_Length 0;
BA_ "GenSigStartValue" SG_ 2331595780 NR_FL_Object_10_Length 1023;
BA_ "GenSigSendType" SG_ 2331595780 NR_FL_Object_10_LengthSD 0;
BA_ "GenSigStartValue" SG_ 2331595780 NR_FL_Object_10_LengthSD 127;
BA_ "GenSigSendType" SG_ 2331595780 NR_FL_Object_10_MeasurementState 0;
BA_ "GenSigSendType" SG_ 2331595780 NR_FL_Object_10_PosX 0;
BA_ "GenSigStartValue" SG_ 2331595780 NR_FL_Object_10_PosX 16383;
BA_ "GenSigSendType" SG_ 2331595780 NR_FL_Object_10_PosXSD 0;
BA_ "GenSigStartValue" SG_ 2331595780 NR_FL_Object_10_PosXSD 255;
BA_ "GenSigSendType" SG_ 2331595780 NR_FL_Object_10_PosY 0;
BA_ "GenSigStartValue" SG_ 2331595780 NR_FL_Object_10_PosY 8191;
BA_ "GenSigSendType" SG_ 2331595780 NR_FL_Object_10_PosYSD 0;
BA_ "GenSigStartValue" SG_ 2331595780 NR_FL_Object_10_PosYSD 255;
BA_ "GenSigSendType" SG_ 2331595780 NR_FL_Object_10_ReferencePoint 0;
BA_ "GenSigStartValue" SG_ 2331595780 NR_FL_Object_10_ReferencePoint 15;
BA_ "GenSigSendType" SG_ 2331595780 NR_FL_Object_10_vAbsX 0;
BA_ "GenSigStartValue" SG_ 2331595780 NR_FL_Object_10_vAbsX 4095;
BA_ "GenSigSendType" SG_ 2331595780 NR_FL_Object_10_vAbsXSD 0;
BA_ "GenSigStartValue" SG_ 2331595780 NR_FL_Object_10_vAbsXSD 63;
BA_ "GenSigSendType" SG_ 2331595780 NR_FL_Object_10_vAbsY 0;
BA_ "GenSigStartValue" SG_ 2331595780 NR_FL_Object_10_vAbsY 4095;
BA_ "GenSigSendType" SG_ 2331595780 NR_FL_Object_10_vAbsYSD 0;
BA_ "GenSigStartValue" SG_ 2331595780 NR_FL_Object_10_vAbsYSD 63;
BA_ "GenSigSendType" SG_ 2331595780 NR_FL_Object_10_Width 0;
BA_ "GenSigStartValue" SG_ 2331595780 NR_FL_Object_10_Width 255;
BA_ "GenSigSendType" SG_ 2331595780 NR_FL_Object_10_WidthSD 0;
BA_ "GenSigStartValue" SG_ 2331595780 NR_FL_Object_10_WidthSD 127;
BA_ "GenSigSendType" SG_ 2331595780 NR_FL_Object_10_YawAngle 0;
BA_ "GenSigStartValue" SG_ 2331595780 NR_FL_Object_10_YawAngle 4095;
BA_ "GenSigSendType" SG_ 2331595780 NR_FL_Object_10_YawAngleSD 0;
BA_ "GenSigStartValue" SG_ 2331595780 NR_FL_Object_10_YawAngleSD 511;
BA_ "GenSigSendType" SG_ 2331595780 NR_FL_Object_10_YawRateAbs 0;
BA_ "GenSigStartValue" SG_ 2331595780 NR_FL_Object_10_YawRateAbs 4095;
BA_ "GenSigSendType" SG_ 2331595780 NR_FL_Object_10_YawRateAbsSD 0;
BA_ "GenSigStartValue" SG_ 2331595780 NR_FL_Object_10_YawRateAbsSD 63;
BA_ "GenSigSendType" SG_ 2331595780 SOK_NR_FL_Object_09_10_Signatur 0;
BA_ "GenSigFuncType" SG_ 2331595780 SOK_NR_FL_Object_09_10_Signatur 15;
BA_ "GenSigSendType" SG_ 2589284096 DS_FL_StructureVersion_1 0;
BA_ "GenSigSwitchedByIgnition" SG_ 2589284096 DS_FL_StructureVersion_1 0;
BA_ "GenSigSendType" SG_ 2589284096 DS_FL_StructureVersion_2 0;
BA_ "GenSigSwitchedByIgnition" SG_ 2589284096 DS_FL_StructureVersion_2 0;
BA_ "GenSigSendType" SG_ 2589284096 NR_FL_HW_Version 0;
BA_ "GenSigSendType" SG_ 2589284096 NR_FL_SerialNumber 0;
BA_ "GenSigSendType" SG_ 2589284096 NR_FL_SW_Version 0;
BA_ "GenSigSendType" SG_ 2331595852 NR_FL_Structure_BlockID_01 0;
BA_ "GenSigSendType" SG_ 2331595852 NR_FL_Structure_left_ExistProb 0;
BA_ "GenSigStartValue" SG_ 2331595852 NR_FL_Structure_left_ExistProb 127;
BA_ "GenSigSendType" SG_ 2331595852 NR_FL_Structure_left_LatDist 0;
BA_ "GenSigStartValue" SG_ 2331595852 NR_FL_Structure_left_LatDist 511;
BA_ "GenSigSendType" SG_ 2331595852 NR_FL_Structure_left_Type 0;
BA_ "GenSigSendType" SG_ 2264486976 NR_FL_SyncCounter 0;
BA_ "GenSigSendType" SG_ 2264486976 NR_FL_SyncVersion 0;
BA_ "GenSigSendType" SG_ 2264486980 NR_FL_CounterValue 0;
BA_ "GenSigSendType" SG_ 2264486980 NR_FL_RandomSeed 0;
BA_ "GenSigSendType" SG_ 2264486980 NR_FL_Time_CorrectionField 0;
BA_ "GenSigSendType" SG_ 2264486980 NR_FL_Time_HighPrecision 0;
BA_ "GenSigSendType" SG_ 2264486980 NR_FL_Time_LowPrecision 0;
BA_ "GenSigSendType" SG_ 2264486985 NR_FL_EarliestStartTime 0;
BA_ "GenSigSendType" SG_ 2264486985 NR_FL_InteferenceInfo 0;
BA_ "GenSigSendType" SG_ 2264486985 NR_FL_LatestSyncCounter 0;
BA_ "GenSigSendType" SG_ 2264486985 NR_FL_RequestedModulation 0;
BA_ "GenSigSendType" SG_ 2264486985 NR_FL_SyncCycleCount 0;
BA_ "GenSigSendType" SG_ 2264486985 NR_FL_SyncReadyVersion 0;
BA_ "GenSigSendType" SG_ 2331595826 NR_FR_Cal_resp 0;
BA_ "GenSigSendType" SG_ 2331595826 NR_FR_CalibrationMode 0;
BA_ "GenSigSendType" SG_ 2331595826 NR_FR_QualFactorAutoCalib 0;
BA_ "GenSigSendType" SG_ 2331595826 NR_FR_resp_val 0;
BA_ "GenSigSendType" SG_ 2331595826 NR_FR_ShortTrackCal_State 0;
BA_ "GenSigStartValue" SG_ 2331595826 NR_FR_ShortTrackCal_State 7;
BA_ "GenSigSendType" SG_ 2331595791 NR_FR_Contour_BlockID_02 0;
BA_ "GenSigSendType" SG_ 2331595791 NR_FR_Contour_BZ 0;
BA_ "GenSigFuncType" SG_ 2331595791 NR_FR_Contour_BZ 1;
BA_ "GenSigSwitchedByIgnition" SG_ 2331595791 NR_FR_Contour_BZ 0;
BA_ "GenSigSendType" SG_ 2331595791 NR_FR_Contour_CRC 0;
BA_ "GenSigFuncType" SG_ 2331595791 NR_FR_Contour_CRC 2;
BA_ "GenSigSwitchedByIgnition" SG_ 2331595791 NR_FR_Contour_CRC 0;
BA_ "GenSigSendType" SG_ 2331595791 NR_FR_Contour_right_01_Age 0;
BA_ "GenSigStartValue" SG_ 2331595791 NR_FR_Contour_right_01_Age 127;
BA_ "GenSigSendType" SG_ 2331595791 NR_FR_Contour_right_01_Type 0;
BA_ "GenSigStartValue" SG_ 2331595791 NR_FR_Contour_right_01_Type 7;
BA_ "GenSigSendType" SG_ 2331595791 NR_FR_Contour_right_01_x01 0;
BA_ "GenSigStartValue" SG_ 2331595791 NR_FR_Contour_right_01_x01 8191;
BA_ "GenSigSendType" SG_ 2331595791 NR_FR_Contour_right_01_x02 0;
BA_ "GenSigStartValue" SG_ 2331595791 NR_FR_Contour_right_01_x02 8191;
BA_ "GenSigSendType" SG_ 2331595791 NR_FR_Contour_right_01_x03 0;
BA_ "GenSigStartValue" SG_ 2331595791 NR_FR_Contour_right_01_x03 8191;
BA_ "GenSigSendType" SG_ 2331595791 NR_FR_Contour_right_01_x04 0;
BA_ "GenSigStartValue" SG_ 2331595791 NR_FR_Contour_right_01_x04 8191;
BA_ "GenSigSendType" SG_ 2331595791 NR_FR_Contour_right_01_x05 0;
BA_ "GenSigStartValue" SG_ 2331595791 NR_FR_Contour_right_01_x05 8191;
BA_ "GenSigSendType" SG_ 2331595791 NR_FR_Contour_right_01_x06 0;
BA_ "GenSigStartValue" SG_ 2331595791 NR_FR_Contour_right_01_x06 8191;
BA_ "GenSigSendType" SG_ 2331595791 NR_FR_Contour_right_01_x07 0;
BA_ "GenSigStartValue" SG_ 2331595791 NR_FR_Contour_right_01_x07 8191;
BA_ "GenSigSendType" SG_ 2331595791 NR_FR_Contour_right_01_y01 0;
BA_ "GenSigStartValue" SG_ 2331595791 NR_FR_Contour_right_01_y01 2047;
BA_ "GenSigSendType" SG_ 2331595791 NR_FR_Contour_right_01_y02 0;
BA_ "GenSigStartValue" SG_ 2331595791 NR_FR_Contour_right_01_y02 2047;
BA_ "GenSigSendType" SG_ 2331595791 NR_FR_Contour_right_01_y03 0;
BA_ "GenSigStartValue" SG_ 2331595791 NR_FR_Contour_right_01_y03 2047;
BA_ "GenSigSendType" SG_ 2331595791 NR_FR_Contour_right_01_y04 0;
BA_ "GenSigStartValue" SG_ 2331595791 NR_FR_Contour_right_01_y04 2047;
BA_ "GenSigSendType" SG_ 2331595791 NR_FR_Contour_right_01_y05 0;
BA_ "GenSigStartValue" SG_ 2331595791 NR_FR_Contour_right_01_y05 2047;
BA_ "GenSigSendType" SG_ 2331595791 NR_FR_Contour_right_01_y06 0;
BA_ "GenSigStartValue" SG_ 2331595791 NR_FR_Contour_right_01_y06 2047;
BA_ "GenSigSendType" SG_ 2331595791 NR_FR_Contour_right_01_y07 0;
BA_ "GenSigStartValue" SG_ 2331595791 NR_FR_Contour_right_01_y07 2047;
BA_ "GenSigSendType" SG_ 2331595791 NR_FR_Contour_right_02_Age 0;
BA_ "GenSigStartValue" SG_ 2331595791 NR_FR_Contour_right_02_Age 127;
BA_ "GenSigSendType" SG_ 2331595791 NR_FR_Contour_right_02_Type 0;
BA_ "GenSigStartValue" SG_ 2331595791 NR_FR_Contour_right_02_Type 7;
BA_ "GenSigSendType" SG_ 2331595791 NR_FR_Contour_right_02_x01 0;
BA_ "GenSigStartValue" SG_ 2331595791 NR_FR_Contour_right_02_x01 8191;
BA_ "GenSigSendType" SG_ 2331595791 NR_FR_Contour_right_02_x02 0;
BA_ "GenSigStartValue" SG_ 2331595791 NR_FR_Contour_right_02_x02 8191;
BA_ "GenSigSendType" SG_ 2331595791 NR_FR_Contour_right_02_x03 0;
BA_ "GenSigStartValue" SG_ 2331595791 NR_FR_Contour_right_02_x03 8191;
BA_ "GenSigSendType" SG_ 2331595791 NR_FR_Contour_right_02_x04 0;
BA_ "GenSigStartValue" SG_ 2331595791 NR_FR_Contour_right_02_x04 8191;
BA_ "GenSigSendType" SG_ 2331595791 NR_FR_Contour_right_02_x05 0;
BA_ "GenSigStartValue" SG_ 2331595791 NR_FR_Contour_right_02_x05 8191;
BA_ "GenSigSendType" SG_ 2331595791 NR_FR_Contour_right_02_x06 0;
BA_ "GenSigStartValue" SG_ 2331595791 NR_FR_Contour_right_02_x06 8191;
BA_ "GenSigSendType" SG_ 2331595791 NR_FR_Contour_right_02_x07 0;
BA_ "GenSigStartValue" SG_ 2331595791 NR_FR_Contour_right_02_x07 8191;
BA_ "GenSigSendType" SG_ 2331595791 NR_FR_Contour_right_02_y01 0;
BA_ "GenSigStartValue" SG_ 2331595791 NR_FR_Contour_right_02_y01 2047;
BA_ "GenSigSendType" SG_ 2331595791 NR_FR_Contour_right_02_y02 0;
BA_ "GenSigStartValue" SG_ 2331595791 NR_FR_Contour_right_02_y02 2047;
BA_ "GenSigSendType" SG_ 2331595791 NR_FR_Contour_right_02_y03 0;
BA_ "GenSigStartValue" SG_ 2331595791 NR_FR_Contour_right_02_y03 2047;
BA_ "GenSigSendType" SG_ 2331595791 NR_FR_Contour_right_02_y04 0;
BA_ "GenSigStartValue" SG_ 2331595791 NR_FR_Contour_right_02_y04 2047;
BA_ "GenSigSendType" SG_ 2331595791 NR_FR_Contour_right_02_y05 0;
BA_ "GenSigStartValue" SG_ 2331595791 NR_FR_Contour_right_02_y05 2047;
BA_ "GenSigSendType" SG_ 2331595791 NR_FR_Contour_right_02_y06 0;
BA_ "GenSigStartValue" SG_ 2331595791 NR_FR_Contour_right_02_y06 2047;
BA_ "GenSigSendType" SG_ 2331595791 NR_FR_Contour_right_02_y07 0;
BA_ "GenSigStartValue" SG_ 2331595791 NR_FR_Contour_right_02_y07 2047;
BA_ "GenSigSendType" SG_ 2331595791 NR_FR_Contour_right_Linkage 0;
BA_ "GenSigStartValue" SG_ 2331595791 NR_FR_Contour_right_Linkage 1;
BA_ "GenSigSendType" SG_ 2331595791 SOK_NR_FR_Contour_Signatur 0;
BA_ "GenSigFuncType" SG_ 2331595791 SOK_NR_FR_Contour_Signatur 15;
BA_ "GenSigSendType" SG_ 2331595782 NR_FR_Blindness 0;
BA_ "GenSigSendType" SG_ 2331595782 NR_FR_BlockID_02 0;
BA_ "GenSigSendType" SG_ 2331595782 NR_FR_CalibrationState 0;
BA_ "GenSigSendType" SG_ 2331595782 NR_FR_Failure 0;
BA_ "GenSigSendType" SG_ 2331595782 NR_FR_Freesight_NOK 0;
BA_ "GenSigSendType" SG_ 2331595782 NR_FR_Header_BZ 0;
BA_ "GenSigFuncType" SG_ 2331595782 NR_FR_Header_BZ 1;
BA_ "GenSigSwitchedByIgnition" SG_ 2331595782 NR_FR_Header_BZ 0;
BA_ "GenSigSendType" SG_ 2331595782 NR_FR_Header_CRC 0;
BA_ "GenSigFuncType" SG_ 2331595782 NR_FR_Header_CRC 2;
BA_ "GenSigSwitchedByIgnition" SG_ 2331595782 NR_FR_Header_CRC 0;
BA_ "GenSigSendType" SG_ 2331595782 NR_FR_MeasurementTimeHigh 0;
BA_ "GenSigSendType" SG_ 2331595782 NR_FR_MeasurementTimeLapNumber 0;
BA_ "Fehlerwert" SG_ 2331595782 NR_FR_MeasurementTimeLapNumber 16383;
BA_ "GenSigSendType" SG_ 2331595782 NR_FR_MeasurementTimeLow 0;
BA_ "GenSigSendType" SG_ 2331595782 NR_FR_MeasurementTimeStatus 0;
BA_ "GenSigSendType" SG_ 2331595782 NR_FR_NotAvailable 0;
BA_ "GenSigStartValue" SG_ 2331595782 NR_FR_NotAvailable 1;
BA_ "GenSigSendType" SG_ 2331595782 NR_FR_RangeDegradation_Sect1 0;
BA_ "GenSigSendType" SG_ 2331595782 NR_FR_RangeDegradation_Sect2 0;
BA_ "GenSigSendType" SG_ 2331595782 NR_FR_RangeDegradation_Sect3 0;
BA_ "GenSigSendType" SG_ 2331595782 SOK_NR_FR_Header_Signatur 0;
BA_ "GenSigFuncType" SG_ 2331595782 SOK_NR_FR_Header_Signatur 15;
BA_ "GenSigSendType" SG_ 2331595785 NR_FR_Object_01_02_BlockID_02 0;
BA_ "GenSigSendType" SG_ 2331595785 NR_FR_Object_01_02_BZ 0;
BA_ "GenSigFuncType" SG_ 2331595785 NR_FR_Object_01_02_BZ 1;
BA_ "GenSigSwitchedByIgnition" SG_ 2331595785 NR_FR_Object_01_02_BZ 0;
BA_ "GenSigSendType" SG_ 2331595785 NR_FR_Object_01_02_CRC 0;
BA_ "GenSigFuncType" SG_ 2331595785 NR_FR_Object_01_02_CRC 2;
BA_ "GenSigSwitchedByIgnition" SG_ 2331595785 NR_FR_Object_01_02_CRC 0;
BA_ "GenSigSendType" SG_ 2331595785 NR_FR_Object_01_aAbsX 0;
BA_ "GenSigStartValue" SG_ 2331595785 NR_FR_Object_01_aAbsX 511;
BA_ "GenSigSendType" SG_ 2331595785 NR_FR_Object_01_aAbsXSD 0;
BA_ "GenSigStartValue" SG_ 2331595785 NR_FR_Object_01_aAbsXSD 63;
BA_ "GenSigSendType" SG_ 2331595785 NR_FR_Object_01_aAbsY 0;
BA_ "GenSigStartValue" SG_ 2331595785 NR_FR_Object_01_aAbsY 511;
BA_ "GenSigSendType" SG_ 2331595785 NR_FR_Object_01_aAbsYSD 0;
BA_ "GenSigStartValue" SG_ 2331595785 NR_FR_Object_01_aAbsYSD 63;
BA_ "GenSigSendType" SG_ 2331595785 NR_FR_Object_01_Age 0;
BA_ "GenSigStartValue" SG_ 2331595785 NR_FR_Object_01_Age 127;
BA_ "GenSigSendType" SG_ 2331595785 NR_FR_Object_01_Class 0;
BA_ "GenSigStartValue" SG_ 2331595785 NR_FR_Object_01_Class 15;
BA_ "GenSigSendType" SG_ 2331595785 NR_FR_Object_01_ClassPlausib 0;
BA_ "GenSigStartValue" SG_ 2331595785 NR_FR_Object_01_ClassPlausib 15;
BA_ "GenSigSendType" SG_ 2331595785 NR_FR_Object_01_DynamicState 0;
BA_ "GenSigStartValue" SG_ 2331595785 NR_FR_Object_01_DynamicState 3;
BA_ "GenSigSendType" SG_ 2331595785 NR_FR_Object_01_ExistProb 0;
BA_ "GenSigStartValue" SG_ 2331595785 NR_FR_Object_01_ExistProb 127;
BA_ "GenSigSendType" SG_ 2331595785 NR_FR_Object_01_ID 0;
BA_ "GenSigStartValue" SG_ 2331595785 NR_FR_Object_01_ID 255;
BA_ "GenSigSendType" SG_ 2331595785 NR_FR_Object_01_Length 0;
BA_ "GenSigStartValue" SG_ 2331595785 NR_FR_Object_01_Length 1023;
BA_ "GenSigSendType" SG_ 2331595785 NR_FR_Object_01_LengthSD 0;
BA_ "GenSigStartValue" SG_ 2331595785 NR_FR_Object_01_LengthSD 127;
BA_ "GenSigSendType" SG_ 2331595785 NR_FR_Object_01_MeasurementState 0;
BA_ "GenSigSendType" SG_ 2331595785 NR_FR_Object_01_PosX 0;
BA_ "GenSigStartValue" SG_ 2331595785 NR_FR_Object_01_PosX 16383;
BA_ "GenSigSendType" SG_ 2331595785 NR_FR_Object_01_PosXSD 0;
BA_ "GenSigStartValue" SG_ 2331595785 NR_FR_Object_01_PosXSD 255;
BA_ "GenSigSendType" SG_ 2331595785 NR_FR_Object_01_PosY 0;
BA_ "GenSigStartValue" SG_ 2331595785 NR_FR_Object_01_PosY 8191;
BA_ "GenSigSendType" SG_ 2331595785 NR_FR_Object_01_PosYSD 0;
BA_ "GenSigStartValue" SG_ 2331595785 NR_FR_Object_01_PosYSD 255;
BA_ "GenSigSendType" SG_ 2331595785 NR_FR_Object_01_ReferencePoint 0;
BA_ "GenSigStartValue" SG_ 2331595785 NR_FR_Object_01_ReferencePoint 15;
BA_ "GenSigSendType" SG_ 2331595785 NR_FR_Object_01_vAbsX 0;
BA_ "GenSigStartValue" SG_ 2331595785 NR_FR_Object_01_vAbsX 4095;
BA_ "GenSigSendType" SG_ 2331595785 NR_FR_Object_01_vAbsXSD 0;
BA_ "GenSigStartValue" SG_ 2331595785 NR_FR_Object_01_vAbsXSD 63;
BA_ "GenSigSendType" SG_ 2331595785 NR_FR_Object_01_vAbsY 0;
BA_ "GenSigStartValue" SG_ 2331595785 NR_FR_Object_01_vAbsY 4095;
BA_ "GenSigSendType" SG_ 2331595785 NR_FR_Object_01_vAbsYSD 0;
BA_ "GenSigStartValue" SG_ 2331595785 NR_FR_Object_01_vAbsYSD 63;
BA_ "GenSigSendType" SG_ 2331595785 NR_FR_Object_01_Width 0;
BA_ "GenSigStartValue" SG_ 2331595785 NR_FR_Object_01_Width 255;
BA_ "GenSigSendType" SG_ 2331595785 NR_FR_Object_01_WidthSD 0;
BA_ "GenSigStartValue" SG_ 2331595785 NR_FR_Object_01_WidthSD 127;
BA_ "GenSigSendType" SG_ 2331595785 NR_FR_Object_01_YawAngle 0;
BA_ "GenSigStartValue" SG_ 2331595785 NR_FR_Object_01_YawAngle 4095;
BA_ "GenSigSendType" SG_ 2331595785 NR_FR_Object_01_YawAngleSD 0;
BA_ "GenSigStartValue" SG_ 2331595785 NR_FR_Object_01_YawAngleSD 511;
BA_ "GenSigSendType" SG_ 2331595785 NR_FR_Object_01_YawRateAbs 0;
BA_ "GenSigStartValue" SG_ 2331595785 NR_FR_Object_01_YawRateAbs 4095;
BA_ "GenSigSendType" SG_ 2331595785 NR_FR_Object_01_YawRateAbsSD 0;
BA_ "GenSigStartValue" SG_ 2331595785 NR_FR_Object_01_YawRateAbsSD 63;
BA_ "GenSigSendType" SG_ 2331595785 NR_FR_Object_02_aAbsX 0;
BA_ "GenSigStartValue" SG_ 2331595785 NR_FR_Object_02_aAbsX 511;
BA_ "GenSigSendType" SG_ 2331595785 NR_FR_Object_02_aAbsXSD 0;
BA_ "GenSigStartValue" SG_ 2331595785 NR_FR_Object_02_aAbsXSD 63;
BA_ "GenSigSendType" SG_ 2331595785 NR_FR_Object_02_aAbsY 0;
BA_ "GenSigStartValue" SG_ 2331595785 NR_FR_Object_02_aAbsY 511;
BA_ "GenSigSendType" SG_ 2331595785 NR_FR_Object_02_aAbsYSD 0;
BA_ "GenSigStartValue" SG_ 2331595785 NR_FR_Object_02_aAbsYSD 63;
BA_ "GenSigSendType" SG_ 2331595785 NR_FR_Object_02_Age 0;
BA_ "GenSigStartValue" SG_ 2331595785 NR_FR_Object_02_Age 127;
BA_ "GenSigSendType" SG_ 2331595785 NR_FR_Object_02_Class 0;
BA_ "GenSigStartValue" SG_ 2331595785 NR_FR_Object_02_Class 15;
BA_ "GenSigSendType" SG_ 2331595785 NR_FR_Object_02_ClassPlausib 0;
BA_ "GenSigStartValue" SG_ 2331595785 NR_FR_Object_02_ClassPlausib 15;
BA_ "GenSigSendType" SG_ 2331595785 NR_FR_Object_02_DynamicState 0;
BA_ "GenSigStartValue" SG_ 2331595785 NR_FR_Object_02_DynamicState 3;
BA_ "GenSigSendType" SG_ 2331595785 NR_FR_Object_02_ExistProb 0;
BA_ "GenSigStartValue" SG_ 2331595785 NR_FR_Object_02_ExistProb 127;
BA_ "GenSigSendType" SG_ 2331595785 NR_FR_Object_02_ID 0;
BA_ "GenSigStartValue" SG_ 2331595785 NR_FR_Object_02_ID 255;
BA_ "GenSigSendType" SG_ 2331595785 NR_FR_Object_02_Length 0;
BA_ "GenSigStartValue" SG_ 2331595785 NR_FR_Object_02_Length 1023;
BA_ "GenSigSendType" SG_ 2331595785 NR_FR_Object_02_LengthSD 0;
BA_ "GenSigStartValue" SG_ 2331595785 NR_FR_Object_02_LengthSD 127;
BA_ "GenSigSendType" SG_ 2331595785 NR_FR_Object_02_MeasurementState 0;
BA_ "GenSigSendType" SG_ 2331595785 NR_FR_Object_02_PosX 0;
BA_ "GenSigStartValue" SG_ 2331595785 NR_FR_Object_02_PosX 16383;
BA_ "GenSigSendType" SG_ 2331595785 NR_FR_Object_02_PosXSD 0;
BA_ "GenSigStartValue" SG_ 2331595785 NR_FR_Object_02_PosXSD 255;
BA_ "GenSigSendType" SG_ 2331595785 NR_FR_Object_02_PosY 0;
BA_ "GenSigStartValue" SG_ 2331595785 NR_FR_Object_02_PosY 8191;
BA_ "GenSigSendType" SG_ 2331595785 NR_FR_Object_02_PosYSD 0;
BA_ "GenSigStartValue" SG_ 2331595785 NR_FR_Object_02_PosYSD 255;
BA_ "GenSigSendType" SG_ 2331595785 NR_FR_Object_02_ReferencePoint 0;
BA_ "GenSigStartValue" SG_ 2331595785 NR_FR_Object_02_ReferencePoint 15;
BA_ "GenSigSendType" SG_ 2331595785 NR_FR_Object_02_vAbsX 0;
BA_ "GenSigStartValue" SG_ 2331595785 NR_FR_Object_02_vAbsX 4095;
BA_ "GenSigSendType" SG_ 2331595785 NR_FR_Object_02_vAbsXSD 0;
BA_ "GenSigStartValue" SG_ 2331595785 NR_FR_Object_02_vAbsXSD 63;
BA_ "GenSigSendType" SG_ 2331595785 NR_FR_Object_02_vAbsY 0;
BA_ "GenSigStartValue" SG_ 2331595785 NR_FR_Object_02_vAbsY 4095;
BA_ "GenSigSendType" SG_ 2331595785 NR_FR_Object_02_vAbsYSD 0;
BA_ "GenSigStartValue" SG_ 2331595785 NR_FR_Object_02_vAbsYSD 63;
BA_ "GenSigSendType" SG_ 2331595785 NR_FR_Object_02_Width 0;
BA_ "GenSigStartValue" SG_ 2331595785 NR_FR_Object_02_Width 255;
BA_ "GenSigSendType" SG_ 2331595785 NR_FR_Object_02_WidthSD 0;
BA_ "GenSigStartValue" SG_ 2331595785 NR_FR_Object_02_WidthSD 127;
BA_ "GenSigSendType" SG_ 2331595785 NR_FR_Object_02_YawAngle 0;
BA_ "GenSigStartValue" SG_ 2331595785 NR_FR_Object_02_YawAngle 4095;
BA_ "GenSigSendType" SG_ 2331595785 NR_FR_Object_02_YawAngleSD 0;
BA_ "GenSigStartValue" SG_ 2331595785 NR_FR_Object_02_YawAngleSD 511;
BA_ "GenSigSendType" SG_ 2331595785 NR_FR_Object_02_YawRateAbs 0;
BA_ "GenSigStartValue" SG_ 2331595785 NR_FR_Object_02_YawRateAbs 4095;
BA_ "GenSigSendType" SG_ 2331595785 NR_FR_Object_02_YawRateAbsSD 0;
BA_ "GenSigStartValue" SG_ 2331595785 NR_FR_Object_02_YawRateAbsSD 63;
BA_ "GenSigSendType" SG_ 2331595785 SOK_NR_FR_Object_01_02_Signatur 0;
BA_ "GenSigFuncType" SG_ 2331595785 SOK_NR_FR_Object_01_02_Signatur 15;
BA_ "GenSigSendType" SG_ 2331595786 NR_FR_Object_03_04_BlockID_02 0;
BA_ "GenSigSendType" SG_ 2331595786 NR_FR_Object_03_04_BZ 0;
BA_ "GenSigFuncType" SG_ 2331595786 NR_FR_Object_03_04_BZ 1;
BA_ "GenSigSwitchedByIgnition" SG_ 2331595786 NR_FR_Object_03_04_BZ 0;
BA_ "GenSigSendType" SG_ 2331595786 NR_FR_Object_03_04_CRC 0;
BA_ "GenSigFuncType" SG_ 2331595786 NR_FR_Object_03_04_CRC 2;
BA_ "GenSigSwitchedByIgnition" SG_ 2331595786 NR_FR_Object_03_04_CRC 0;
BA_ "GenSigSendType" SG_ 2331595786 NR_FR_Object_03_aAbsX 0;
BA_ "GenSigStartValue" SG_ 2331595786 NR_FR_Object_03_aAbsX 511;
BA_ "GenSigSendType" SG_ 2331595786 NR_FR_Object_03_aAbsXSD 0;
BA_ "GenSigStartValue" SG_ 2331595786 NR_FR_Object_03_aAbsXSD 63;
BA_ "GenSigSendType" SG_ 2331595786 NR_FR_Object_03_aAbsY 0;
BA_ "GenSigStartValue" SG_ 2331595786 NR_FR_Object_03_aAbsY 511;
BA_ "GenSigSendType" SG_ 2331595786 NR_FR_Object_03_aAbsYSD 0;
BA_ "GenSigStartValue" SG_ 2331595786 NR_FR_Object_03_aAbsYSD 63;
BA_ "GenSigSendType" SG_ 2331595786 NR_FR_Object_03_Age 0;
BA_ "GenSigStartValue" SG_ 2331595786 NR_FR_Object_03_Age 127;
BA_ "GenSigSendType" SG_ 2331595786 NR_FR_Object_03_Class 0;
BA_ "GenSigStartValue" SG_ 2331595786 NR_FR_Object_03_Class 15;
BA_ "GenSigSendType" SG_ 2331595786 NR_FR_Object_03_ClassPlausib 0;
BA_ "GenSigStartValue" SG_ 2331595786 NR_FR_Object_03_ClassPlausib 15;
BA_ "GenSigSendType" SG_ 2331595786 NR_FR_Object_03_DynamicState 0;
BA_ "GenSigStartValue" SG_ 2331595786 NR_FR_Object_03_DynamicState 3;
BA_ "GenSigSendType" SG_ 2331595786 NR_FR_Object_03_ExistProb 0;
BA_ "GenSigStartValue" SG_ 2331595786 NR_FR_Object_03_ExistProb 127;
BA_ "GenSigSendType" SG_ 2331595786 NR_FR_Object_03_ID 0;
BA_ "GenSigStartValue" SG_ 2331595786 NR_FR_Object_03_ID 255;
BA_ "GenSigSendType" SG_ 2331595786 NR_FR_Object_03_Length 0;
BA_ "GenSigStartValue" SG_ 2331595786 NR_FR_Object_03_Length 1023;
BA_ "GenSigSendType" SG_ 2331595786 NR_FR_Object_03_LengthSD 0;
BA_ "GenSigStartValue" SG_ 2331595786 NR_FR_Object_03_LengthSD 127;
BA_ "GenSigSendType" SG_ 2331595786 NR_FR_Object_03_MeasurementState 0;
BA_ "GenSigSendType" SG_ 2331595786 NR_FR_Object_03_PosX 0;
BA_ "GenSigStartValue" SG_ 2331595786 NR_FR_Object_03_PosX 16383;
BA_ "GenSigSendType" SG_ 2331595786 NR_FR_Object_03_PosXSD 0;
BA_ "GenSigStartValue" SG_ 2331595786 NR_FR_Object_03_PosXSD 255;
BA_ "GenSigSendType" SG_ 2331595786 NR_FR_Object_03_PosY 0;
BA_ "GenSigStartValue" SG_ 2331595786 NR_FR_Object_03_PosY 8191;
BA_ "GenSigSendType" SG_ 2331595786 NR_FR_Object_03_PosYSD 0;
BA_ "GenSigStartValue" SG_ 2331595786 NR_FR_Object_03_PosYSD 255;
BA_ "GenSigSendType" SG_ 2331595786 NR_FR_Object_03_ReferencePoint 0;
BA_ "GenSigStartValue" SG_ 2331595786 NR_FR_Object_03_ReferencePoint 15;
BA_ "GenSigSendType" SG_ 2331595786 NR_FR_Object_03_vAbsX 0;
BA_ "GenSigStartValue" SG_ 2331595786 NR_FR_Object_03_vAbsX 4095;
BA_ "GenSigSendType" SG_ 2331595786 NR_FR_Object_03_vAbsXSD 0;
BA_ "GenSigStartValue" SG_ 2331595786 NR_FR_Object_03_vAbsXSD 63;
BA_ "GenSigSendType" SG_ 2331595786 NR_FR_Object_03_vAbsY 0;
BA_ "GenSigStartValue" SG_ 2331595786 NR_FR_Object_03_vAbsY 4095;
BA_ "GenSigSendType" SG_ 2331595786 NR_FR_Object_03_vAbsYSD 0;
BA_ "GenSigStartValue" SG_ 2331595786 NR_FR_Object_03_vAbsYSD 63;
BA_ "GenSigSendType" SG_ 2331595786 NR_FR_Object_03_Width 0;
BA_ "GenSigStartValue" SG_ 2331595786 NR_FR_Object_03_Width 255;
BA_ "GenSigSendType" SG_ 2331595786 NR_FR_Object_03_WidthSD 0;
BA_ "GenSigStartValue" SG_ 2331595786 NR_FR_Object_03_WidthSD 127;
BA_ "GenSigSendType" SG_ 2331595786 NR_FR_Object_03_YawAngle 0;
BA_ "GenSigStartValue" SG_ 2331595786 NR_FR_Object_03_YawAngle 4095;
BA_ "GenSigSendType" SG_ 2331595786 NR_FR_Object_03_YawAngleSD 0;
BA_ "GenSigStartValue" SG_ 2331595786 NR_FR_Object_03_YawAngleSD 511;
BA_ "GenSigSendType" SG_ 2331595786 NR_FR_Object_03_YawRateAbs 0;
BA_ "GenSigStartValue" SG_ 2331595786 NR_FR_Object_03_YawRateAbs 4095;
BA_ "GenSigSendType" SG_ 2331595786 NR_FR_Object_03_YawRateAbsSD 0;
BA_ "GenSigStartValue" SG_ 2331595786 NR_FR_Object_03_YawRateAbsSD 63;
BA_ "GenSigSendType" SG_ 2331595786 NR_FR_Object_04_aAbsX 0;
BA_ "GenSigStartValue" SG_ 2331595786 NR_FR_Object_04_aAbsX 511;
BA_ "GenSigSendType" SG_ 2331595786 NR_FR_Object_04_aAbsXSD 0;
BA_ "GenSigStartValue" SG_ 2331595786 NR_FR_Object_04_aAbsXSD 63;
BA_ "GenSigSendType" SG_ 2331595786 NR_FR_Object_04_aAbsY 0;
BA_ "GenSigStartValue" SG_ 2331595786 NR_FR_Object_04_aAbsY 511;
BA_ "GenSigSendType" SG_ 2331595786 NR_FR_Object_04_aAbsYSD 0;
BA_ "GenSigStartValue" SG_ 2331595786 NR_FR_Object_04_aAbsYSD 63;
BA_ "GenSigSendType" SG_ 2331595786 NR_FR_Object_04_Age 0;
BA_ "GenSigStartValue" SG_ 2331595786 NR_FR_Object_04_Age 127;
BA_ "GenSigSendType" SG_ 2331595786 NR_FR_Object_04_Class 0;
BA_ "GenSigStartValue" SG_ 2331595786 NR_FR_Object_04_Class 15;
BA_ "GenSigSendType" SG_ 2331595786 NR_FR_Object_04_ClassPlausib 0;
BA_ "GenSigStartValue" SG_ 2331595786 NR_FR_Object_04_ClassPlausib 15;
BA_ "GenSigSendType" SG_ 2331595786 NR_FR_Object_04_DynamicState 0;
BA_ "GenSigStartValue" SG_ 2331595786 NR_FR_Object_04_DynamicState 3;
BA_ "GenSigSendType" SG_ 2331595786 NR_FR_Object_04_ExistProb 0;
BA_ "GenSigStartValue" SG_ 2331595786 NR_FR_Object_04_ExistProb 127;
BA_ "GenSigSendType" SG_ 2331595786 NR_FR_Object_04_ID 0;
BA_ "GenSigStartValue" SG_ 2331595786 NR_FR_Object_04_ID 255;
BA_ "GenSigSendType" SG_ 2331595786 NR_FR_Object_04_Length 0;
BA_ "GenSigStartValue" SG_ 2331595786 NR_FR_Object_04_Length 1023;
BA_ "GenSigSendType" SG_ 2331595786 NR_FR_Object_04_LengthSD 0;
BA_ "GenSigStartValue" SG_ 2331595786 NR_FR_Object_04_LengthSD 127;
BA_ "GenSigSendType" SG_ 2331595786 NR_FR_Object_04_MeasurementState 0;
BA_ "GenSigSendType" SG_ 2331595786 NR_FR_Object_04_PosX 0;
BA_ "GenSigStartValue" SG_ 2331595786 NR_FR_Object_04_PosX 16383;
BA_ "GenSigSendType" SG_ 2331595786 NR_FR_Object_04_PosXSD 0;
BA_ "GenSigStartValue" SG_ 2331595786 NR_FR_Object_04_PosXSD 255;
BA_ "GenSigSendType" SG_ 2331595786 NR_FR_Object_04_PosY 0;
BA_ "GenSigStartValue" SG_ 2331595786 NR_FR_Object_04_PosY 8191;
BA_ "GenSigSendType" SG_ 2331595786 NR_FR_Object_04_PosYSD 0;
BA_ "GenSigStartValue" SG_ 2331595786 NR_FR_Object_04_PosYSD 255;
BA_ "GenSigSendType" SG_ 2331595786 NR_FR_Object_04_ReferencePoint 0;
BA_ "GenSigStartValue" SG_ 2331595786 NR_FR_Object_04_ReferencePoint 15;
BA_ "GenSigSendType" SG_ 2331595786 NR_FR_Object_04_vAbsX 0;
BA_ "GenSigStartValue" SG_ 2331595786 NR_FR_Object_04_vAbsX 4095;
BA_ "GenSigSendType" SG_ 2331595786 NR_FR_Object_04_vAbsXSD 0;
BA_ "GenSigStartValue" SG_ 2331595786 NR_FR_Object_04_vAbsXSD 63;
BA_ "GenSigSendType" SG_ 2331595786 NR_FR_Object_04_vAbsY 0;
BA_ "GenSigStartValue" SG_ 2331595786 NR_FR_Object_04_vAbsY 4095;
BA_ "GenSigSendType" SG_ 2331595786 NR_FR_Object_04_vAbsYSD 0;
BA_ "GenSigStartValue" SG_ 2331595786 NR_FR_Object_04_vAbsYSD 63;
BA_ "GenSigSendType" SG_ 2331595786 NR_FR_Object_04_Width 0;
BA_ "GenSigStartValue" SG_ 2331595786 NR_FR_Object_04_Width 255;
BA_ "GenSigSendType" SG_ 2331595786 NR_FR_Object_04_WidthSD 0;
BA_ "GenSigStartValue" SG_ 2331595786 NR_FR_Object_04_WidthSD 127;
BA_ "GenSigSendType" SG_ 2331595786 NR_FR_Object_04_YawAngle 0;
BA_ "GenSigStartValue" SG_ 2331595786 NR_FR_Object_04_YawAngle 4095;
BA_ "GenSigSendType" SG_ 2331595786 NR_FR_Object_04_YawAngleSD 0;
BA_ "GenSigStartValue" SG_ 2331595786 NR_FR_Object_04_YawAngleSD 511;
BA_ "GenSigSendType" SG_ 2331595786 NR_FR_Object_04_YawRateAbs 0;
BA_ "GenSigStartValue" SG_ 2331595786 NR_FR_Object_04_YawRateAbs 4095;
BA_ "GenSigSendType" SG_ 2331595786 NR_FR_Object_04_YawRateAbsSD 0;
BA_ "GenSigStartValue" SG_ 2331595786 NR_FR_Object_04_YawRateAbsSD 63;
BA_ "GenSigSendType" SG_ 2331595786 SOK_NR_FR_Object_03_04_Signatur 0;
BA_ "GenSigFuncType" SG_ 2331595786 SOK_NR_FR_Object_03_04_Signatur 15;
BA_ "GenSigSendType" SG_ 2331595787 NR_FR_Object_05_06_BlockID_02 0;
BA_ "GenSigSendType" SG_ 2331595787 NR_FR_Object_05_06_BZ 0;
BA_ "GenSigFuncType" SG_ 2331595787 NR_FR_Object_05_06_BZ 1;
BA_ "GenSigSwitchedByIgnition" SG_ 2331595787 NR_FR_Object_05_06_BZ 0;
BA_ "GenSigSendType" SG_ 2331595787 NR_FR_Object_05_06_CRC 0;
BA_ "GenSigFuncType" SG_ 2331595787 NR_FR_Object_05_06_CRC 2;
BA_ "GenSigSwitchedByIgnition" SG_ 2331595787 NR_FR_Object_05_06_CRC 0;
BA_ "GenSigSendType" SG_ 2331595787 NR_FR_Object_05_aAbsX 0;
BA_ "GenSigStartValue" SG_ 2331595787 NR_FR_Object_05_aAbsX 511;
BA_ "GenSigSendType" SG_ 2331595787 NR_FR_Object_05_aAbsXSD 0;
BA_ "GenSigStartValue" SG_ 2331595787 NR_FR_Object_05_aAbsXSD 63;
BA_ "GenSigSendType" SG_ 2331595787 NR_FR_Object_05_aAbsY 0;
BA_ "GenSigStartValue" SG_ 2331595787 NR_FR_Object_05_aAbsY 511;
BA_ "GenSigSendType" SG_ 2331595787 NR_FR_Object_05_aAbsYSD 0;
BA_ "GenSigStartValue" SG_ 2331595787 NR_FR_Object_05_aAbsYSD 63;
BA_ "GenSigSendType" SG_ 2331595787 NR_FR_Object_05_Age 0;
BA_ "GenSigStartValue" SG_ 2331595787 NR_FR_Object_05_Age 127;
BA_ "GenSigSendType" SG_ 2331595787 NR_FR_Object_05_Class 0;
BA_ "GenSigStartValue" SG_ 2331595787 NR_FR_Object_05_Class 15;
BA_ "GenSigSendType" SG_ 2331595787 NR_FR_Object_05_ClassPlausib 0;
BA_ "GenSigStartValue" SG_ 2331595787 NR_FR_Object_05_ClassPlausib 15;
BA_ "GenSigSendType" SG_ 2331595787 NR_FR_Object_05_DynamicState 0;
BA_ "GenSigStartValue" SG_ 2331595787 NR_FR_Object_05_DynamicState 3;
BA_ "GenSigSendType" SG_ 2331595787 NR_FR_Object_05_ExistProb 0;
BA_ "GenSigStartValue" SG_ 2331595787 NR_FR_Object_05_ExistProb 127;
BA_ "GenSigSendType" SG_ 2331595787 NR_FR_Object_05_ID 0;
BA_ "GenSigStartValue" SG_ 2331595787 NR_FR_Object_05_ID 255;
BA_ "GenSigSendType" SG_ 2331595787 NR_FR_Object_05_Length 0;
BA_ "GenSigStartValue" SG_ 2331595787 NR_FR_Object_05_Length 1023;
BA_ "GenSigSendType" SG_ 2331595787 NR_FR_Object_05_LengthSD 0;
BA_ "GenSigStartValue" SG_ 2331595787 NR_FR_Object_05_LengthSD 127;
BA_ "GenSigSendType" SG_ 2331595787 NR_FR_Object_05_MeasurementState 0;
BA_ "GenSigSendType" SG_ 2331595787 NR_FR_Object_05_PosX 0;
BA_ "GenSigStartValue" SG_ 2331595787 NR_FR_Object_05_PosX 16383;
BA_ "GenSigSendType" SG_ 2331595787 NR_FR_Object_05_PosXSD 0;
BA_ "GenSigStartValue" SG_ 2331595787 NR_FR_Object_05_PosXSD 255;
BA_ "GenSigSendType" SG_ 2331595787 NR_FR_Object_05_PosY 0;
BA_ "GenSigStartValue" SG_ 2331595787 NR_FR_Object_05_PosY 8191;
BA_ "GenSigSendType" SG_ 2331595787 NR_FR_Object_05_PosYSD 0;
BA_ "GenSigStartValue" SG_ 2331595787 NR_FR_Object_05_PosYSD 255;
BA_ "GenSigSendType" SG_ 2331595787 NR_FR_Object_05_ReferencePoint 0;
BA_ "GenSigStartValue" SG_ 2331595787 NR_FR_Object_05_ReferencePoint 15;
BA_ "GenSigSendType" SG_ 2331595787 NR_FR_Object_05_vAbsX 0;
BA_ "GenSigStartValue" SG_ 2331595787 NR_FR_Object_05_vAbsX 4095;
BA_ "GenSigSendType" SG_ 2331595787 NR_FR_Object_05_vAbsXSD 0;
BA_ "GenSigStartValue" SG_ 2331595787 NR_FR_Object_05_vAbsXSD 63;
BA_ "GenSigSendType" SG_ 2331595787 NR_FR_Object_05_vAbsY 0;
BA_ "GenSigStartValue" SG_ 2331595787 NR_FR_Object_05_vAbsY 4095;
BA_ "GenSigSendType" SG_ 2331595787 NR_FR_Object_05_vAbsYSD 0;
BA_ "GenSigStartValue" SG_ 2331595787 NR_FR_Object_05_vAbsYSD 63;
BA_ "GenSigSendType" SG_ 2331595787 NR_FR_Object_05_Width 0;
BA_ "GenSigStartValue" SG_ 2331595787 NR_FR_Object_05_Width 255;
BA_ "GenSigSendType" SG_ 2331595787 NR_FR_Object_05_WidthSD 0;
BA_ "GenSigStartValue" SG_ 2331595787 NR_FR_Object_05_WidthSD 127;
BA_ "GenSigSendType" SG_ 2331595787 NR_FR_Object_05_YawAngle 0;
BA_ "GenSigStartValue" SG_ 2331595787 NR_FR_Object_05_YawAngle 4095;
BA_ "GenSigSendType" SG_ 2331595787 NR_FR_Object_05_YawAngleSD 0;
BA_ "GenSigStartValue" SG_ 2331595787 NR_FR_Object_05_YawAngleSD 511;
BA_ "GenSigSendType" SG_ 2331595787 NR_FR_Object_05_YawRateAbs 0;
BA_ "GenSigStartValue" SG_ 2331595787 NR_FR_Object_05_YawRateAbs 4095;
BA_ "GenSigSendType" SG_ 2331595787 NR_FR_Object_05_YawRateAbsSD 0;
BA_ "GenSigStartValue" SG_ 2331595787 NR_FR_Object_05_YawRateAbsSD 63;
BA_ "GenSigSendType" SG_ 2331595787 NR_FR_Object_06_aAbsX 0;
BA_ "GenSigStartValue" SG_ 2331595787 NR_FR_Object_06_aAbsX 511;
BA_ "GenSigSendType" SG_ 2331595787 NR_FR_Object_06_aAbsXSD 0;
BA_ "GenSigStartValue" SG_ 2331595787 NR_FR_Object_06_aAbsXSD 63;
BA_ "GenSigSendType" SG_ 2331595787 NR_FR_Object_06_aAbsY 0;
BA_ "GenSigStartValue" SG_ 2331595787 NR_FR_Object_06_aAbsY 511;
BA_ "GenSigSendType" SG_ 2331595787 NR_FR_Object_06_aAbsYSD 0;
BA_ "GenSigStartValue" SG_ 2331595787 NR_FR_Object_06_aAbsYSD 63;
BA_ "GenSigSendType" SG_ 2331595787 NR_FR_Object_06_Age 0;
BA_ "GenSigStartValue" SG_ 2331595787 NR_FR_Object_06_Age 127;
BA_ "GenSigSendType" SG_ 2331595787 NR_FR_Object_06_Class 0;
BA_ "GenSigStartValue" SG_ 2331595787 NR_FR_Object_06_Class 15;
BA_ "GenSigSendType" SG_ 2331595787 NR_FR_Object_06_ClassPlausib 0;
BA_ "GenSigStartValue" SG_ 2331595787 NR_FR_Object_06_ClassPlausib 15;
BA_ "GenSigSendType" SG_ 2331595787 NR_FR_Object_06_DynamicState 0;
BA_ "GenSigStartValue" SG_ 2331595787 NR_FR_Object_06_DynamicState 3;
BA_ "GenSigSendType" SG_ 2331595787 NR_FR_Object_06_ExistProb 0;
BA_ "GenSigStartValue" SG_ 2331595787 NR_FR_Object_06_ExistProb 127;
BA_ "GenSigSendType" SG_ 2331595787 NR_FR_Object_06_ID 0;
BA_ "GenSigStartValue" SG_ 2331595787 NR_FR_Object_06_ID 255;
BA_ "GenSigSendType" SG_ 2331595787 NR_FR_Object_06_Length 0;
BA_ "GenSigStartValue" SG_ 2331595787 NR_FR_Object_06_Length 1023;
BA_ "GenSigSendType" SG_ 2331595787 NR_FR_Object_06_LengthSD 0;
BA_ "GenSigStartValue" SG_ 2331595787 NR_FR_Object_06_LengthSD 127;
BA_ "GenSigSendType" SG_ 2331595787 NR_FR_Object_06_MeasurementState 0;
BA_ "GenSigSendType" SG_ 2331595787 NR_FR_Object_06_PosX 0;
BA_ "GenSigStartValue" SG_ 2331595787 NR_FR_Object_06_PosX 16383;
BA_ "GenSigSendType" SG_ 2331595787 NR_FR_Object_06_PosXSD 0;
BA_ "GenSigStartValue" SG_ 2331595787 NR_FR_Object_06_PosXSD 255;
BA_ "GenSigSendType" SG_ 2331595787 NR_FR_Object_06_PosY 0;
BA_ "GenSigStartValue" SG_ 2331595787 NR_FR_Object_06_PosY 8191;
BA_ "GenSigSendType" SG_ 2331595787 NR_FR_Object_06_PosYSD 0;
BA_ "GenSigStartValue" SG_ 2331595787 NR_FR_Object_06_PosYSD 255;
BA_ "GenSigSendType" SG_ 2331595787 NR_FR_Object_06_ReferencePoint 0;
BA_ "GenSigStartValue" SG_ 2331595787 NR_FR_Object_06_ReferencePoint 15;
BA_ "GenSigSendType" SG_ 2331595787 NR_FR_Object_06_vAbsX 0;
BA_ "GenSigStartValue" SG_ 2331595787 NR_FR_Object_06_vAbsX 4095;
BA_ "GenSigSendType" SG_ 2331595787 NR_FR_Object_06_vAbsXSD 0;
BA_ "GenSigStartValue" SG_ 2331595787 NR_FR_Object_06_vAbsXSD 63;
BA_ "GenSigSendType" SG_ 2331595787 NR_FR_Object_06_vAbsY 0;
BA_ "GenSigStartValue" SG_ 2331595787 NR_FR_Object_06_vAbsY 4095;
BA_ "GenSigSendType" SG_ 2331595787 NR_FR_Object_06_vAbsYSD 0;
BA_ "GenSigStartValue" SG_ 2331595787 NR_FR_Object_06_vAbsYSD 63;
BA_ "GenSigSendType" SG_ 2331595787 NR_FR_Object_06_Width 0;
BA_ "GenSigStartValue" SG_ 2331595787 NR_FR_Object_06_Width 255;
BA_ "GenSigSendType" SG_ 2331595787 NR_FR_Object_06_WidthSD 0;
BA_ "GenSigStartValue" SG_ 2331595787 NR_FR_Object_06_WidthSD 127;
BA_ "GenSigSendType" SG_ 2331595787 NR_FR_Object_06_YawAngle 0;
BA_ "GenSigStartValue" SG_ 2331595787 NR_FR_Object_06_YawAngle 4095;
BA_ "GenSigSendType" SG_ 2331595787 NR_FR_Object_06_YawAngleSD 0;
BA_ "GenSigStartValue" SG_ 2331595787 NR_FR_Object_06_YawAngleSD 511;
BA_ "GenSigSendType" SG_ 2331595787 NR_FR_Object_06_YawRateAbs 0;
BA_ "GenSigStartValue" SG_ 2331595787 NR_FR_Object_06_YawRateAbs 4095;
BA_ "GenSigSendType" SG_ 2331595787 NR_FR_Object_06_YawRateAbsSD 0;
BA_ "GenSigStartValue" SG_ 2331595787 NR_FR_Object_06_YawRateAbsSD 63;
BA_ "GenSigSendType" SG_ 2331595787 SOK_NR_FR_Object_05_06_Signatur 0;
BA_ "GenSigFuncType" SG_ 2331595787 SOK_NR_FR_Object_05_06_Signatur 15;
BA_ "GenSigSendType" SG_ 2331595788 NR_FR_Object_07_08_BlockID_02 0;
BA_ "GenSigSendType" SG_ 2331595788 NR_FR_Object_07_08_BZ 0;
BA_ "GenSigFuncType" SG_ 2331595788 NR_FR_Object_07_08_BZ 1;
BA_ "GenSigSwitchedByIgnition" SG_ 2331595788 NR_FR_Object_07_08_BZ 0;
BA_ "GenSigSendType" SG_ 2331595788 NR_FR_Object_07_08_CRC 0;
BA_ "GenSigFuncType" SG_ 2331595788 NR_FR_Object_07_08_CRC 2;
BA_ "GenSigSwitchedByIgnition" SG_ 2331595788 NR_FR_Object_07_08_CRC 0;
BA_ "GenSigSendType" SG_ 2331595788 NR_FR_Object_07_aAbsX 0;
BA_ "GenSigStartValue" SG_ 2331595788 NR_FR_Object_07_aAbsX 511;
BA_ "GenSigSendType" SG_ 2331595788 NR_FR_Object_07_aAbsXSD 0;
BA_ "GenSigStartValue" SG_ 2331595788 NR_FR_Object_07_aAbsXSD 63;
BA_ "GenSigSendType" SG_ 2331595788 NR_FR_Object_07_aAbsY 0;
BA_ "GenSigStartValue" SG_ 2331595788 NR_FR_Object_07_aAbsY 511;
BA_ "GenSigSendType" SG_ 2331595788 NR_FR_Object_07_aAbsYSD 0;
BA_ "GenSigStartValue" SG_ 2331595788 NR_FR_Object_07_aAbsYSD 63;
BA_ "GenSigSendType" SG_ 2331595788 NR_FR_Object_07_Age 0;
BA_ "GenSigStartValue" SG_ 2331595788 NR_FR_Object_07_Age 127;
BA_ "GenSigSendType" SG_ 2331595788 NR_FR_Object_07_Class 0;
BA_ "GenSigStartValue" SG_ 2331595788 NR_FR_Object_07_Class 15;
BA_ "GenSigSendType" SG_ 2331595788 NR_FR_Object_07_ClassPlausib 0;
BA_ "GenSigStartValue" SG_ 2331595788 NR_FR_Object_07_ClassPlausib 15;
BA_ "GenSigSendType" SG_ 2331595788 NR_FR_Object_07_DynamicState 0;
BA_ "GenSigStartValue" SG_ 2331595788 NR_FR_Object_07_DynamicState 3;
BA_ "GenSigSendType" SG_ 2331595788 NR_FR_Object_07_ExistProb 0;
BA_ "GenSigStartValue" SG_ 2331595788 NR_FR_Object_07_ExistProb 127;
BA_ "GenSigSendType" SG_ 2331595788 NR_FR_Object_07_ID 0;
BA_ "GenSigStartValue" SG_ 2331595788 NR_FR_Object_07_ID 255;
BA_ "GenSigSendType" SG_ 2331595788 NR_FR_Object_07_Length 0;
BA_ "GenSigStartValue" SG_ 2331595788 NR_FR_Object_07_Length 1023;
BA_ "GenSigSendType" SG_ 2331595788 NR_FR_Object_07_LengthSD 0;
BA_ "GenSigStartValue" SG_ 2331595788 NR_FR_Object_07_LengthSD 127;
BA_ "GenSigSendType" SG_ 2331595788 NR_FR_Object_07_MeasurementState 0;
BA_ "GenSigSendType" SG_ 2331595788 NR_FR_Object_07_PosX 0;
BA_ "GenSigStartValue" SG_ 2331595788 NR_FR_Object_07_PosX 16383;
BA_ "GenSigSendType" SG_ 2331595788 NR_FR_Object_07_PosXSD 0;
BA_ "GenSigStartValue" SG_ 2331595788 NR_FR_Object_07_PosXSD 255;
BA_ "GenSigSendType" SG_ 2331595788 NR_FR_Object_07_PosY 0;
BA_ "GenSigStartValue" SG_ 2331595788 NR_FR_Object_07_PosY 8191;
BA_ "GenSigSendType" SG_ 2331595788 NR_FR_Object_07_PosYSD 0;
BA_ "GenSigStartValue" SG_ 2331595788 NR_FR_Object_07_PosYSD 255;
BA_ "GenSigSendType" SG_ 2331595788 NR_FR_Object_07_ReferencePoint 0;
BA_ "GenSigStartValue" SG_ 2331595788 NR_FR_Object_07_ReferencePoint 15;
BA_ "GenSigSendType" SG_ 2331595788 NR_FR_Object_07_vAbsX 0;
BA_ "GenSigStartValue" SG_ 2331595788 NR_FR_Object_07_vAbsX 4095;
BA_ "GenSigSendType" SG_ 2331595788 NR_FR_Object_07_vAbsXSD 0;
BA_ "GenSigStartValue" SG_ 2331595788 NR_FR_Object_07_vAbsXSD 63;
BA_ "GenSigSendType" SG_ 2331595788 NR_FR_Object_07_vAbsY 0;
BA_ "GenSigStartValue" SG_ 2331595788 NR_FR_Object_07_vAbsY 4095;
BA_ "GenSigSendType" SG_ 2331595788 NR_FR_Object_07_vAbsYSD 0;
BA_ "GenSigStartValue" SG_ 2331595788 NR_FR_Object_07_vAbsYSD 63;
BA_ "GenSigSendType" SG_ 2331595788 NR_FR_Object_07_Width 0;
BA_ "GenSigStartValue" SG_ 2331595788 NR_FR_Object_07_Width 255;
BA_ "GenSigSendType" SG_ 2331595788 NR_FR_Object_07_WidthSD 0;
BA_ "GenSigStartValue" SG_ 2331595788 NR_FR_Object_07_WidthSD 127;
BA_ "GenSigSendType" SG_ 2331595788 NR_FR_Object_07_YawAngle 0;
BA_ "GenSigStartValue" SG_ 2331595788 NR_FR_Object_07_YawAngle 4095;
BA_ "GenSigSendType" SG_ 2331595788 NR_FR_Object_07_YawAngleSD 0;
BA_ "GenSigStartValue" SG_ 2331595788 NR_FR_Object_07_YawAngleSD 511;
BA_ "GenSigSendType" SG_ 2331595788 NR_FR_Object_07_YawRateAbs 0;
BA_ "GenSigStartValue" SG_ 2331595788 NR_FR_Object_07_YawRateAbs 4095;
BA_ "GenSigSendType" SG_ 2331595788 NR_FR_Object_07_YawRateAbsSD 0;
BA_ "GenSigStartValue" SG_ 2331595788 NR_FR_Object_07_YawRateAbsSD 63;
BA_ "GenSigSendType" SG_ 2331595788 NR_FR_Object_08_aAbsX 0;
BA_ "GenSigStartValue" SG_ 2331595788 NR_FR_Object_08_aAbsX 511;
BA_ "GenSigSendType" SG_ 2331595788 NR_FR_Object_08_aAbsXSD 0;
BA_ "GenSigStartValue" SG_ 2331595788 NR_FR_Object_08_aAbsXSD 63;
BA_ "GenSigSendType" SG_ 2331595788 NR_FR_Object_08_aAbsY 0;
BA_ "GenSigStartValue" SG_ 2331595788 NR_FR_Object_08_aAbsY 511;
BA_ "GenSigSendType" SG_ 2331595788 NR_FR_Object_08_aAbsYSD 0;
BA_ "GenSigStartValue" SG_ 2331595788 NR_FR_Object_08_aAbsYSD 63;
BA_ "GenSigSendType" SG_ 2331595788 NR_FR_Object_08_Age 0;
BA_ "GenSigStartValue" SG_ 2331595788 NR_FR_Object_08_Age 127;
BA_ "GenSigSendType" SG_ 2331595788 NR_FR_Object_08_Class 0;
BA_ "GenSigStartValue" SG_ 2331595788 NR_FR_Object_08_Class 15;
BA_ "GenSigSendType" SG_ 2331595788 NR_FR_Object_08_ClassPlausib 0;
BA_ "GenSigStartValue" SG_ 2331595788 NR_FR_Object_08_ClassPlausib 15;
BA_ "GenSigSendType" SG_ 2331595788 NR_FR_Object_08_DynamicState 0;
BA_ "GenSigStartValue" SG_ 2331595788 NR_FR_Object_08_DynamicState 3;
BA_ "GenSigSendType" SG_ 2331595788 NR_FR_Object_08_ExistProb 0;
BA_ "GenSigStartValue" SG_ 2331595788 NR_FR_Object_08_ExistProb 127;
BA_ "GenSigSendType" SG_ 2331595788 NR_FR_Object_08_ID 0;
BA_ "GenSigStartValue" SG_ 2331595788 NR_FR_Object_08_ID 255;
BA_ "GenSigSendType" SG_ 2331595788 NR_FR_Object_08_Length 0;
BA_ "GenSigStartValue" SG_ 2331595788 NR_FR_Object_08_Length 1023;
BA_ "GenSigSendType" SG_ 2331595788 NR_FR_Object_08_LengthSD 0;
BA_ "GenSigStartValue" SG_ 2331595788 NR_FR_Object_08_LengthSD 127;
BA_ "GenSigSendType" SG_ 2331595788 NR_FR_Object_08_MeasurementState 0;
BA_ "GenSigSendType" SG_ 2331595788 NR_FR_Object_08_PosX 0;
BA_ "GenSigStartValue" SG_ 2331595788 NR_FR_Object_08_PosX 16383;
BA_ "GenSigSendType" SG_ 2331595788 NR_FR_Object_08_PosXSD 0;
BA_ "GenSigStartValue" SG_ 2331595788 NR_FR_Object_08_PosXSD 255;
BA_ "GenSigSendType" SG_ 2331595788 NR_FR_Object_08_PosY 0;
BA_ "GenSigStartValue" SG_ 2331595788 NR_FR_Object_08_PosY 8191;
BA_ "GenSigSendType" SG_ 2331595788 NR_FR_Object_08_PosYSD 0;
BA_ "GenSigStartValue" SG_ 2331595788 NR_FR_Object_08_PosYSD 255;
BA_ "GenSigSendType" SG_ 2331595788 NR_FR_Object_08_ReferencePoint 0;
BA_ "GenSigStartValue" SG_ 2331595788 NR_FR_Object_08_ReferencePoint 15;
BA_ "GenSigSendType" SG_ 2331595788 NR_FR_Object_08_vAbsX 0;
BA_ "GenSigStartValue" SG_ 2331595788 NR_FR_Object_08_vAbsX 4095;
BA_ "GenSigSendType" SG_ 2331595788 NR_FR_Object_08_vAbsXSD 0;
BA_ "GenSigStartValue" SG_ 2331595788 NR_FR_Object_08_vAbsXSD 63;
BA_ "GenSigSendType" SG_ 2331595788 NR_FR_Object_08_vAbsY 0;
BA_ "GenSigStartValue" SG_ 2331595788 NR_FR_Object_08_vAbsY 4095;
BA_ "GenSigSendType" SG_ 2331595788 NR_FR_Object_08_vAbsYSD 0;
BA_ "GenSigStartValue" SG_ 2331595788 NR_FR_Object_08_vAbsYSD 63;
BA_ "GenSigSendType" SG_ 2331595788 NR_FR_Object_08_Width 0;
BA_ "GenSigStartValue" SG_ 2331595788 NR_FR_Object_08_Width 255;
BA_ "GenSigSendType" SG_ 2331595788 NR_FR_Object_08_WidthSD 0;
BA_ "GenSigStartValue" SG_ 2331595788 NR_FR_Object_08_WidthSD 127;
BA_ "GenSigSendType" SG_ 2331595788 NR_FR_Object_08_YawAngle 0;
BA_ "GenSigStartValue" SG_ 2331595788 NR_FR_Object_08_YawAngle 4095;
BA_ "GenSigSendType" SG_ 2331595788 NR_FR_Object_08_YawAngleSD 0;
BA_ "GenSigStartValue" SG_ 2331595788 NR_FR_Object_08_YawAngleSD 511;
BA_ "GenSigSendType" SG_ 2331595788 NR_FR_Object_08_YawRateAbs 0;
BA_ "GenSigStartValue" SG_ 2331595788 NR_FR_Object_08_YawRateAbs 4095;
BA_ "GenSigSendType" SG_ 2331595788 NR_FR_Object_08_YawRateAbsSD 0;
BA_ "GenSigStartValue" SG_ 2331595788 NR_FR_Object_08_YawRateAbsSD 63;
BA_ "GenSigSendType" SG_ 2331595788 SOK_NR_FR_Object_07_08_Signatur 0;
BA_ "GenSigFuncType" SG_ 2331595788 SOK_NR_FR_Object_07_08_Signatur 15;
BA_REL_ "GenSigTimeoutTime" BU_SG_REL_ MRR2023 SG_ 2331595780 NR_FL_Object_09_10_CRC 500;
BA_REL_ "GenSigTimeoutTime" BU_SG_REL_ MRR2023 SG_ 2331595780 NR_FL_Object_09_10_BZ 500;
BA_REL_ "GenSigTimeoutTime" BU_SG_REL_ MRR2023 SG_ 2331595780 NR_FL_Object_09_10_BlockID_01 500;
BA_REL_ "GenSigTimeoutTime" BU_SG_REL_ MRR2023 SG_ 2331595780 NR_FL_Object_09_ID 500;
BA_REL_ "GenSigTimeoutTime" BU_SG_REL_ MRR2023 SG_ 2331595780 NR_FL_Object_09_ReferencePoint 500;
BA_REL_ "GenSigTimeoutTime" BU_SG_REL_ MRR2023 SG_ 2331595780 NR_FL_Object_09_PosX 500;
BA_REL_ "GenSigTimeoutTime" BU_SG_REL_ MRR2023 SG_ 2331595780 NR_FL_Object_09_PosXSD 500;
BA_REL_ "GenSigTimeoutTime" BU_SG_REL_ MRR2023 SG_ 2331595780 NR_FL_Object_09_PosY 500;
BA_REL_ "GenSigTimeoutTime" BU_SG_REL_ MRR2023 SG_ 2331595780 NR_FL_Object_09_PosYSD 500;
BA_REL_ "GenSigTimeoutTime" BU_SG_REL_ MRR2023 SG_ 2331595780 NR_FL_Object_09_vAbsX 500;
BA_REL_ "GenSigTimeoutTime" BU_SG_REL_ MRR2023 SG_ 2331595780 NR_FL_Object_09_vAbsXSD 500;
BA_REL_ "GenSigTimeoutTime" BU_SG_REL_ MRR2023 SG_ 2331595780 NR_FL_Object_09_vAbsY 500;
BA_REL_ "GenSigTimeoutTime" BU_SG_REL_ MRR2023 SG_ 2331595780 NR_FL_Object_09_vAbsYSD 500;
BA_REL_ "GenSigTimeoutTime" BU_SG_REL_ MRR2023 SG_ 2331595780 NR_FL_Object_09_aAbsX 500;
BA_REL_ "GenSigTimeoutTime" BU_SG_REL_ MRR2023 SG_ 2331595780 NR_FL_Object_09_aAbsXSD 500;
BA_REL_ "GenSigTimeoutTime" BU_SG_REL_ MRR2023 SG_ 2331595780 NR_FL_Object_09_aAbsY 500;
BA_REL_ "GenSigTimeoutTime" BU_SG_REL_ MRR2023 SG_ 2331595780 NR_FL_Object_09_aAbsYSD 500;
BA_REL_ "GenSigTimeoutTime" BU_SG_REL_ MRR2023 SG_ 2331595780 NR_FL_Object_09_DynamicState 500;
BA_REL_ "GenSigTimeoutTime" BU_SG_REL_ MRR2023 SG_ 2331595780 NR_FL_Object_09_YawAngle 500;
BA_REL_ "GenSigTimeoutTime" BU_SG_REL_ MRR2023 SG_ 2331595780 NR_FL_Object_09_YawAngleSD 500;
BA_REL_ "GenSigTimeoutTime" BU_SG_REL_ MRR2023 SG_ 2331595780 NR_FL_Object_09_Width 500;
BA_REL_ "GenSigTimeoutTime" BU_SG_REL_ MRR2023 SG_ 2331595780 NR_FL_Object_09_WidthSD 500;
BA_REL_ "GenSigTimeoutTime" BU_SG_REL_ MRR2023 SG_ 2331595780 NR_FL_Object_09_Length 500;
BA_REL_ "GenSigTimeoutTime" BU_SG_REL_ MRR2023 SG_ 2331595780 NR_FL_Object_09_LengthSD 500;
BA_REL_ "GenSigTimeoutTime" BU_SG_REL_ MRR2023 SG_ 2331595780 NR_FL_Object_09_Class 500;
BA_REL_ "GenSigTimeoutTime" BU_SG_REL_ MRR2023 SG_ 2331595780 NR_FL_Object_09_ClassPlausib 500;
BA_REL_ "GenSigTimeoutTime" BU_SG_REL_ MRR2023 SG_ 2331595780 NR_FL_Object_09_ExistProb 500;
BA_REL_ "GenSigTimeoutTime" BU_SG_REL_ MRR2023 SG_ 2331595780 NR_FL_Object_09_Age 500;
BA_REL_ "GenSigTimeoutTime" BU_SG_REL_ MRR2023 SG_ 2331595780 NR_FL_Object_09_YawRateAbs 500;
BA_REL_ "GenSigTimeoutTime" BU_SG_REL_ MRR2023 SG_ 2331595780 NR_FL_Object_09_YawRateAbsSD 500;
BA_REL_ "GenSigTimeoutTime" BU_SG_REL_ MRR2023 SG_ 2331595780 NR_FL_Object_09_MeasurementState 500;
BA_REL_ "GenSigTimeoutTime" BU_SG_REL_ MRR2023 SG_ 2331595780 NR_FL_Object_10_ID 500;
BA_REL_ "GenSigTimeoutTime" BU_SG_REL_ MRR2023 SG_ 2331595780 NR_FL_Object_10_ReferencePoint 500;
BA_REL_ "GenSigTimeoutTime" BU_SG_REL_ MRR2023 SG_ 2331595780 NR_FL_Object_10_PosX 500;
BA_REL_ "GenSigTimeoutTime" BU_SG_REL_ MRR2023 SG_ 2331595780 NR_FL_Object_10_PosXSD 500;
BA_REL_ "GenSigTimeoutTime" BU_SG_REL_ MRR2023 SG_ 2331595780 NR_FL_Object_10_PosY 500;
BA_REL_ "GenSigTimeoutTime" BU_SG_REL_ MRR2023 SG_ 2331595780 NR_FL_Object_10_PosYSD 500;
BA_REL_ "GenSigTimeoutTime" BU_SG_REL_ MRR2023 SG_ 2331595780 NR_FL_Object_10_vAbsX 500;
BA_REL_ "GenSigTimeoutTime" BU_SG_REL_ MRR2023 SG_ 2331595780 NR_FL_Object_10_vAbsXSD 500;
BA_REL_ "GenSigTimeoutTime" BU_SG_REL_ MRR2023 SG_ 2331595780 NR_FL_Object_10_vAbsY 500;
BA_REL_ "GenSigTimeoutTime" BU_SG_REL_ MRR2023 SG_ 2331595780 NR_FL_Object_10_vAbsYSD 500;
BA_REL_ "GenSigTimeoutTime" BU_SG_REL_ MRR2023 SG_ 2331595780 NR_FL_Object_10_aAbsX 500;
BA_REL_ "GenSigTimeoutTime" BU_SG_REL_ MRR2023 SG_ 2331595780 NR_FL_Object_10_aAbsXSD 500;
BA_REL_ "GenSigTimeoutTime" BU_SG_REL_ MRR2023 SG_ 2331595780 NR_FL_Object_10_aAbsY 500;
BA_REL_ "GenSigTimeoutTime" BU_SG_REL_ MRR2023 SG_ 2331595780 NR_FL_Object_10_aAbsYSD 500;
BA_REL_ "GenSigTimeoutTime" BU_SG_REL_ MRR2023 SG_ 2331595780 NR_FL_Object_10_DynamicState 500;
BA_REL_ "GenSigTimeoutTime" BU_SG_REL_ MRR2023 SG_ 2331595780 NR_FL_Object_10_YawAngle 500;
BA_REL_ "GenSigTimeoutTime" BU_SG_REL_ MRR2023 SG_ 2331595780 NR_FL_Object_10_YawAngleSD 500;
BA_REL_ "GenSigTimeoutTime" BU_SG_REL_ MRR2023 SG_ 2331595780 NR_FL_Object_10_Width 500;
BA_REL_ "GenSigTimeoutTime" BU_SG_REL_ MRR2023 SG_ 2331595780 NR_FL_Object_10_WidthSD 500;
BA_REL_ "GenSigTimeoutTime" BU_SG_REL_ MRR2023 SG_ 2331595780 NR_FL_Object_10_Length 500;
BA_REL_ "GenSigTimeoutTime" BU_SG_REL_ MRR2023 SG_ 2331595780 NR_FL_Object_10_LengthSD 500;
BA_REL_ "GenSigTimeoutTime" BU_SG_REL_ MRR2023 SG_ 2331595780 NR_FL_Object_10_Class 500;
BA_REL_ "GenSigTimeoutTime" BU_SG_REL_ MRR2023 SG_ 2331595780 NR_FL_Object_10_ClassPlausib 500;
BA_REL_ "GenSigTimeoutTime" BU_SG_REL_ MRR2023 SG_ 2331595780 NR_FL_Object_10_ExistProb 500;
BA_REL_ "GenSigTimeoutTime" BU_SG_REL_ MRR2023 SG_ 2331595780 NR_FL_Object_10_Age 500;
BA_REL_ "GenSigTimeoutTime" BU_SG_REL_ MRR2023 SG_ 2331595780 NR_FL_Object_10_YawRateAbs 500;
BA_REL_ "GenSigTimeoutTime" BU_SG_REL_ MRR2023 SG_ 2331595780 NR_FL_Object_10_YawRateAbsSD 500;
BA_REL_ "GenSigTimeoutTime" BU_SG_REL_ MRR2023 SG_ 2331595780 NR_FL_Object_10_MeasurementState 500;
BA_REL_ "GenSigTimeoutTime" BU_SG_REL_ MRR2023 SG_ 2589284096 NR_FL_HW_Version 5000;
BA_REL_ "GenSigTimeoutTime" BU_SG_REL_ MRR2023 SG_ 2589284096 NR_FL_SW_Version 5000;
BA_REL_ "GenSigTimeoutTime" BU_SG_REL_ MRR2023 SG_ 2589284096 NR_FL_SerialNumber 5000;
BA_REL_ "GenSigTimeoutTime" BU_SG_REL_ MRR2023 SG_ 2331595852 NR_FL_Structure_BlockID_01 500;
BA_REL_ "GenSigTimeoutTime" BU_SG_REL_ MRR2023 SG_ 2331595852 NR_FL_Structure_left_LatDist 500;
BA_REL_ "GenSigTimeoutTime" BU_SG_REL_ MRR2023 SG_ 2331595852 NR_FL_Structure_left_Type 500;
BA_REL_ "GenSigTimeoutTime" BU_SG_REL_ MRR2023 SG_ 2331595852 NR_FL_Structure_left_ExistProb 500;
BA_REL_ "GenSigTimeoutTime" BU_SG_REL_ MRR2023 SG_ 2264486980 NR_FL_CounterValue 5000;
BA_REL_ "GenSigTimeoutTime" BU_SG_REL_ MRR2023 SG_ 2264486980 NR_FL_Time_LowPrecision 5000;
BA_REL_ "GenSigTimeoutTime" BU_SG_REL_ MRR2023 SG_ 2264486980 NR_FL_Time_HighPrecision 5000;
BA_REL_ "GenSigTimeoutTime" BU_SG_REL_ MRR2023 SG_ 2264486980 NR_FL_Time_CorrectionField 5000;
BA_REL_ "GenSigTimeoutTime" BU_SG_REL_ MRR2023 SG_ 2264486980 NR_FL_RandomSeed 5000;
BA_REL_ "GenSigTimeoutTime" BU_SG_REL_ MRR2023 SG_ 2264486976 NR_FL_SyncCounter 5000;
BA_REL_ "GenSigTimeoutTime" BU_SG_REL_ MRR2023 SG_ 2264486976 NR_FL_SyncVersion 5000;
BA_REL_ "GenSigTimeoutTime" BU_SG_REL_ MRR2023 SG_ 2264486985 NR_FL_SyncReadyVersion 500;
BA_REL_ "GenSigTimeoutTime" BU_SG_REL_ MRR2023 SG_ 2264486985 NR_FL_EarliestStartTime 500;
BA_REL_ "GenSigTimeoutTime" BU_SG_REL_ MRR2023 SG_ 2264486985 NR_FL_RequestedModulation 500;
BA_REL_ "GenSigTimeoutTime" BU_SG_REL_ MRR2023 SG_ 2264486985 NR_FL_InteferenceInfo 500;
BA_REL_ "GenSigTimeoutTime" BU_SG_REL_ MRR2023 SG_ 2264486985 NR_FL_SyncCycleCount 500;
BA_REL_ "GenSigTimeoutTime" BU_SG_REL_ MRR2023 SG_ 2264486985 NR_FL_LatestSyncCounter 500;
BA_REL_ "GenSigTimeoutTime" BU_SG_REL_ MRR2023 SG_ 2331595826 NR_FR_ShortTrackCal_State 500;
BA_REL_ "GenSigTimeoutTime" BU_SG_REL_ MRR2023 SG_ 2331595826 NR_FR_Cal_resp 500;
BA_REL_ "GenSigTimeoutTime" BU_SG_REL_ MRR2023 SG_ 2331595826 NR_FR_CalibrationMode 500;
BA_REL_ "GenSigTimeoutTime" BU_SG_REL_ MRR2023 SG_ 2331595826 NR_FR_resp_val 500;
BA_REL_ "GenSigTimeoutTime" BU_SG_REL_ MRR2023 SG_ 2331595826 NR_FR_QualFactorAutoCalib 500;
BA_REL_ "GenSigTimeoutTime" BU_SG_REL_ MRR2023 SG_ 2331595791 NR_FR_Contour_CRC 500;
BA_REL_ "GenSigTimeoutTime" BU_SG_REL_ MRR2023 SG_ 2331595791 NR_FR_Contour_BZ 500;
BA_REL_ "GenSigTimeoutTime" BU_SG_REL_ MRR2023 SG_ 2331595791 NR_FR_Contour_BlockID_02 500;
BA_REL_ "GenSigTimeoutTime" BU_SG_REL_ MRR2023 SG_ 2331595791 NR_FR_Contour_right_01_x01 500;
BA_REL_ "GenSigTimeoutTime" BU_SG_REL_ MRR2023 SG_ 2331595791 NR_FR_Contour_right_01_y01 500;
BA_REL_ "GenSigTimeoutTime" BU_SG_REL_ MRR2023 SG_ 2331595791 NR_FR_Contour_right_01_x02 500;
BA_REL_ "GenSigTimeoutTime" BU_SG_REL_ MRR2023 SG_ 2331595791 NR_FR_Contour_right_01_y02 500;
BA_REL_ "GenSigTimeoutTime" BU_SG_REL_ MRR2023 SG_ 2331595791 NR_FR_Contour_right_01_x03 500;
BA_REL_ "GenSigTimeoutTime" BU_SG_REL_ MRR2023 SG_ 2331595791 NR_FR_Contour_right_01_y03 500;
BA_REL_ "GenSigTimeoutTime" BU_SG_REL_ MRR2023 SG_ 2331595791 NR_FR_Contour_right_01_x04 500;
BA_REL_ "GenSigTimeoutTime" BU_SG_REL_ MRR2023 SG_ 2331595791 NR_FR_Contour_right_01_y04 500;
BA_REL_ "GenSigTimeoutTime" BU_SG_REL_ MRR2023 SG_ 2331595791 NR_FR_Contour_right_01_x05 500;
BA_REL_ "GenSigTimeoutTime" BU_SG_REL_ MRR2023 SG_ 2331595791 NR_FR_Contour_right_01_y05 500;
BA_REL_ "GenSigTimeoutTime" BU_SG_REL_ MRR2023 SG_ 2331595791 NR_FR_Contour_right_01_x06 500;
BA_REL_ "GenSigTimeoutTime" BU_SG_REL_ MRR2023 SG_ 2331595791 NR_FR_Contour_right_01_y06 500;
BA_REL_ "GenSigTimeoutTime" BU_SG_REL_ MRR2023 SG_ 2331595791 NR_FR_Contour_right_01_x07 500;
BA_REL_ "GenSigTimeoutTime" BU_SG_REL_ MRR2023 SG_ 2331595791 NR_FR_Contour_right_01_y07 500;
BA_REL_ "GenSigTimeoutTime" BU_SG_REL_ MRR2023 SG_ 2331595791 NR_FR_Contour_right_01_Type 500;
BA_REL_ "GenSigTimeoutTime" BU_SG_REL_ MRR2023 SG_ 2331595791 NR_FR_Contour_right_01_Age 500;
BA_REL_ "GenSigTimeoutTime" BU_SG_REL_ MRR2023 SG_ 2331595791 NR_FR_Contour_right_02_x01 500;
BA_REL_ "GenSigTimeoutTime" BU_SG_REL_ MRR2023 SG_ 2331595791 NR_FR_Contour_right_02_y01 500;
BA_REL_ "GenSigTimeoutTime" BU_SG_REL_ MRR2023 SG_ 2331595791 NR_FR_Contour_right_02_x02 500;
BA_REL_ "GenSigTimeoutTime" BU_SG_REL_ MRR2023 SG_ 2331595791 NR_FR_Contour_right_02_y02 500;
BA_REL_ "GenSigTimeoutTime" BU_SG_REL_ MRR2023 SG_ 2331595791 NR_FR_Contour_right_02_x03 500;
BA_REL_ "GenSigTimeoutTime" BU_SG_REL_ MRR2023 SG_ 2331595791 NR_FR_Contour_right_02_y03 500;
BA_REL_ "GenSigTimeoutTime" BU_SG_REL_ MRR2023 SG_ 2331595791 NR_FR_Contour_right_02_x04 500;
BA_REL_ "GenSigTimeoutTime" BU_SG_REL_ MRR2023 SG_ 2331595791 NR_FR_Contour_right_02_y04 500;
BA_REL_ "GenSigTimeoutTime" BU_SG_REL_ MRR2023 SG_ 2331595791 NR_FR_Contour_right_02_x05 500;
BA_REL_ "GenSigTimeoutTime" BU_SG_REL_ MRR2023 SG_ 2331595791 NR_FR_Contour_right_02_y05 500;
BA_REL_ "GenSigTimeoutTime" BU_SG_REL_ MRR2023 SG_ 2331595791 NR_FR_Contour_right_02_x06 500;
BA_REL_ "GenSigTimeoutTime" BU_SG_REL_ MRR2023 SG_ 2331595791 NR_FR_Contour_right_02_y06 500;
BA_REL_ "GenSigTimeoutTime" BU_SG_REL_ MRR2023 SG_ 2331595791 NR_FR_Contour_right_02_x07 500;
BA_REL_ "GenSigTimeoutTime" BU_SG_REL_ MRR2023 SG_ 2331595791 NR_FR_Contour_right_02_y07 500;
BA_REL_ "GenSigTimeoutTime" BU_SG_REL_ MRR2023 SG_ 2331595791 NR_FR_Contour_right_02_Type 500;
BA_REL_ "GenSigTimeoutTime" BU_SG_REL_ MRR2023 SG_ 2331595791 NR_FR_Contour_right_02_Age 500;
BA_REL_ "GenSigTimeoutTime" BU_SG_REL_ MRR2023 SG_ 2331595791 NR_FR_Contour_right_Linkage 500;
BA_REL_ "GenSigTimeoutTime" BU_SG_REL_ MRR2023 SG_ 2331595782 NR_FR_Header_CRC 500;
BA_REL_ "GenSigTimeoutTime" BU_SG_REL_ MRR2023 SG_ 2331595782 NR_FR_Header_BZ 500;
BA_REL_ "GenSigTimeoutTime" BU_SG_REL_ MRR2023 SG_ 2331595782 NR_FR_BlockID_02 500;
BA_REL_ "GenSigTimeoutTime" BU_SG_REL_ MRR2023 SG_ 2331595782 NR_FR_NotAvailable 500;
BA_REL_ "GenSigTimeoutTime" BU_SG_REL_ MRR2023 SG_ 2331595782 NR_FR_Failure 500;
BA_REL_ "GenSigTimeoutTime" BU_SG_REL_ MRR2023 SG_ 2331595782 NR_FR_Blindness 500;
BA_REL_ "GenSigTimeoutTime" BU_SG_REL_ MRR2023 SG_ 2331595782 NR_FR_CalibrationState 500;
BA_REL_ "GenSigTimeoutTime" BU_SG_REL_ MRR2023 SG_ 2331595782 NR_FR_Freesight_NOK 500;
BA_REL_ "GenSigTimeoutTime" BU_SG_REL_ MRR2023 SG_ 2331595782 NR_FR_MeasurementTimeLow 500;
BA_REL_ "GenSigTimeoutTime" BU_SG_REL_ MRR2023 SG_ 2331595782 NR_FR_MeasurementTimeHigh 500;
BA_REL_ "GenSigTimeoutTime" BU_SG_REL_ MRR2023 SG_ 2331595782 NR_FR_RangeDegradation_Sect1 500;
BA_REL_ "GenSigTimeoutTime" BU_SG_REL_ MRR2023 SG_ 2331595782 NR_FR_RangeDegradation_Sect2 500;
BA_REL_ "GenSigTimeoutTime" BU_SG_REL_ MRR2023 SG_ 2331595782 NR_FR_RangeDegradation_Sect3 500;
BA_REL_ "GenSigTimeoutTime" BU_SG_REL_ MRR2023 SG_ 2331595782 NR_FR_MeasurementTimeLapNumber 500;
BA_REL_ "GenSigTimeoutTime" BU_SG_REL_ MRR2023 SG_ 2331595782 NR_FR_MeasurementTimeStatus 500;
BA_REL_ "GenSigTimeoutTime" BU_SG_REL_ MRR2023 SG_ 2331595785 NR_FR_Object_01_02_CRC 500;
BA_REL_ "GenSigTimeoutTime" BU_SG_REL_ MRR2023 SG_ 2331595785 NR_FR_Object_01_02_BZ 500;
BA_REL_ "GenSigTimeoutTime" BU_SG_REL_ MRR2023 SG_ 2331595785 NR_FR_Object_01_02_BlockID_02 500;
BA_REL_ "GenSigTimeoutTime" BU_SG_REL_ MRR2023 SG_ 2331595785 NR_FR_Object_01_ID 500;
BA_REL_ "GenSigTimeoutTime" BU_SG_REL_ MRR2023 SG_ 2331595785 NR_FR_Object_01_ReferencePoint 500;
BA_REL_ "GenSigTimeoutTime" BU_SG_REL_ MRR2023 SG_ 2331595785 NR_FR_Object_01_PosX 500;
BA_REL_ "GenSigTimeoutTime" BU_SG_REL_ MRR2023 SG_ 2331595785 NR_FR_Object_01_PosXSD 500;
BA_REL_ "GenSigTimeoutTime" BU_SG_REL_ MRR2023 SG_ 2331595785 NR_FR_Object_01_PosY 500;
BA_REL_ "GenSigTimeoutTime" BU_SG_REL_ MRR2023 SG_ 2331595785 NR_FR_Object_01_PosYSD 500;
BA_REL_ "GenSigTimeoutTime" BU_SG_REL_ MRR2023 SG_ 2331595785 NR_FR_Object_01_vAbsX 500;
BA_REL_ "GenSigTimeoutTime" BU_SG_REL_ MRR2023 SG_ 2331595785 NR_FR_Object_01_vAbsXSD 500;
BA_REL_ "GenSigTimeoutTime" BU_SG_REL_ MRR2023 SG_ 2331595785 NR_FR_Object_01_vAbsY 500;
BA_REL_ "GenSigTimeoutTime" BU_SG_REL_ MRR2023 SG_ 2331595785 NR_FR_Object_01_vAbsYSD 500;
BA_REL_ "GenSigTimeoutTime" BU_SG_REL_ MRR2023 SG_ 2331595785 NR_FR_Object_01_aAbsX 500;
BA_REL_ "GenSigTimeoutTime" BU_SG_REL_ MRR2023 SG_ 2331595785 NR_FR_Object_01_aAbsXSD 500;
BA_REL_ "GenSigTimeoutTime" BU_SG_REL_ MRR2023 SG_ 2331595785 NR_FR_Object_01_aAbsY 500;
BA_REL_ "GenSigTimeoutTime" BU_SG_REL_ MRR2023 SG_ 2331595785 NR_FR_Object_01_aAbsYSD 500;
BA_REL_ "GenSigTimeoutTime" BU_SG_REL_ MRR2023 SG_ 2331595785 NR_FR_Object_01_DynamicState 500;
BA_REL_ "GenSigTimeoutTime" BU_SG_REL_ MRR2023 SG_ 2331595785 NR_FR_Object_01_YawAngle 500;
BA_REL_ "GenSigTimeoutTime" BU_SG_REL_ MRR2023 SG_ 2331595785 NR_FR_Object_01_YawAngleSD 500;
BA_REL_ "GenSigTimeoutTime" BU_SG_REL_ MRR2023 SG_ 2331595785 NR_FR_Object_01_Width 500;
BA_REL_ "GenSigTimeoutTime" BU_SG_REL_ MRR2023 SG_ 2331595785 NR_FR_Object_01_WidthSD 500;
BA_REL_ "GenSigTimeoutTime" BU_SG_REL_ MRR2023 SG_ 2331595785 NR_FR_Object_01_Length 500;
BA_REL_ "GenSigTimeoutTime" BU_SG_REL_ MRR2023 SG_ 2331595785 NR_FR_Object_01_LengthSD 500;
BA_REL_ "GenSigTimeoutTime" BU_SG_REL_ MRR2023 SG_ 2331595785 NR_FR_Object_01_Class 500;
BA_REL_ "GenSigTimeoutTime" BU_SG_REL_ MRR2023 SG_ 2331595785 NR_FR_Object_01_ClassPlausib 500;
BA_REL_ "GenSigTimeoutTime" BU_SG_REL_ MRR2023 SG_ 2331595785 NR_FR_Object_01_ExistProb 500;
BA_REL_ "GenSigTimeoutTime" BU_SG_REL_ MRR2023 SG_ 2331595785 NR_FR_Object_01_Age 500;
BA_REL_ "GenSigTimeoutTime" BU_SG_REL_ MRR2023 SG_ 2331595785 NR_FR_Object_01_YawRateAbs 500;
BA_REL_ "GenSigTimeoutTime" BU_SG_REL_ MRR2023 SG_ 2331595785 NR_FR_Object_01_YawRateAbsSD 500;
BA_REL_ "GenSigTimeoutTime" BU_SG_REL_ MRR2023 SG_ 2331595785 NR_FR_Object_01_MeasurementState 500;
BA_REL_ "GenSigTimeoutTime" BU_SG_REL_ MRR2023 SG_ 2331595785 NR_FR_Object_02_ID 500;
BA_REL_ "GenSigTimeoutTime" BU_SG_REL_ MRR2023 SG_ 2331595785 NR_FR_Object_02_ReferencePoint 500;
BA_REL_ "GenSigTimeoutTime" BU_SG_REL_ MRR2023 SG_ 2331595785 NR_FR_Object_02_PosX 500;
BA_REL_ "GenSigTimeoutTime" BU_SG_REL_ MRR2023 SG_ 2331595785 NR_FR_Object_02_PosXSD 500;
BA_REL_ "GenSigTimeoutTime" BU_SG_REL_ MRR2023 SG_ 2331595785 NR_FR_Object_02_PosY 500;
BA_REL_ "GenSigTimeoutTime" BU_SG_REL_ MRR2023 SG_ 2331595785 NR_FR_Object_02_PosYSD 500;
BA_REL_ "GenSigTimeoutTime" BU_SG_REL_ MRR2023 SG_ 2331595785 NR_FR_Object_02_vAbsX 500;
BA_REL_ "GenSigTimeoutTime" BU_SG_REL_ MRR2023 SG_ 2331595785 NR_FR_Object_02_vAbsXSD 500;
BA_REL_ "GenSigTimeoutTime" BU_SG_REL_ MRR2023 SG_ 2331595785 NR_FR_Object_02_vAbsY 500;
BA_REL_ "GenSigTimeoutTime" BU_SG_REL_ MRR2023 SG_ 2331595785 NR_FR_Object_02_vAbsYSD 500;
BA_REL_ "GenSigTimeoutTime" BU_SG_REL_ MRR2023 SG_ 2331595785 NR_FR_Object_02_aAbsX 500;
BA_REL_ "GenSigTimeoutTime" BU_SG_REL_ MRR2023 SG_ 2331595785 NR_FR_Object_02_aAbsXSD 500;
BA_REL_ "GenSigTimeoutTime" BU_SG_REL_ MRR2023 SG_ 2331595785 NR_FR_Object_02_aAbsY 500;
BA_REL_ "GenSigTimeoutTime" BU_SG_REL_ MRR2023 SG_ 2331595785 NR_FR_Object_02_aAbsYSD 500;
BA_REL_ "GenSigTimeoutTime" BU_SG_REL_ MRR2023 SG_ 2331595785 NR_FR_Object_02_DynamicState 500;
BA_REL_ "GenSigTimeoutTime" BU_SG_REL_ MRR2023 SG_ 2331595785 NR_FR_Object_02_YawAngle 500;
BA_REL_ "GenSigTimeoutTime" BU_SG_REL_ MRR2023 SG_ 2331595785 NR_FR_Object_02_YawAngleSD 500;
BA_REL_ "GenSigTimeoutTime" BU_SG_REL_ MRR2023 SG_ 2331595785 NR_FR_Object_02_Width 500;
BA_REL_ "GenSigTimeoutTime" BU_SG_REL_ MRR2023 SG_ 2331595785 NR_FR_Object_02_WidthSD 500;
BA_REL_ "GenSigTimeoutTime" BU_SG_REL_ MRR2023 SG_ 2331595785 NR_FR_Object_02_Length 500;
BA_REL_ "GenSigTimeoutTime" BU_SG_REL_ MRR2023 SG_ 2331595785 NR_FR_Object_02_LengthSD 500;
BA_REL_ "GenSigTimeoutTime" BU_SG_REL_ MRR2023 SG_ 2331595785 NR_FR_Object_02_Class 500;
BA_REL_ "GenSigTimeoutTime" BU_SG_REL_ MRR2023 SG_ 2331595785 NR_FR_Object_02_ClassPlausib 500;
BA_REL_ "GenSigTimeoutTime" BU_SG_REL_ MRR2023 SG_ 2331595785 NR_FR_Object_02_ExistProb 500;
BA_REL_ "GenSigTimeoutTime" BU_SG_REL_ MRR2023 SG_ 2331595785 NR_FR_Object_02_Age 500;
BA_REL_ "GenSigTimeoutTime" BU_SG_REL_ MRR2023 SG_ 2331595785 NR_FR_Object_02_YawRateAbs 500;
BA_REL_ "GenSigTimeoutTime" BU_SG_REL_ MRR2023 SG_ 2331595785 NR_FR_Object_02_YawRateAbsSD 500;
BA_REL_ "GenSigTimeoutTime" BU_SG_REL_ MRR2023 SG_ 2331595785 NR_FR_Object_02_MeasurementState 500;
BA_REL_ "GenSigTimeoutTime" BU_SG_REL_ MRR2023 SG_ 2331595786 NR_FR_Object_03_04_CRC 500;
BA_REL_ "GenSigTimeoutTime" BU_SG_REL_ MRR2023 SG_ 2331595786 NR_FR_Object_03_04_BZ 500;
BA_REL_ "GenSigTimeoutTime" BU_SG_REL_ MRR2023 SG_ 2331595786 NR_FR_Object_03_04_BlockID_02 500;
BA_REL_ "GenSigTimeoutTime" BU_SG_REL_ MRR2023 SG_ 2331595786 NR_FR_Object_03_ID 500;
BA_REL_ "GenSigTimeoutTime" BU_SG_REL_ MRR2023 SG_ 2331595786 NR_FR_Object_03_ReferencePoint 500;
BA_REL_ "GenSigTimeoutTime" BU_SG_REL_ MRR2023 SG_ 2331595786 NR_FR_Object_03_PosX 500;
BA_REL_ "GenSigTimeoutTime" BU_SG_REL_ MRR2023 SG_ 2331595786 NR_FR_Object_03_PosXSD 500;
BA_REL_ "GenSigTimeoutTime" BU_SG_REL_ MRR2023 SG_ 2331595786 NR_FR_Object_03_PosY 500;
BA_REL_ "GenSigTimeoutTime" BU_SG_REL_ MRR2023 SG_ 2331595786 NR_FR_Object_03_PosYSD 500;
BA_REL_ "GenSigTimeoutTime" BU_SG_REL_ MRR2023 SG_ 2331595786 NR_FR_Object_03_vAbsX 500;
BA_REL_ "GenSigTimeoutTime" BU_SG_REL_ MRR2023 SG_ 2331595786 NR_FR_Object_03_vAbsXSD 500;
BA_REL_ "GenSigTimeoutTime" BU_SG_REL_ MRR2023 SG_ 2331595786 NR_FR_Object_03_vAbsY 500;
BA_REL_ "GenSigTimeoutTime" BU_SG_REL_ MRR2023 SG_ 2331595786 NR_FR_Object_03_vAbsYSD 500;
BA_REL_ "GenSigTimeoutTime" BU_SG_REL_ MRR2023 SG_ 2331595786 NR_FR_Object_03_aAbsX 500;
BA_REL_ "GenSigTimeoutTime" BU_SG_REL_ MRR2023 SG_ 2331595786 NR_FR_Object_03_aAbsXSD 500;
BA_REL_ "GenSigTimeoutTime" BU_SG_REL_ MRR2023 SG_ 2331595786 NR_FR_Object_03_aAbsY 500;
BA_REL_ "GenSigTimeoutTime" BU_SG_REL_ MRR2023 SG_ 2331595786 NR_FR_Object_03_aAbsYSD 500;
BA_REL_ "GenSigTimeoutTime" BU_SG_REL_ MRR2023 SG_ 2331595786 NR_FR_Object_03_DynamicState 500;
BA_REL_ "GenSigTimeoutTime" BU_SG_REL_ MRR2023 SG_ 2331595786 NR_FR_Object_03_YawAngle 500;
BA_REL_ "GenSigTimeoutTime" BU_SG_REL_ MRR2023 SG_ 2331595786 NR_FR_Object_03_YawAngleSD 500;
BA_REL_ "GenSigTimeoutTime" BU_SG_REL_ MRR2023 SG_ 2331595786 NR_FR_Object_03_Width 500;
BA_REL_ "GenSigTimeoutTime" BU_SG_REL_ MRR2023 SG_ 2331595786 NR_FR_Object_03_WidthSD 500;
BA_REL_ "GenSigTimeoutTime" BU_SG_REL_ MRR2023 SG_ 2331595786 NR_FR_Object_03_Length 500;
BA_REL_ "GenSigTimeoutTime" BU_SG_REL_ MRR2023 SG_ 2331595786 NR_FR_Object_03_LengthSD 500;
BA_REL_ "GenSigTimeoutTime" BU_SG_REL_ MRR2023 SG_ 2331595786 NR_FR_Object_03_Class 500;
BA_REL_ "GenSigTimeoutTime" BU_SG_REL_ MRR2023 SG_ 2331595786 NR_FR_Object_03_ClassPlausib 500;
BA_REL_ "GenSigTimeoutTime" BU_SG_REL_ MRR2023 SG_ 2331595786 NR_FR_Object_03_ExistProb 500;
BA_REL_ "GenSigTimeoutTime" BU_SG_REL_ MRR2023 SG_ 2331595786 NR_FR_Object_03_Age 500;
BA_REL_ "GenSigTimeoutTime" BU_SG_REL_ MRR2023 SG_ 2331595786 NR_FR_Object_03_YawRateAbs 500;
BA_REL_ "GenSigTimeoutTime" BU_SG_REL_ MRR2023 SG_ 2331595786 NR_FR_Object_03_YawRateAbsSD 500;
BA_REL_ "GenSigTimeoutTime" BU_SG_REL_ MRR2023 SG_ 2331595786 NR_FR_Object_03_MeasurementState 500;
BA_REL_ "GenSigTimeoutTime" BU_SG_REL_ MRR2023 SG_ 2331595786 NR_FR_Object_04_ID 500;
BA_REL_ "GenSigTimeoutTime" BU_SG_REL_ MRR2023 SG_ 2331595786 NR_FR_Object_04_ReferencePoint 500;
BA_REL_ "GenSigTimeoutTime" BU_SG_REL_ MRR2023 SG_ 2331595786 NR_FR_Object_04_PosX 500;
BA_REL_ "GenSigTimeoutTime" BU_SG_REL_ MRR2023 SG_ 2331595786 NR_FR_Object_04_PosXSD 500;
BA_REL_ "GenSigTimeoutTime" BU_SG_REL_ MRR2023 SG_ 2331595786 NR_FR_Object_04_PosY 500;
BA_REL_ "GenSigTimeoutTime" BU_SG_REL_ MRR2023 SG_ 2331595786 NR_FR_Object_04_PosYSD 500;
BA_REL_ "GenSigTimeoutTime" BU_SG_REL_ MRR2023 SG_ 2331595786 NR_FR_Object_04_vAbsX 500;
BA_REL_ "GenSigTimeoutTime" BU_SG_REL_ MRR2023 SG_ 2331595786 NR_FR_Object_04_vAbsXSD 500;
BA_REL_ "GenSigTimeoutTime" BU_SG_REL_ MRR2023 SG_ 2331595786 NR_FR_Object_04_vAbsY 500;
BA_REL_ "GenSigTimeoutTime" BU_SG_REL_ MRR2023 SG_ 2331595786 NR_FR_Object_04_vAbsYSD 500;
BA_REL_ "GenSigTimeoutTime" BU_SG_REL_ MRR2023 SG_ 2331595786 NR_FR_Object_04_aAbsX 500;
BA_REL_ "GenSigTimeoutTime" BU_SG_REL_ MRR2023 SG_ 2331595786 NR_FR_Object_04_aAbsXSD 500;
BA_REL_ "GenSigTimeoutTime" BU_SG_REL_ MRR2023 SG_ 2331595786 NR_FR_Object_04_aAbsY 500;
BA_REL_ "GenSigTimeoutTime" BU_SG_REL_ MRR2023 SG_ 2331595786 NR_FR_Object_04_aAbsYSD 500;
BA_REL_ "GenSigTimeoutTime" BU_SG_REL_ MRR2023 SG_ 2331595786 NR_FR_Object_04_DynamicState 500;
BA_REL_ "GenSigTimeoutTime" BU_SG_REL_ MRR2023 SG_ 2331595786 NR_FR_Object_04_YawAngle 500;
BA_REL_ "GenSigTimeoutTime" BU_SG_REL_ MRR2023 SG_ 2331595786 NR_FR_Object_04_YawAngleSD 500;
BA_REL_ "GenSigTimeoutTime" BU_SG_REL_ MRR2023 SG_ 2331595786 NR_FR_Object_04_Width 500;
BA_REL_ "GenSigTimeoutTime" BU_SG_REL_ MRR2023 SG_ 2331595786 NR_FR_Object_04_WidthSD 500;
BA_REL_ "GenSigTimeoutTime" BU_SG_REL_ MRR2023 SG_ 2331595786 NR_FR_Object_04_Length 500;
BA_REL_ "GenSigTimeoutTime" BU_SG_REL_ MRR2023 SG_ 2331595786 NR_FR_Object_04_LengthSD 500;
BA_REL_ "GenSigTimeoutTime" BU_SG_REL_ MRR2023 SG_ 2331595786 NR_FR_Object_04_Class 500;
BA_REL_ "GenSigTimeoutTime" BU_SG_REL_ MRR2023 SG_ 2331595786 NR_FR_Object_04_ClassPlausib 500;
BA_REL_ "GenSigTimeoutTime" BU_SG_REL_ MRR2023 SG_ 2331595786 NR_FR_Object_04_ExistProb 500;
BA_REL_ "GenSigTimeoutTime" BU_SG_REL_ MRR2023 SG_ 2331595786 NR_FR_Object_04_Age 500;
BA_REL_ "GenSigTimeoutTime" BU_SG_REL_ MRR2023 SG_ 2331595786 NR_FR_Object_04_YawRateAbs 500;
BA_REL_ "GenSigTimeoutTime" BU_SG_REL_ MRR2023 SG_ 2331595786 NR_FR_Object_04_YawRateAbsSD 500;
BA_REL_ "GenSigTimeoutTime" BU_SG_REL_ MRR2023 SG_ 2331595786 NR_FR_Object_04_MeasurementState 500;
BA_REL_ "GenSigTimeoutTime" BU_SG_REL_ MRR2023 SG_ 2331595787 NR_FR_Object_05_06_CRC 500;
BA_REL_ "GenSigTimeoutTime" BU_SG_REL_ MRR2023 SG_ 2331595787 NR_FR_Object_05_06_BZ 500;
BA_REL_ "GenSigTimeoutTime" BU_SG_REL_ MRR2023 SG_ 2331595787 NR_FR_Object_05_06_BlockID_02 500;
BA_REL_ "GenSigTimeoutTime" BU_SG_REL_ MRR2023 SG_ 2331595787 NR_FR_Object_05_ID 500;
BA_REL_ "GenSigTimeoutTime" BU_SG_REL_ MRR2023 SG_ 2331595787 NR_FR_Object_05_ReferencePoint 500;
BA_REL_ "GenSigTimeoutTime" BU_SG_REL_ MRR2023 SG_ 2331595787 NR_FR_Object_05_PosX 500;
BA_REL_ "GenSigTimeoutTime" BU_SG_REL_ MRR2023 SG_ 2331595787 NR_FR_Object_05_PosXSD 500;
BA_REL_ "GenSigTimeoutTime" BU_SG_REL_ MRR2023 SG_ 2331595787 NR_FR_Object_05_PosY 500;
BA_REL_ "GenSigTimeoutTime" BU_SG_REL_ MRR2023 SG_ 2331595787 NR_FR_Object_05_PosYSD 500;
BA_REL_ "GenSigTimeoutTime" BU_SG_REL_ MRR2023 SG_ 2331595787 NR_FR_Object_05_vAbsX 500;
BA_REL_ "GenSigTimeoutTime" BU_SG_REL_ MRR2023 SG_ 2331595787 NR_FR_Object_05_vAbsXSD 500;
BA_REL_ "GenSigTimeoutTime" BU_SG_REL_ MRR2023 SG_ 2331595787 NR_FR_Object_05_vAbsY 500;
BA_REL_ "GenSigTimeoutTime" BU_SG_REL_ MRR2023 SG_ 2331595787 NR_FR_Object_05_vAbsYSD 500;
BA_REL_ "GenSigTimeoutTime" BU_SG_REL_ MRR2023 SG_ 2331595787 NR_FR_Object_05_aAbsX 500;
BA_REL_ "GenSigTimeoutTime" BU_SG_REL_ MRR2023 SG_ 2331595787 NR_FR_Object_05_aAbsXSD 500;
BA_REL_ "GenSigTimeoutTime" BU_SG_REL_ MRR2023 SG_ 2331595787 NR_FR_Object_05_aAbsY 500;
BA_REL_ "GenSigTimeoutTime" BU_SG_REL_ MRR2023 SG_ 2331595787 NR_FR_Object_05_aAbsYSD 500;
BA_REL_ "GenSigTimeoutTime" BU_SG_REL_ MRR2023 SG_ 2331595787 NR_FR_Object_05_DynamicState 500;
BA_REL_ "GenSigTimeoutTime" BU_SG_REL_ MRR2023 SG_ 2331595787 NR_FR_Object_05_YawAngle 500;
BA_REL_ "GenSigTimeoutTime" BU_SG_REL_ MRR2023 SG_ 2331595787 NR_FR_Object_05_YawAngleSD 500;
BA_REL_ "GenSigTimeoutTime" BU_SG_REL_ MRR2023 SG_ 2331595787 NR_FR_Object_05_Width 500;
BA_REL_ "GenSigTimeoutTime" BU_SG_REL_ MRR2023 SG_ 2331595787 NR_FR_Object_05_WidthSD 500;
BA_REL_ "GenSigTimeoutTime" BU_SG_REL_ MRR2023 SG_ 2331595787 NR_FR_Object_05_Length 500;
BA_REL_ "GenSigTimeoutTime" BU_SG_REL_ MRR2023 SG_ 2331595787 NR_FR_Object_05_LengthSD 500;
BA_REL_ "GenSigTimeoutTime" BU_SG_REL_ MRR2023 SG_ 2331595787 NR_FR_Object_05_Class 500;
BA_REL_ "GenSigTimeoutTime" BU_SG_REL_ MRR2023 SG_ 2331595787 NR_FR_Object_05_ClassPlausib 500;
BA_REL_ "GenSigTimeoutTime" BU_SG_REL_ MRR2023 SG_ 2331595787 NR_FR_Object_05_ExistProb 500;
BA_REL_ "GenSigTimeoutTime" BU_SG_REL_ MRR2023 SG_ 2331595787 NR_FR_Object_05_Age 500;
BA_REL_ "GenSigTimeoutTime" BU_SG_REL_ MRR2023 SG_ 2331595787 NR_FR_Object_05_YawRateAbs 500;
BA_REL_ "GenSigTimeoutTime" BU_SG_REL_ MRR2023 SG_ 2331595787 NR_FR_Object_05_YawRateAbsSD 500;
BA_REL_ "GenSigTimeoutTime" BU_SG_REL_ MRR2023 SG_ 2331595787 NR_FR_Object_05_MeasurementState 500;
BA_REL_ "GenSigTimeoutTime" BU_SG_REL_ MRR2023 SG_ 2331595787 NR_FR_Object_06_ID 500;
BA_REL_ "GenSigTimeoutTime" BU_SG_REL_ MRR2023 SG_ 2331595787 NR_FR_Object_06_ReferencePoint 500;
BA_REL_ "GenSigTimeoutTime" BU_SG_REL_ MRR2023 SG_ 2331595787 NR_FR_Object_06_PosX 500;
BA_REL_ "GenSigTimeoutTime" BU_SG_REL_ MRR2023 SG_ 2331595787 NR_FR_Object_06_PosXSD 500;
BA_REL_ "GenSigTimeoutTime" BU_SG_REL_ MRR2023 SG_ 2331595787 NR_FR_Object_06_PosY 500;
BA_REL_ "GenSigTimeoutTime" BU_SG_REL_ MRR2023 SG_ 2331595787 NR_FR_Object_06_PosYSD 500;
BA_REL_ "GenSigTimeoutTime" BU_SG_REL_ MRR2023 SG_ 2331595787 NR_FR_Object_06_vAbsX 500;
BA_REL_ "GenSigTimeoutTime" BU_SG_REL_ MRR2023 SG_ 2331595787 NR_FR_Object_06_vAbsXSD 500;
BA_REL_ "GenSigTimeoutTime" BU_SG_REL_ MRR2023 SG_ 2331595787 NR_FR_Object_06_vAbsY 500;
BA_REL_ "GenSigTimeoutTime" BU_SG_REL_ MRR2023 SG_ 2331595787 NR_FR_Object_06_vAbsYSD 500;
BA_REL_ "GenSigTimeoutTime" BU_SG_REL_ MRR2023 SG_ 2331595787 NR_FR_Object_06_aAbsX 500;
BA_REL_ "GenSigTimeoutTime" BU_SG_REL_ MRR2023 SG_ 2331595787 NR_FR_Object_06_aAbsXSD 500;
BA_REL_ "GenSigTimeoutTime" BU_SG_REL_ MRR2023 SG_ 2331595787 NR_FR_Object_06_aAbsY 500;
BA_REL_ "GenSigTimeoutTime" BU_SG_REL_ MRR2023 SG_ 2331595787 NR_FR_Object_06_aAbsYSD 500;
BA_REL_ "GenSigTimeoutTime" BU_SG_REL_ MRR2023 SG_ 2331595787 NR_FR_Object_06_DynamicState 500;
BA_REL_ "GenSigTimeoutTime" BU_SG_REL_ MRR2023 SG_ 2331595787 NR_FR_Object_06_YawAngle 500;
BA_REL_ "GenSigTimeoutTime" BU_SG_REL_ MRR2023 SG_ 2331595787 NR_FR_Object_06_YawAngleSD 500;
BA_REL_ "GenSigTimeoutTime" BU_SG_REL_ MRR2023 SG_ 2331595787 NR_FR_Object_06_Width 500;
BA_REL_ "GenSigTimeoutTime" BU_SG_REL_ MRR2023 SG_ 2331595787 NR_FR_Object_06_WidthSD 500;
BA_REL_ "GenSigTimeoutTime" BU_SG_REL_ MRR2023 SG_ 2331595787 NR_FR_Object_06_Length 500;
BA_REL_ "GenSigTimeoutTime" BU_SG_REL_ MRR2023 SG_ 2331595787 NR_FR_Object_06_LengthSD 500;
BA_REL_ "GenSigTimeoutTime" BU_SG_REL_ MRR2023 SG_ 2331595787 NR_FR_Object_06_Class 500;
BA_REL_ "GenSigTimeoutTime" BU_SG_REL_ MRR2023 SG_ 2331595787 NR_FR_Object_06_ClassPlausib 500;
BA_REL_ "GenSigTimeoutTime" BU_SG_REL_ MRR2023 SG_ 2331595787 NR_FR_Object_06_ExistProb 500;
BA_REL_ "GenSigTimeoutTime" BU_SG_REL_ MRR2023 SG_ 2331595787 NR_FR_Object_06_Age 500;
BA_REL_ "GenSigTimeoutTime" BU_SG_REL_ MRR2023 SG_ 2331595787 NR_FR_Object_06_YawRateAbs 500;
BA_REL_ "GenSigTimeoutTime" BU_SG_REL_ MRR2023 SG_ 2331595787 NR_FR_Object_06_YawRateAbsSD 500;
BA_REL_ "GenSigTimeoutTime" BU_SG_REL_ MRR2023 SG_ 2331595787 NR_FR_Object_06_MeasurementState 500;
BA_REL_ "GenSigTimeoutTime" BU_SG_REL_ MRR2023 SG_ 2331595788 NR_FR_Object_07_08_CRC 500;
BA_REL_ "GenSigTimeoutTime" BU_SG_REL_ MRR2023 SG_ 2331595788 NR_FR_Object_07_08_BZ 500;
BA_REL_ "GenSigTimeoutTime" BU_SG_REL_ MRR2023 SG_ 2331595788 NR_FR_Object_07_08_BlockID_02 500;
BA_REL_ "GenSigTimeoutTime" BU_SG_REL_ MRR2023 SG_ 2331595788 NR_FR_Object_07_ID 500;
BA_REL_ "GenSigTimeoutTime" BU_SG_REL_ MRR2023 SG_ 2331595788 NR_FR_Object_07_ReferencePoint 500;
BA_REL_ "GenSigTimeoutTime" BU_SG_REL_ MRR2023 SG_ 2331595788 NR_FR_Object_07_PosX 500;
BA_REL_ "GenSigTimeoutTime" BU_SG_REL_ MRR2023 SG_ 2331595788 NR_FR_Object_07_PosXSD 500;
BA_REL_ "GenSigTimeoutTime" BU_SG_REL_ MRR2023 SG_ 2331595788 NR_FR_Object_07_PosY 500;
BA_REL_ "GenSigTimeoutTime" BU_SG_REL_ MRR2023 SG_ 2331595788 NR_FR_Object_07_PosYSD 500;
BA_REL_ "GenSigTimeoutTime" BU_SG_REL_ MRR2023 SG_ 2331595788 NR_FR_Object_07_vAbsX 500;
BA_REL_ "GenSigTimeoutTime" BU_SG_REL_ MRR2023 SG_ 2331595788 NR_FR_Object_07_vAbsXSD 500;
BA_REL_ "GenSigTimeoutTime" BU_SG_REL_ MRR2023 SG_ 2331595788 NR_FR_Object_07_vAbsY 500;
BA_REL_ "GenSigTimeoutTime" BU_SG_REL_ MRR2023 SG_ 2331595788 NR_FR_Object_07_vAbsYSD 500;
BA_REL_ "GenSigTimeoutTime" BU_SG_REL_ MRR2023 SG_ 2331595788 NR_FR_Object_07_aAbsX 500;
BA_REL_ "GenSigTimeoutTime" BU_SG_REL_ MRR2023 SG_ 2331595788 NR_FR_Object_07_aAbsXSD 500;
BA_REL_ "GenSigTimeoutTime" BU_SG_REL_ MRR2023 SG_ 2331595788 NR_FR_Object_07_aAbsY 500;
BA_REL_ "GenSigTimeoutTime" BU_SG_REL_ MRR2023 SG_ 2331595788 NR_FR_Object_07_aAbsYSD 500;
BA_REL_ "GenSigTimeoutTime" BU_SG_REL_ MRR2023 SG_ 2331595788 NR_FR_Object_07_DynamicState 500;
BA_REL_ "GenSigTimeoutTime" BU_SG_REL_ MRR2023 SG_ 2331595788 NR_FR_Object_07_YawAngle 500;
BA_REL_ "GenSigTimeoutTime" BU_SG_REL_ MRR2023 SG_ 2331595788 NR_FR_Object_07_YawAngleSD 500;
BA_REL_ "GenSigTimeoutTime" BU_SG_REL_ MRR2023 SG_ 2331595788 NR_FR_Object_07_Width 500;
BA_REL_ "GenSigTimeoutTime" BU_SG_REL_ MRR2023 SG_ 2331595788 NR_FR_Object_07_WidthSD 500;
BA_REL_ "GenSigTimeoutTime" BU_SG_REL_ MRR2023 SG_ 2331595788 NR_FR_Object_07_Length 500;
BA_REL_ "GenSigTimeoutTime" BU_SG_REL_ MRR2023 SG_ 2331595788 NR_FR_Object_07_LengthSD 500;
BA_REL_ "GenSigTimeoutTime" BU_SG_REL_ MRR2023 SG_ 2331595788 NR_FR_Object_07_Class 500;
BA_REL_ "GenSigTimeoutTime" BU_SG_REL_ MRR2023 SG_ 2331595788 NR_FR_Object_07_ClassPlausib 500;
BA_REL_ "GenSigTimeoutTime" BU_SG_REL_ MRR2023 SG_ 2331595788 NR_FR_Object_07_ExistProb 500;
BA_REL_ "GenSigTimeoutTime" BU_SG_REL_ MRR2023 SG_ 2331595788 NR_FR_Object_07_Age 500;
BA_REL_ "GenSigTimeoutTime" BU_SG_REL_ MRR2023 SG_ 2331595788 NR_FR_Object_07_YawRateAbs 500;
BA_REL_ "GenSigTimeoutTime" BU_SG_REL_ MRR2023 SG_ 2331595788 NR_FR_Object_07_YawRateAbsSD 500;
BA_REL_ "GenSigTimeoutTime" BU_SG_REL_ MRR2023 SG_ 2331595788 NR_FR_Object_07_MeasurementState 500;
BA_REL_ "GenSigTimeoutTime" BU_SG_REL_ MRR2023 SG_ 2331595788 NR_FR_Object_08_ID 500;
BA_REL_ "GenSigTimeoutTime" BU_SG_REL_ MRR2023 SG_ 2331595788 NR_FR_Object_08_ReferencePoint 500;
BA_REL_ "GenSigTimeoutTime" BU_SG_REL_ MRR2023 SG_ 2331595788 NR_FR_Object_08_PosX 500;
BA_REL_ "GenSigTimeoutTime" BU_SG_REL_ MRR2023 SG_ 2331595788 NR_FR_Object_08_PosXSD 500;
BA_REL_ "GenSigTimeoutTime" BU_SG_REL_ MRR2023 SG_ 2331595788 NR_FR_Object_08_PosY 500;
BA_REL_ "GenSigTimeoutTime" BU_SG_REL_ MRR2023 SG_ 2331595788 NR_FR_Object_08_PosYSD 500;
BA_REL_ "GenSigTimeoutTime" BU_SG_REL_ MRR2023 SG_ 2331595788 NR_FR_Object_08_vAbsX 500;
BA_REL_ "GenSigTimeoutTime" BU_SG_REL_ MRR2023 SG_ 2331595788 NR_FR_Object_08_vAbsXSD 500;
BA_REL_ "GenSigTimeoutTime" BU_SG_REL_ MRR2023 SG_ 2331595788 NR_FR_Object_08_vAbsY 500;
BA_REL_ "GenSigTimeoutTime" BU_SG_REL_ MRR2023 SG_ 2331595788 NR_FR_Object_08_vAbsYSD 500;
BA_REL_ "GenSigTimeoutTime" BU_SG_REL_ MRR2023 SG_ 2331595788 NR_FR_Object_08_aAbsX 500;
BA_REL_ "GenSigTimeoutTime" BU_SG_REL_ MRR2023 SG_ 2331595788 NR_FR_Object_08_aAbsXSD 500;
BA_REL_ "GenSigTimeoutTime" BU_SG_REL_ MRR2023 SG_ 2331595788 NR_FR_Object_08_aAbsY 500;
BA_REL_ "GenSigTimeoutTime" BU_SG_REL_ MRR2023 SG_ 2331595788 NR_FR_Object_08_aAbsYSD 500;
BA_REL_ "GenSigTimeoutTime" BU_SG_REL_ MRR2023 SG_ 2331595788 NR_FR_Object_08_DynamicState 500;
BA_REL_ "GenSigTimeoutTime" BU_SG_REL_ MRR2023 SG_ 2331595788 NR_FR_Object_08_YawAngle 500;
BA_REL_ "GenSigTimeoutTime" BU_SG_REL_ MRR2023 SG_ 2331595788 NR_FR_Object_08_YawAngleSD 500;
BA_REL_ "GenSigTimeoutTime" BU_SG_REL_ MRR2023 SG_ 2331595788 NR_FR_Object_08_Width 500;
BA_REL_ "GenSigTimeoutTime" BU_SG_REL_ MRR2023 SG_ 2331595788 NR_FR_Object_08_WidthSD 500;
BA_REL_ "GenSigTimeoutTime" BU_SG_REL_ MRR2023 SG_ 2331595788 NR_FR_Object_08_Length 500;
BA_REL_ "GenSigTimeoutTime" BU_SG_REL_ MRR2023 SG_ 2331595788 NR_FR_Object_08_LengthSD 500;
BA_REL_ "GenSigTimeoutTime" BU_SG_REL_ MRR2023 SG_ 2331595788 NR_FR_Object_08_Class 500;
BA_REL_ "GenSigTimeoutTime" BU_SG_REL_ MRR2023 SG_ 2331595788 NR_FR_Object_08_ClassPlausib 500;
BA_REL_ "GenSigTimeoutTime" BU_SG_REL_ MRR2023 SG_ 2331595788 NR_FR_Object_08_ExistProb 500;
BA_REL_ "GenSigTimeoutTime" BU_SG_REL_ MRR2023 SG_ 2331595788 NR_FR_Object_08_Age 500;
BA_REL_ "GenSigTimeoutTime" BU_SG_REL_ MRR2023 SG_ 2331595788 NR_FR_Object_08_YawRateAbs 500;
BA_REL_ "GenSigTimeoutTime" BU_SG_REL_ MRR2023 SG_ 2331595788 NR_FR_Object_08_YawRateAbsSD 500;
BA_REL_ "GenSigTimeoutTime" BU_SG_REL_ MRR2023 SG_ 2331595788 NR_FR_Object_08_MeasurementState 500;
VAL_ 2331595780 NR_FL_Object_09_ID 0 "No_object" 255 "Init" ;
VAL_ 2331595780 NR_FL_Object_09_ReferencePoint 0 "unknown" 1 "front_left" 2 "front_center" 3 "front_right" 4 "right_center" 5 "rear_right" 6 "rear_center" 7 "rear_left" 8 "left_center" 9 "object_center" 10 "any_side_center" 15 "Init" ;
VAL_ 2331595780 NR_FL_Object_09_PosX 16383 "Init" ;
VAL_ 2331595780 NR_FL_Object_09_PosXSD 255 "Init" ;
VAL_ 2331595780 NR_FL_Object_09_PosY 8191 "Init" ;
VAL_ 2331595780 NR_FL_Object_09_PosYSD 255 "Init" ;
VAL_ 2331595780 NR_FL_Object_09_vAbsX 4095 "Init" ;
VAL_ 2331595780 NR_FL_Object_09_vAbsXSD 63 "Init" ;
VAL_ 2331595780 NR_FL_Object_09_vAbsY 4095 "Init" ;
VAL_ 2331595780 NR_FL_Object_09_vAbsYSD 63 "Init" ;
VAL_ 2331595780 NR_FL_Object_09_aAbsX 511 "Init" ;
VAL_ 2331595780 NR_FL_Object_09_aAbsXSD 63 "Init" ;
VAL_ 2331595780 NR_FL_Object_09_aAbsY 511 "Init" ;
VAL_ 2331595780 NR_FL_Object_09_aAbsYSD 63 "Init" ;
VAL_ 2331595780 NR_FL_Object_09_DynamicState 0 "moving" 1 "stationary" 2 "stopped" 3 "Init" ;
VAL_ 2331595780 NR_FL_Object_09_YawAngle 4095 "Init" ;
VAL_ 2331595780 NR_FL_Object_09_YawAngleSD 511 "Init" ;
VAL_ 2331595780 NR_FL_Object_09_Width 255 "Init" ;
VAL_ 2331595780 NR_FL_Object_09_WidthSD 127 "Init" ;
VAL_ 2331595780 NR_FL_Object_09_Length 1023 "Init" ;
VAL_ 2331595780 NR_FL_Object_09_LengthSD 127 "Init" ;
VAL_ 2331595780 NR_FL_Object_09_Class 0 "unknown" 1 "reserved" 2 "reserved" 3 "pedestrian" 4 "reserved" 5 "bicycle" 6 "motorcycle" 7 "car" 8 "reserved" 9 "truck" 10 "reserved" 11 "reserved" 12 "reserved" 13 "reserved" 15 "Init" ;
VAL_ 2331595780 NR_FL_Object_09_ClassPlausib 15 "Init" ;
VAL_ 2331595780 NR_FL_Object_09_ExistProb 127 "Init" ;
VAL_ 2331595780 NR_FL_Object_09_Age 127 "Init" ;
VAL_ 2331595780 NR_FL_Object_09_YawRateAbs 4095 "Init" ;
VAL_ 2331595780 NR_FL_Object_09_YawRateAbsSD 63 "Init" ;
VAL_ 2331595780 NR_FL_Object_09_MeasurementState 0 "predicted" 1 "measured" ;
VAL_ 2331595780 NR_FL_Object_10_ID 0 "No_object" 255 "Init" ;
VAL_ 2331595780 NR_FL_Object_10_ReferencePoint 0 "unknown" 1 "front_left" 2 "front_center" 3 "front_right" 4 "right_center" 5 "rear_right" 6 "rear_center" 7 "rear_left" 8 "left_center" 9 "object_center" 10 "any_side_center" 15 "Init" ;
VAL_ 2331595780 NR_FL_Object_10_PosX 16383 "Init" ;
VAL_ 2331595780 NR_FL_Object_10_PosXSD 255 "Init" ;
VAL_ 2331595780 NR_FL_Object_10_PosY 8191 "Init" ;
VAL_ 2331595780 NR_FL_Object_10_PosYSD 255 "Init" ;
VAL_ 2331595780 NR_FL_Object_10_vAbsX 4095 "Init" ;
VAL_ 2331595780 NR_FL_Object_10_vAbsXSD 63 "Init" ;
VAL_ 2331595780 NR_FL_Object_10_vAbsY 4095 "Init" ;
VAL_ 2331595780 NR_FL_Object_10_vAbsYSD 63 "Init" ;
VAL_ 2331595780 NR_FL_Object_10_aAbsX 511 "Init" ;
VAL_ 2331595780 NR_FL_Object_10_aAbsXSD 63 "Init" ;
VAL_ 2331595780 NR_FL_Object_10_aAbsY 511 "Init" ;
VAL_ 2331595780 NR_FL_Object_10_aAbsYSD 63 "Init" ;
VAL_ 2331595780 NR_FL_Object_10_DynamicState 0 "moving" 1 "stationary" 2 "stopped" 3 "Init" ;
VAL_ 2331595780 NR_FL_Object_10_YawAngle 4095 "Init" ;
VAL_ 2331595780 NR_FL_Object_10_YawAngleSD 511 "Init" ;
VAL_ 2331595780 NR_FL_Object_10_Width 255 "Init" ;
VAL_ 2331595780 NR_FL_Object_10_WidthSD 127 "Init" ;
VAL_ 2331595780 NR_FL_Object_10_Length 1023 "Init" ;
VAL_ 2331595780 NR_FL_Object_10_LengthSD 127 "Init" ;
VAL_ 2331595780 NR_FL_Object_10_Class 0 "unknown" 1 "reserved" 2 "reserved" 3 "pedestrian" 4 "reserved" 5 "bicycle" 6 "motorcycle" 7 "car" 8 "reserved" 9 "truck" 10 "reserved" 11 "reserved" 12 "reserved" 13 "reserved" 15 "Init" ;
VAL_ 2331595780 NR_FL_Object_10_ClassPlausib 15 "Init" ;
VAL_ 2331595780 NR_FL_Object_10_ExistProb 127 "Init" ;
VAL_ 2331595780 NR_FL_Object_10_Age 127 "Init" ;
VAL_ 2331595780 NR_FL_Object_10_YawRateAbs 4095 "Init" ;
VAL_ 2331595780 NR_FL_Object_10_YawRateAbsSD 63 "Init" ;
VAL_ 2331595780 NR_FL_Object_10_MeasurementState 0 "predicted" 1 "measured" ;
VAL_ 2331595852 NR_FL_Structure_left_LatDist 511 "Init" ;
VAL_ 2331595852 NR_FL_Structure_left_Type 0 "inactive" 1 "continuous_structural" 2 "linked_structural" 3 "irregular_or_unknown" 4 "point" ;
VAL_ 2331595852 NR_FL_Structure_left_ExistProb 127 "Init" ;
VAL_ 2331595826 NR_FR_ShortTrackCal_State 0 "inaktive" 1 "waiting" 2 "active" 3 "ok" 4 "not_ok" 5 "reserved" 6 "reserved" 7 "Init" ;
VAL_ 2331595826 NR_FR_Cal_resp 0 "OFF" 1 "active" 2 "finished" 3 "suspend" 4 "passive" 5 "reserve" 6 "reserve" 7 "failure" ;
VAL_ 2331595826 NR_FR_CalibrationMode 0 "OFF_Init" 1 "EOL_stationary" 2 "autoalignment" 3 "short_track" 4 "service_dynamic" 5 "spc_continue" 6 "service_stationary" 7 "overwrite" ;
VAL_ 2331595826 NR_FR_resp_val 1015 "not_correct_calibrated" 1016 "not_calibrated" 1017 "target_not_found" 1018 "target_power_too_high" 1019 "angle_tolerance_failure" 1020 "target_not_stable" 1021 "storage_failed" 1022 "abort" 1023 "precondition_failure" ;
VAL_ 2331595826 NR_FR_QualFactorAutoCalib 0 "unknown_Init" 1 "precise" 2 "imprecise" 3 "failure" ;
VAL_ 2331595791 NR_FR_Contour_right_01_x01 8191 "Init" ;
VAL_ 2331595791 NR_FR_Contour_right_01_y01 2047 "Init" ;
VAL_ 2331595791 NR_FR_Contour_right_01_x02 8191 "Init" ;
VAL_ 2331595791 NR_FR_Contour_right_01_y02 2047 "Init" ;
VAL_ 2331595791 NR_FR_Contour_right_01_x03 8191 "Init" ;
VAL_ 2331595791 NR_FR_Contour_right_01_y03 2047 "Init" ;
VAL_ 2331595791 NR_FR_Contour_right_01_x04 8191 "Init" ;
VAL_ 2331595791 NR_FR_Contour_right_01_y04 2047 "Init" ;
VAL_ 2331595791 NR_FR_Contour_right_01_x05 8191 "Init" ;
VAL_ 2331595791 NR_FR_Contour_right_01_y05 2047 "Init" ;
VAL_ 2331595791 NR_FR_Contour_right_01_x06 8191 "Init" ;
VAL_ 2331595791 NR_FR_Contour_right_01_y06 2047 "Init" ;
VAL_ 2331595791 NR_FR_Contour_right_01_x07 8191 "Init" ;
VAL_ 2331595791 NR_FR_Contour_right_01_y07 2047 "Init" ;
VAL_ 2331595791 NR_FR_Contour_right_01_Type 0 "inactive" 1 "continuous_structural" 2 "linked_structural" 3 "irregular_or_unknown" 4 "point" 7 "Init" ;
VAL_ 2331595791 NR_FR_Contour_right_01_Age 127 "Init" ;
VAL_ 2331595791 NR_FR_Contour_right_02_x01 8191 "Init" ;
VAL_ 2331595791 NR_FR_Contour_right_02_y01 2047 "Init" ;
VAL_ 2331595791 NR_FR_Contour_right_02_x02 8191 "Init" ;
VAL_ 2331595791 NR_FR_Contour_right_02_y02 2047 "Init" ;
VAL_ 2331595791 NR_FR_Contour_right_02_x03 8191 "Init" ;
VAL_ 2331595791 NR_FR_Contour_right_02_y03 2047 "Init" ;
VAL_ 2331595791 NR_FR_Contour_right_02_x04 8191 "Init" ;
VAL_ 2331595791 NR_FR_Contour_right_02_y04 2047 "Init" ;
VAL_ 2331595791 NR_FR_Contour_right_02_x05 8191 "Init" ;
VAL_ 2331595791 NR_FR_Contour_right_02_y05 2047 "Init" ;
VAL_ 2331595791 NR_FR_Contour_right_02_x06 8191 "Init" ;
VAL_ 2331595791 NR_FR_Contour_right_02_y06 2047 "Init" ;
VAL_ 2331595791 NR_FR_Contour_right_02_x07 8191 "Init" ;
VAL_ 2331595791 NR_FR_Contour_right_02_y07 2047 "Init" ;
VAL_ 2331595791 NR_FR_Contour_right_02_Type 0 "inactive" 1 "continuous_structural" 2 "linked_structural" 3 "irregular_or_unknown" 4 "point" 7 "Init" ;
VAL_ 2331595791 NR_FR_Contour_right_02_Age 127 "Init" ;
VAL_ 2331595791 NR_FR_Contour_right_Linkage 0 "not_linked" 1 "linked" ;
VAL_ 2331595782 NR_FR_NotAvailable 0 "available" 1 "not_available" ;
VAL_ 2331595782 NR_FR_Failure 0 "no_failure" 1 "failure" ;
VAL_ 2331595782 NR_FR_Blindness 0 "not_blind" 1 "blind" ;
VAL_ 2331595782 NR_FR_CalibrationState 0 "init" 1 "no_initial_calibration" 2 "CL15_not_confirmed" 3 "misalignment_in_normal_range" 4 "misalignment_plausibility_check" 5 "calibration_out_of_range" 6 "reserved" 7 "reserved" ;
VAL_ 2331595782 NR_FR_Freesight_NOK 0 "Freesight_OK" 1 "Freesight_NOK" ;
VAL_ 2331595782 NR_FR_MeasurementTimeLow 0 "Init" 0 "Fehler" ;
VAL_ 2331595782 NR_FR_MeasurementTimeHigh 0 "Init" 0 "Fehler" ;
VAL_ 2331595782 NR_FR_RangeDegradation_Sect1 0 "0_percent" 1 "25_percent" 2 "50_percent" 3 "75_percent" 4 "100_percent" ;
VAL_ 2331595782 NR_FR_RangeDegradation_Sect2 0 "0_percent" 1 "25_percent" 2 "50_percent" 3 "75_percent" 4 "100_percent" ;
VAL_ 2331595782 NR_FR_RangeDegradation_Sect3 0 "0_percent" 1 "25_percent" 2 "50_percent" 3 "75_percent" 4 "100_percent" ;
VAL_ 2331595782 NR_FR_MeasurementTimeLapNumber 16382 "Init" 16383 "Fehler" ;
VAL_ 2331595782 NR_FR_MeasurementTimeStatus 0 "Init" 1 "PLT_ASIL" 2 "PLT_QM" 3 "Failure" ;
VAL_ 2331595785 NR_FR_Object_01_ID 0 "No_object" 255 "Init" ;
VAL_ 2331595785 NR_FR_Object_01_ReferencePoint 0 "unknown" 1 "front_left" 2 "front_center" 3 "front_right" 4 "right_center" 5 "rear_right" 6 "rear_center" 7 "rear_left" 8 "left_center" 9 "object_center" 10 "any_side_center" 15 "Init" ;
VAL_ 2331595785 NR_FR_Object_01_PosX 16383 "Init" ;
VAL_ 2331595785 NR_FR_Object_01_PosXSD 255 "Init" ;
VAL_ 2331595785 NR_FR_Object_01_PosY 8191 "Init" ;
VAL_ 2331595785 NR_FR_Object_01_PosYSD 255 "Init" ;
VAL_ 2331595785 NR_FR_Object_01_vAbsX 4095 "Init" ;
VAL_ 2331595785 NR_FR_Object_01_vAbsXSD 63 "Init" ;
VAL_ 2331595785 NR_FR_Object_01_vAbsY 4095 "Init" ;
VAL_ 2331595785 NR_FR_Object_01_vAbsYSD 63 "Init" ;
VAL_ 2331595785 NR_FR_Object_01_aAbsX 511 "Init" ;
VAL_ 2331595785 NR_FR_Object_01_aAbsXSD 63 "Init" ;
VAL_ 2331595785 NR_FR_Object_01_aAbsY 511 "Init" ;
VAL_ 2331595785 NR_FR_Object_01_aAbsYSD 63 "Init" ;
VAL_ 2331595785 NR_FR_Object_01_DynamicState 0 "moving" 1 "stationary" 2 "stopped" 3 "Init" ;
VAL_ 2331595785 NR_FR_Object_01_YawAngle 4095 "Init" ;
VAL_ 2331595785 NR_FR_Object_01_YawAngleSD 511 "Init" ;
VAL_ 2331595785 NR_FR_Object_01_Width 255 "Init" ;
VAL_ 2331595785 NR_FR_Object_01_WidthSD 127 "Init" ;
VAL_ 2331595785 NR_FR_Object_01_Length 1023 "Init" ;
VAL_ 2331595785 NR_FR_Object_01_LengthSD 127 "Init" ;
VAL_ 2331595785 NR_FR_Object_01_Class 0 "unknown" 1 "reserved" 2 "reserved" 3 "pedestrian" 4 "reserved" 5 "bicycle" 6 "motorcycle" 7 "car" 8 "reserved" 9 "truck" 10 "reserved" 11 "reserved" 12 "reserved" 13 "reserved" 15 "Init" ;
VAL_ 2331595785 NR_FR_Object_01_ClassPlausib 15 "Init" ;
VAL_ 2331595785 NR_FR_Object_01_ExistProb 127 "Init" ;
VAL_ 2331595785 NR_FR_Object_01_Age 127 "Init" ;
VAL_ 2331595785 NR_FR_Object_01_YawRateAbs 4095 "Init" ;
VAL_ 2331595785 NR_FR_Object_01_YawRateAbsSD 63 "Init" ;
VAL_ 2331595785 NR_FR_Object_01_MeasurementState 0 "predicted" 1 "measured" ;
VAL_ 2331595785 NR_FR_Object_02_ID 0 "No_object" 255 "Init" ;
VAL_ 2331595785 NR_FR_Object_02_ReferencePoint 0 "unknown" 1 "front_left" 2 "front_center" 3 "front_right" 4 "right_center" 5 "rear_right" 6 "rear_center" 7 "rear_left" 8 "left_center" 9 "object_center" 10 "any_side_center" 15 "Init" ;
VAL_ 2331595785 NR_FR_Object_02_PosX 16383 "Init" ;
VAL_ 2331595785 NR_FR_Object_02_PosXSD 255 "Init" ;
VAL_ 2331595785 NR_FR_Object_02_PosY 8191 "Init" ;
VAL_ 2331595785 NR_FR_Object_02_PosYSD 255 "Init" ;
VAL_ 2331595785 NR_FR_Object_02_vAbsX 4095 "Init" ;
VAL_ 2331595785 NR_FR_Object_02_vAbsXSD 63 "Init" ;
VAL_ 2331595785 NR_FR_Object_02_vAbsY 4095 "Init" ;
VAL_ 2331595785 NR_FR_Object_02_vAbsYSD 63 "Init" ;
VAL_ 2331595785 NR_FR_Object_02_aAbsX 511 "Init" ;
VAL_ 2331595785 NR_FR_Object_02_aAbsXSD 63 "Init" ;
VAL_ 2331595785 NR_FR_Object_02_aAbsY 511 "Init" ;
VAL_ 2331595785 NR_FR_Object_02_aAbsYSD 63 "Init" ;
VAL_ 2331595785 NR_FR_Object_02_DynamicState 0 "moving" 1 "stationary" 2 "stopped" 3 "Init" ;
VAL_ 2331595785 NR_FR_Object_02_YawAngle 4095 "Init" ;
VAL_ 2331595785 NR_FR_Object_02_YawAngleSD 511 "Init" ;
VAL_ 2331595785 NR_FR_Object_02_Width 255 "Init" ;
VAL_ 2331595785 NR_FR_Object_02_WidthSD 127 "Init" ;
VAL_ 2331595785 NR_FR_Object_02_Length 1023 "Init" ;
VAL_ 2331595785 NR_FR_Object_02_LengthSD 127 "Init" ;
VAL_ 2331595785 NR_FR_Object_02_Class 0 "unknown" 1 "reserved" 2 "reserved" 3 "pedestrian" 4 "reserved" 5 "bicycle" 6 "motorcycle" 7 "car" 8 "reserved" 9 "truck" 10 "reserved" 11 "reserved" 12 "reserved" 13 "reserved" 15 "Init" ;
VAL_ 2331595785 NR_FR_Object_02_ClassPlausib 15 "Init" ;
VAL_ 2331595785 NR_FR_Object_02_ExistProb 127 "Init" ;
VAL_ 2331595785 NR_FR_Object_02_Age 127 "Init" ;
VAL_ 2331595785 NR_FR_Object_02_YawRateAbs 4095 "Init" ;
VAL_ 2331595785 NR_FR_Object_02_YawRateAbsSD 63 "Init" ;
VAL_ 2331595785 NR_FR_Object_02_MeasurementState 0 "predicted" 1 "measured" ;
VAL_ 2331595786 NR_FR_Object_03_ID 0 "No_object" 255 "Init" ;
VAL_ 2331595786 NR_FR_Object_03_ReferencePoint 0 "unknown" 1 "front_left" 2 "front_center" 3 "front_right" 4 "right_center" 5 "rear_right" 6 "rear_center" 7 "rear_left" 8 "left_center" 9 "object_center" 10 "any_side_center" 15 "Init" ;
VAL_ 2331595786 NR_FR_Object_03_PosX 16383 "Init" ;
VAL_ 2331595786 NR_FR_Object_03_PosXSD 255 "Init" ;
VAL_ 2331595786 NR_FR_Object_03_PosY 8191 "Init" ;
VAL_ 2331595786 NR_FR_Object_03_PosYSD 255 "Init" ;
VAL_ 2331595786 NR_FR_Object_03_vAbsX 4095 "Init" ;
VAL_ 2331595786 NR_FR_Object_03_vAbsXSD 63 "Init" ;
VAL_ 2331595786 NR_FR_Object_03_vAbsY 4095 "Init" ;
VAL_ 2331595786 NR_FR_Object_03_vAbsYSD 63 "Init" ;
VAL_ 2331595786 NR_FR_Object_03_aAbsX 511 "Init" ;
VAL_ 2331595786 NR_FR_Object_03_aAbsXSD 63 "Init" ;
VAL_ 2331595786 NR_FR_Object_03_aAbsY 511 "Init" ;
VAL_ 2331595786 NR_FR_Object_03_aAbsYSD 63 "Init" ;
VAL_ 2331595786 NR_FR_Object_03_DynamicState 0 "moving" 1 "stationary" 2 "stopped" 3 "Init" ;
VAL_ 2331595786 NR_FR_Object_03_YawAngle 4095 "Init" ;
VAL_ 2331595786 NR_FR_Object_03_YawAngleSD 511 "Init" ;
VAL_ 2331595786 NR_FR_Object_03_Width 255 "Init" ;
VAL_ 2331595786 NR_FR_Object_03_WidthSD 127 "Init" ;
VAL_ 2331595786 NR_FR_Object_03_Length 1023 "Init" ;
VAL_ 2331595786 NR_FR_Object_03_LengthSD 127 "Init" ;
VAL_ 2331595786 NR_FR_Object_03_Class 0 "unknown" 1 "reserved" 2 "reserved" 3 "pedestrian" 4 "reserved" 5 "bicycle" 6 "motorcycle" 7 "car" 8 "reserved" 9 "truck" 10 "reserved" 11 "reserved" 12 "reserved" 13 "reserved" 15 "Init" ;
VAL_ 2331595786 NR_FR_Object_03_ClassPlausib 15 "Init" ;
VAL_ 2331595786 NR_FR_Object_03_ExistProb 127 "Init" ;
VAL_ 2331595786 NR_FR_Object_03_Age 127 "Init" ;
VAL_ 2331595786 NR_FR_Object_03_YawRateAbs 4095 "Init" ;
VAL_ 2331595786 NR_FR_Object_03_YawRateAbsSD 63 "Init" ;
VAL_ 2331595786 NR_FR_Object_03_MeasurementState 0 "predicted" 1 "measured" ;
VAL_ 2331595786 NR_FR_Object_04_ID 0 "No_object" 255 "Init" ;
VAL_ 2331595786 NR_FR_Object_04_ReferencePoint 0 "unknown" 1 "front_left" 2 "front_center" 3 "front_right" 4 "right_center" 5 "rear_right" 6 "rear_center" 7 "rear_left" 8 "left_center" 9 "object_center" 10 "any_side_center" 15 "Init" ;
VAL_ 2331595786 NR_FR_Object_04_PosX 16383 "Init" ;
VAL_ 2331595786 NR_FR_Object_04_PosXSD 255 "Init" ;
VAL_ 2331595786 NR_FR_Object_04_PosY 8191 "Init" ;
VAL_ 2331595786 NR_FR_Object_04_PosYSD 255 "Init" ;
VAL_ 2331595786 NR_FR_Object_04_vAbsX 4095 "Init" ;
VAL_ 2331595786 NR_FR_Object_04_vAbsXSD 63 "Init" ;
VAL_ 2331595786 NR_FR_Object_04_vAbsY 4095 "Init" ;
VAL_ 2331595786 NR_FR_Object_04_vAbsYSD 63 "Init" ;
VAL_ 2331595786 NR_FR_Object_04_aAbsX 511 "Init" ;
VAL_ 2331595786 NR_FR_Object_04_aAbsXSD 63 "Init" ;
VAL_ 2331595786 NR_FR_Object_04_aAbsY 511 "Init" ;
VAL_ 2331595786 NR_FR_Object_04_aAbsYSD 63 "Init" ;
VAL_ 2331595786 NR_FR_Object_04_DynamicState 0 "moving" 1 "stationary" 2 "stopped" 3 "Init" ;
VAL_ 2331595786 NR_FR_Object_04_YawAngle 4095 "Init" ;
VAL_ 2331595786 NR_FR_Object_04_YawAngleSD 511 "Init" ;
VAL_ 2331595786 NR_FR_Object_04_Width 255 "Init" ;
VAL_ 2331595786 NR_FR_Object_04_WidthSD 127 "Init" ;
VAL_ 2331595786 NR_FR_Object_04_Length 1023 "Init" ;
VAL_ 2331595786 NR_FR_Object_04_LengthSD 127 "Init" ;
VAL_ 2331595786 NR_FR_Object_04_Class 0 "unknown" 1 "reserved" 2 "reserved" 3 "pedestrian" 4 "reserved" 5 "bicycle" 6 "motorcycle" 7 "car" 8 "reserved" 9 "truck" 10 "reserved" 11 "reserved" 12 "reserved" 13 "reserved" 15 "Init" ;
VAL_ 2331595786 NR_FR_Object_04_ClassPlausib 15 "Init" ;
VAL_ 2331595786 NR_FR_Object_04_ExistProb 127 "Init" ;
VAL_ 2331595786 NR_FR_Object_04_Age 127 "Init" ;
VAL_ 2331595786 NR_FR_Object_04_YawRateAbs 4095 "Init" ;
VAL_ 2331595786 NR_FR_Object_04_YawRateAbsSD 63 "Init" ;
VAL_ 2331595786 NR_FR_Object_04_MeasurementState 0 "predicted" 1 "measured" ;
VAL_ 2331595787 NR_FR_Object_05_ID 0 "No_object" 255 "Init" ;
VAL_ 2331595787 NR_FR_Object_05_ReferencePoint 0 "unknown" 1 "front_left" 2 "front_center" 3 "front_right" 4 "right_center" 5 "rear_right" 6 "rear_center" 7 "rear_left" 8 "left_center" 9 "object_center" 10 "any_side_center" 15 "Init" ;
VAL_ 2331595787 NR_FR_Object_05_PosX 16383 "Init" ;
VAL_ 2331595787 NR_FR_Object_05_PosXSD 255 "Init" ;
VAL_ 2331595787 NR_FR_Object_05_PosY 8191 "Init" ;
VAL_ 2331595787 NR_FR_Object_05_PosYSD 255 "Init" ;
VAL_ 2331595787 NR_FR_Object_05_vAbsX 4095 "Init" ;
VAL_ 2331595787 NR_FR_Object_05_vAbsXSD 63 "Init" ;
VAL_ 2331595787 NR_FR_Object_05_vAbsY 4095 "Init" ;
VAL_ 2331595787 NR_FR_Object_05_vAbsYSD 63 "Init" ;
VAL_ 2331595787 NR_FR_Object_05_aAbsX 511 "Init" ;
VAL_ 2331595787 NR_FR_Object_05_aAbsXSD 63 "Init" ;
VAL_ 2331595787 NR_FR_Object_05_aAbsY 511 "Init" ;
VAL_ 2331595787 NR_FR_Object_05_aAbsYSD 63 "Init" ;
VAL_ 2331595787 NR_FR_Object_05_DynamicState 0 "moving" 1 "stationary" 2 "stopped" 3 "Init" ;
VAL_ 2331595787 NR_FR_Object_05_YawAngle 4095 "Init" ;
VAL_ 2331595787 NR_FR_Object_05_YawAngleSD 511 "Init" ;
VAL_ 2331595787 NR_FR_Object_05_Width 255 "Init" ;
VAL_ 2331595787 NR_FR_Object_05_WidthSD 127 "Init" ;
VAL_ 2331595787 NR_FR_Object_05_Length 1023 "Init" ;
VAL_ 2331595787 NR_FR_Object_05_LengthSD 127 "Init" ;
VAL_ 2331595787 NR_FR_Object_05_Class 0 "unknown" 1 "reserved" 2 "reserved" 3 "pedestrian" 4 "reserved" 5 "bicycle" 6 "motorcycle" 7 "car" 8 "reserved" 9 "truck" 10 "reserved" 11 "reserved" 12 "reserved" 13 "reserved" 15 "Init" ;
VAL_ 2331595787 NR_FR_Object_05_ClassPlausib 15 "Init" ;
VAL_ 2331595787 NR_FR_Object_05_ExistProb 127 "Init" ;
VAL_ 2331595787 NR_FR_Object_05_Age 127 "Init" ;
VAL_ 2331595787 NR_FR_Object_05_YawRateAbs 4095 "Init" ;
VAL_ 2331595787 NR_FR_Object_05_YawRateAbsSD 63 "Init" ;
VAL_ 2331595787 NR_FR_Object_05_MeasurementState 0 "predicted" 1 "measured" ;
VAL_ 2331595787 NR_FR_Object_06_ID 0 "No_object" 255 "Init" ;
VAL_ 2331595787 NR_FR_Object_06_ReferencePoint 0 "unknown" 1 "front_left" 2 "front_center" 3 "front_right" 4 "right_center" 5 "rear_right" 6 "rear_center" 7 "rear_left" 8 "left_center" 9 "object_center" 10 "any_side_center" 15 "Init" ;
VAL_ 2331595787 NR_FR_Object_06_PosX 16383 "Init" ;
VAL_ 2331595787 NR_FR_Object_06_PosXSD 255 "Init" ;
VAL_ 2331595787 NR_FR_Object_06_PosY 8191 "Init" ;
VAL_ 2331595787 NR_FR_Object_06_PosYSD 255 "Init" ;
VAL_ 2331595787 NR_FR_Object_06_vAbsX 4095 "Init" ;
VAL_ 2331595787 NR_FR_Object_06_vAbsXSD 63 "Init" ;
VAL_ 2331595787 NR_FR_Object_06_vAbsY 4095 "Init" ;
VAL_ 2331595787 NR_FR_Object_06_vAbsYSD 63 "Init" ;
VAL_ 2331595787 NR_FR_Object_06_aAbsX 511 "Init" ;
VAL_ 2331595787 NR_FR_Object_06_aAbsXSD 63 "Init" ;
VAL_ 2331595787 NR_FR_Object_06_aAbsY 511 "Init" ;
VAL_ 2331595787 NR_FR_Object_06_aAbsYSD 63 "Init" ;
VAL_ 2331595787 NR_FR_Object_06_DynamicState 0 "moving" 1 "stationary" 2 "stopped" 3 "Init" ;
VAL_ 2331595787 NR_FR_Object_06_YawAngle 4095 "Init" ;
VAL_ 2331595787 NR_FR_Object_06_YawAngleSD 511 "Init" ;
VAL_ 2331595787 NR_FR_Object_06_Width 255 "Init" ;
VAL_ 2331595787 NR_FR_Object_06_WidthSD 127 "Init" ;
VAL_ 2331595787 NR_FR_Object_06_Length 1023 "Init" ;
VAL_ 2331595787 NR_FR_Object_06_LengthSD 127 "Init" ;
VAL_ 2331595787 NR_FR_Object_06_Class 0 "unknown" 1 "reserved" 2 "reserved" 3 "pedestrian" 4 "reserved" 5 "bicycle" 6 "motorcycle" 7 "car" 8 "reserved" 9 "truck" 10 "reserved" 11 "reserved" 12 "reserved" 13 "reserved" 15 "Init" ;
VAL_ 2331595787 NR_FR_Object_06_ClassPlausib 15 "Init" ;
VAL_ 2331595787 NR_FR_Object_06_ExistProb 127 "Init" ;
VAL_ 2331595787 NR_FR_Object_06_Age 127 "Init" ;
VAL_ 2331595787 NR_FR_Object_06_YawRateAbs 4095 "Init" ;
VAL_ 2331595787 NR_FR_Object_06_YawRateAbsSD 63 "Init" ;
VAL_ 2331595787 NR_FR_Object_06_MeasurementState 0 "predicted" 1 "measured" ;
VAL_ 2331595788 NR_FR_Object_07_ID 0 "No_object" 255 "Init" ;
VAL_ 2331595788 NR_FR_Object_07_ReferencePoint 0 "unknown" 1 "front_left" 2 "front_center" 3 "front_right" 4 "right_center" 5 "rear_right" 6 "rear_center" 7 "rear_left" 8 "left_center" 9 "object_center" 10 "any_side_center" 15 "Init" ;
VAL_ 2331595788 NR_FR_Object_07_PosX 16383 "Init" ;
VAL_ 2331595788 NR_FR_Object_07_PosXSD 255 "Init" ;
VAL_ 2331595788 NR_FR_Object_07_PosY 8191 "Init" ;
VAL_ 2331595788 NR_FR_Object_07_PosYSD 255 "Init" ;
VAL_ 2331595788 NR_FR_Object_07_vAbsX 4095 "Init" ;
VAL_ 2331595788 NR_FR_Object_07_vAbsXSD 63 "Init" ;
VAL_ 2331595788 NR_FR_Object_07_vAbsY 4095 "Init" ;
VAL_ 2331595788 NR_FR_Object_07_vAbsYSD 63 "Init" ;
VAL_ 2331595788 NR_FR_Object_07_aAbsX 511 "Init" ;
VAL_ 2331595788 NR_FR_Object_07_aAbsXSD 63 "Init" ;
VAL_ 2331595788 NR_FR_Object_07_aAbsY 511 "Init" ;
VAL_ 2331595788 NR_FR_Object_07_aAbsYSD 63 "Init" ;
VAL_ 2331595788 NR_FR_Object_07_DynamicState 0 "moving" 1 "stationary" 2 "stopped" 3 "Init" ;
VAL_ 2331595788 NR_FR_Object_07_YawAngle 4095 "Init" ;
VAL_ 2331595788 NR_FR_Object_07_YawAngleSD 511 "Init" ;
VAL_ 2331595788 NR_FR_Object_07_Width 255 "Init" ;
VAL_ 2331595788 NR_FR_Object_07_WidthSD 127 "Init" ;
VAL_ 2331595788 NR_FR_Object_07_Length 1023 "Init" ;
VAL_ 2331595788 NR_FR_Object_07_LengthSD 127 "Init" ;
VAL_ 2331595788 NR_FR_Object_07_Class 0 "unknown" 1 "reserved" 2 "reserved" 3 "pedestrian" 4 "reserved" 5 "bicycle" 6 "motorcycle" 7 "car" 8 "reserved" 9 "truck" 10 "reserved" 11 "reserved" 12 "reserved" 13 "reserved" 15 "Init" ;
VAL_ 2331595788 NR_FR_Object_07_ClassPlausib 15 "Init" ;
VAL_ 2331595788 NR_FR_Object_07_ExistProb 127 "Init" ;
VAL_ 2331595788 NR_FR_Object_07_Age 127 "Init" ;
VAL_ 2331595788 NR_FR_Object_07_YawRateAbs 4095 "Init" ;
VAL_ 2331595788 NR_FR_Object_07_YawRateAbsSD 63 "Init" ;
VAL_ 2331595788 NR_FR_Object_07_MeasurementState 0 "predicted" 1 "measured" ;
VAL_ 2331595788 NR_FR_Object_08_ID 0 "No_object" 255 "Init" ;
VAL_ 2331595788 NR_FR_Object_08_ReferencePoint 0 "unknown" 1 "front_left" 2 "front_center" 3 "front_right" 4 "right_center" 5 "rear_right" 6 "rear_center" 7 "rear_left" 8 "left_center" 9 "object_center" 10 "any_side_center" 15 "Init" ;
VAL_ 2331595788 NR_FR_Object_08_PosX 16383 "Init" ;
VAL_ 2331595788 NR_FR_Object_08_PosXSD 255 "Init" ;
VAL_ 2331595788 NR_FR_Object_08_PosY 8191 "Init" ;
VAL_ 2331595788 NR_FR_Object_08_PosYSD 255 "Init" ;
VAL_ 2331595788 NR_FR_Object_08_vAbsX 4095 "Init" ;
VAL_ 2331595788 NR_FR_Object_08_vAbsXSD 63 "Init" ;
VAL_ 2331595788 NR_FR_Object_08_vAbsY 4095 "Init" ;
VAL_ 2331595788 NR_FR_Object_08_vAbsYSD 63 "Init" ;
VAL_ 2331595788 NR_FR_Object_08_aAbsX 511 "Init" ;
VAL_ 2331595788 NR_FR_Object_08_aAbsXSD 63 "Init" ;
VAL_ 2331595788 NR_FR_Object_08_aAbsY 511 "Init" ;
VAL_ 2331595788 NR_FR_Object_08_aAbsYSD 63 "Init" ;
VAL_ 2331595788 NR_FR_Object_08_DynamicState 0 "moving" 1 "stationary" 2 "stopped" 3 "Init" ;
VAL_ 2331595788 NR_FR_Object_08_YawAngle 4095 "Init" ;
VAL_ 2331595788 NR_FR_Object_08_YawAngleSD 511 "Init" ;
VAL_ 2331595788 NR_FR_Object_08_Width 255 "Init" ;
VAL_ 2331595788 NR_FR_Object_08_WidthSD 127 "Init" ;
VAL_ 2331595788 NR_FR_Object_08_Length 1023 "Init" ;
VAL_ 2331595788 NR_FR_Object_08_LengthSD 127 "Init" ;
VAL_ 2331595788 NR_FR_Object_08_Class 0 "unknown" 1 "reserved" 2 "reserved" 3 "pedestrian" 4 "reserved" 5 "bicycle" 6 "motorcycle" 7 "car" 8 "reserved" 9 "truck" 10 "reserved" 11 "reserved" 12 "reserved" 13 "reserved" 15 "Init" ;
VAL_ 2331595788 NR_FR_Object_08_ClassPlausib 15 "Init" ;
VAL_ 2331595788 NR_FR_Object_08_ExistProb 127 "Init" ;
VAL_ 2331595788 NR_FR_Object_08_Age 127 "Init" ;
VAL_ 2331595788 NR_FR_Object_08_YawRateAbs 4095 "Init" ;
VAL_ 2331595788 NR_FR_Object_08_YawRateAbsSD 63 "Init" ;
VAL_ 2331595788 NR_FR_Object_08_MeasurementState 0 "predicted" 1 "measured" ;
